VERSION ""

NS_ :

BS_:

BU_: MPAD CVADAS ADCAM ORC EVCU2 EPS ECM CVPAM CADM BSM2 BSM

BO_ 1456 ADAS_FD_HMI: 32 ADCAM
 SG_ RR_Chime_RqSts : 99|1@0+ (1,0) [0|1] "" ORC
 SG_ MessageCounter_ADAS_FD_HMI : 179|4@0+ (1,0) [0|15] "-"  EVCU2,BSM2,BSM,ORC,EPS,ECM
 SG_ LR_Chime_RqSts : 100|1@0+ (1,0) [0|1] "" ORC
 SG_ CRC_ADAS_FD_HMI : 191|8@0+ (1,0) [0|255] "-"  EVCU2,BSM2,BSM,ORC,EPS,ECM
 SG_ Chime_Priority : 91|3@0+ (1,0) [0|4] "-"  Vector__XXX
 SG_ BSS_SRV_RQSts : 88|1@0+ (1,0) [0|1] "" ORC
 SG_ BSS_Blind_RQSts : 101|1@0+ (1,0) [0|1] "" ORC
 SG_ BSS_CFG_STATSts : 103|2@0+ (1,0) [0|2] "" ORC
 SG_ SVI_Request : 31|2@0+ (1,0) [0|3] "-"  Vector__XXX
 SG_ Set_Speed_MPH : 15|8@0+ (1,0) [0|255] "mph"  EVCU2,ECM
 SG_ Set_Speed_KPH : 7|8@0+ (1,0) [0|255] "kph"  EVCU2,ORC,ECM
 SG_ RF_Chime_RqSts : 95|1@0+ (1,0) [0|1] "-"  ORC
 SG_ PEB_Setting_Avail : 78|1@0+ (1,0) [0|1] "-"  Vector__XXX
 SG_ NCC_FailSts : 82|1@0+ (1,0) [0|1] "-"  BSM,ORC
 SG_ LKA_Status : 23|1@0+ (1,0) [0|1] "-"  ORC
 SG_ LKA_FailSts : 84|1@0+ (1,0) [0|1] "-"  ORC
 SG_ LKA_Blind : 86|1@0+ (1,0) [0|1] "-"  ORC
 SG_ LF_Chime_RqSts : 93|1@0+ (1,0) [0|1] "-"  ORC
 SG_ Lane_DisplaySts_Right : 60|3@0+ (1,0) [0|7] "-"  ORC
 SG_ Lane_DisplaySts_Left : 71|3@0+ (1,0) [0|7] "-"  ORC
 SG_ ICA_Blind : 55|1@0+ (1,0) [0|1] "-"  Vector__XXX
 SG_ HAS_TurnSignalRequest : 111|2@0+ (1,0) [0|2] "" Vector__XXX
 SG_ HAS_TelltaleSts : 54|3@0+ (1,0) [0|6] "-"  ORC
 SG_ HAS_FailSts : 80|1@0+ (1,0) [0|1] "-"  ORC
 SG_ HAS_Escalation_Sts : 117|4@0+ (1,0) [0|8] "" Vector__XXX
 SG_ HAS_Blind : 85|1@0+ (1,0) [0|1] "-"  ORC
 SG_ FCW_Setting_Avail : 77|1@0+ (1,0) [0|1] "-"  Vector__XXX
 SG_ DisplaySts_Veh : 63|3@0+ (1,0) [0|7] "-"  Vector__XXX
 SG_ DisplaySts_OFF : 68|3@0+ (1,0) [0|7] "-"  Vector__XXX
 SG_ DisplaySts_Curve : 109|2@0+ (1,0) [0|2] "" Vector__XXX
 SG_ DisplaySts_ACC : 51|4@0+ (1,0) [0|15] "-"  ORC
 SG_ DDD_FailSts : 96|1@0+ (1,0) [0|1] "" Vector__XXX
 SG_ DDD_DispPopupSts : 39|2@0+ (1,0) [0|2] "-"  ORC
 SG_ Chime_TypSts : 47|4@0+ (1,0) [0|15] "-"  ORC
 SG_ Chime_RepRate : 43|4@0+ (1,0) [0|15] "Hz"  Vector__XXX
 SG_ BlindSpotRightWarn : 171|2@0+ (1,0) [0|2] "" ORC
 SG_ BlindSpotLeftWarn : 105|2@0+ (1,0) [0|2] "" ORC
 SG_ AEB_Limited : 72|1@0+ (1,0) [0|1] "-"  BSM,ORC
 SG_ AEB_Limit_Fail : 74|1@0+ (1,0) [0|1] "-"  ORC
 SG_ AEB_FailSts : 83|1@0+ (1,0) [0|1] "-"  BSM2,BSM,ORC
 SG_ AEB_DispPopupSts : 37|6@0+ (1,0) [0|63] "-"  ORC
 SG_ AEB_Blind : 76|1@0+ (1,0) [0|1] "-"  ORC
 SG_ ACC_Set_Speed_Strike : 92|1@0+ (1,0) [0|1] "-"  Vector__XXX
 SG_ ACC_Limited : 87|1@0+ (1,0) [0|1] "-"  ORC
 SG_ ACC_Limit_Fail : 73|1@0+ (1,0) [0|1] "-"  ORC
 SG_ ACC_FailSts : 81|1@0+ (1,0) [0|1] "-"  EVCU2,BSM,ORC
 SG_ ACC_DispPopupSts : 22|7@0+ (1,0) [0|127] "-"  ORC
 SG_ ACC_Blind : 75|1@0+ (1,0) [0|1] "-"  EVCU2,BSM,ORC
 SG_ Driver_Model : 107|2@0+ (1,0) [0|3] "" ORC
 SG_ Lane_DispPopupSts : 127|8@0+ (1,0) [0|255] "-"  ORC
 SG_ SVI_Request_ext : 29|3@0+ (1,0) [0|7] "-"  Vector__XXX
 SG_ DM_Camera_Block : 112|1@0+ (1,0) [0|1] "-"  Vector__XXX
 SG_ HAS_TelltaleSts_ext : 157|3@0+ (1,0) [0|7] "" Vector__XXX
 SG_ DisplaySts_Route : 154|3@0+ (1,0) [0|7] "" Vector__XXX

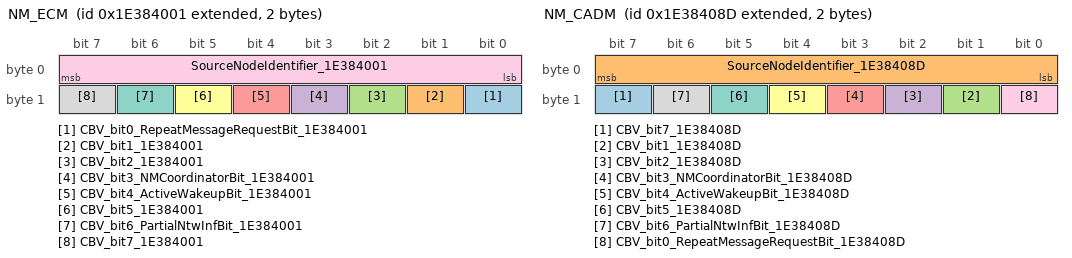
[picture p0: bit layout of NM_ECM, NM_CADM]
BO_ 2654486529 NM_ECM: 2 ECM
 SG_ CBV_bit0_RepeatMessageRequestBit_1E384001 : 8|1@0+ (1,0) [0|1] "" CVADAS,ADCAM,EVCU2,BSM2,CVPAM,CADM,BSM,ORC,EPS
 SG_ CBV_bit1_1E384001 : 9|1@0+ (1,0) [0|1] "" CVADAS,ADCAM,EVCU2,BSM2,CVPAM,CADM,BSM,ORC,EPS
 SG_ CBV_bit2_1E384001 : 10|1@0+ (1,0) [0|1] "" CVADAS,ADCAM,EVCU2,BSM2,CVPAM,CADM,BSM,ORC,EPS
 SG_ CBV_bit3_NMCoordinatorBit_1E384001 : 11|1@0+ (1,0) [0|1] "" CVADAS,ADCAM,EVCU2,BSM2,CVPAM,CADM,BSM,ORC,EPS
 SG_ CBV_bit4_ActiveWakeupBit_1E384001 : 12|1@0+ (1,0) [0|1] "" CVADAS,ADCAM,EVCU2,BSM2,CVPAM,CADM,BSM,ORC,EPS
 SG_ CBV_bit5_1E384001 : 13|1@0+ (1,0) [0|1] "" CVADAS,ADCAM,EVCU2,BSM2,CVPAM,CADM,BSM,ORC,EPS
 SG_ CBV_bit6_PartialNtwInfBit_1E384001 : 14|1@0+ (1,0) [0|1] "" CVADAS,ADCAM,EVCU2,BSM2,CVPAM,CADM,BSM,ORC,EPS
 SG_ CBV_bit7_1E384001 : 15|1@0+ (1,0) [0|1] "" CVADAS,ADCAM,EVCU2,BSM2,CVPAM,CADM,BSM,ORC,EPS
 SG_ SourceNodeIdentifier_1E384001 : 7|8@0+ (1,0) [0|255] "-"  CVADAS,ADCAM,EVCU2,BSM2,CVPAM,CADM,BSM,ORC,EPS

BO_ 2654486669 NM_CADM: 2 CADM
 SG_ CBV_bit7_1E38408D : 15|1@0+ (1,0) [0|1] "" CVADAS,EVCU2,BSM2,CVPAM,BSM,ORC,EPS,ECM
 SG_ SourceNodeIdentifier_1E38408D : 7|8@0+ (1,0) [0|255] "-"  CVADAS,EVCU2,BSM2,CVPAM,BSM,ORC,EPS,ECM
 SG_ CBV_bit1_1E38408D : 9|1@0+ (1,0) [0|1] "" CVADAS,EVCU2,BSM2,CVPAM,BSM,ORC,EPS,ECM
 SG_ CBV_bit2_1E38408D : 10|1@0+ (1,0) [0|1] "" CVADAS,EVCU2,BSM2,CVPAM,BSM,ORC,EPS,ECM
 SG_ CBV_bit3_NMCoordinatorBit_1E38408D : 11|1@0+ (1,0) [0|1] "" CVADAS,EVCU2,BSM2,CVPAM,BSM,ORC,EPS,ECM
 SG_ CBV_bit4_ActiveWakeupBit_1E38408D : 12|1@0+ (1,0) [0|1] "" CVADAS,EVCU2,BSM2,CVPAM,BSM,ORC,EPS,ECM
 SG_ CBV_bit5_1E38408D : 13|1@0+ (1,0) [0|1] "" CVADAS,EVCU2,BSM2,CVPAM,BSM,ORC,EPS,ECM
 SG_ CBV_bit6_PartialNtwInfBit_1E38408D : 14|1@0+ (1,0) [0|1] "" CVADAS,EVCU2,BSM2,CVPAM,BSM,ORC,EPS,ECM
 SG_ CBV_bit0_RepeatMessageRequestBit_1E38408D : 8|1@0+ (1,0) [0|1] "" CVADAS,EVCU2,BSM2,CVPAM,BSM,ORC,EPS,ECM

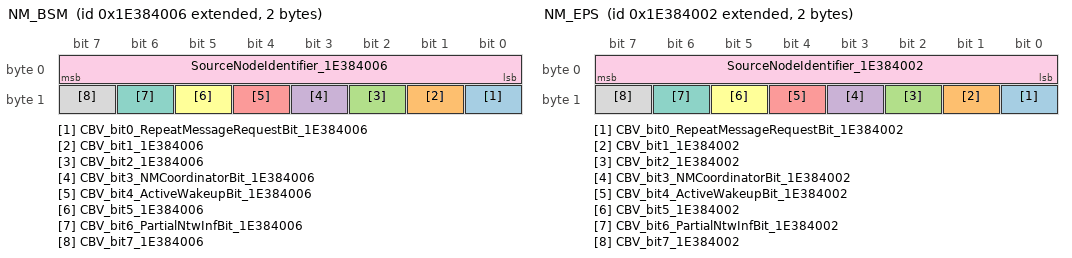
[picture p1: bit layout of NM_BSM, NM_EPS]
BO_ 2654486534 NM_BSM: 2 BSM
 SG_ CBV_bit0_RepeatMessageRequestBit_1E384006 : 8|1@0+ (1,0) [0|1] "" CVPAM,CADM,ORC,EPS,CVADAS,ADCAM,MPAD,EVCU2,BSM2,ECM
 SG_ CBV_bit1_1E384006 : 9|1@0+ (1,0) [0|1] "" CVPAM,CADM,ORC,EPS,CVADAS,ADCAM,MPAD,EVCU2,BSM2,ECM
 SG_ CBV_bit2_1E384006 : 10|1@0+ (1,0) [0|1] "" CVPAM,CADM,ORC,EPS,CVADAS,ADCAM,MPAD,EVCU2,BSM2,ECM
 SG_ CBV_bit3_NMCoordinatorBit_1E384006 : 11|1@0+ (1,0) [0|1] "" CVPAM,CADM,ORC,EPS,CVADAS,ADCAM,MPAD,EVCU2,BSM2,ECM
 SG_ CBV_bit4_ActiveWakeupBit_1E384006 : 12|1@0+ (1,0) [0|1] "" CVPAM,CADM,ORC,EPS,CVADAS,ADCAM,MPAD,EVCU2,BSM2,ECM
 SG_ CBV_bit5_1E384006 : 13|1@0+ (1,0) [0|1] "" CVPAM,CADM,ORC,EPS,CVADAS,ADCAM,MPAD,EVCU2,BSM2,ECM
 SG_ CBV_bit6_PartialNtwInfBit_1E384006 : 14|1@0+ (1,0) [0|1] "" CVPAM,CADM,ORC,EPS,CVADAS,ADCAM,MPAD,EVCU2,BSM2,ECM
 SG_ CBV_bit7_1E384006 : 15|1@0+ (1,0) [0|1] "" CVPAM,CADM,ORC,EPS,CVADAS,ADCAM,MPAD,EVCU2,BSM2,ECM
 SG_ SourceNodeIdentifier_1E384006 : 7|8@0+ (1,0) [0|255] "-"  CVPAM,CADM,ORC,EPS,CVADAS,ADCAM,MPAD,EVCU2,BSM2,ECM

BO_ 262 ENGINE_FD_2: 64 ECM
 SG_ PowertrainPrplsnActv : 181|1@0+ (1,0) [0|1] "" ADCAM,CADM,BSM
 SG_ MessageCounter_ENGINE2 : 435|4@0+ (1,0) [0|15] "-"  CVADAS,ADCAM,CVPAM,CADM,BSM,EPS
 SG_ LV12PwrFreeRq_W : 176|1@0+ (1,0) [0|1] "-"  Vector__XXX
 SG_ GasPedalPositionFailSts_W : 169|1@0+ (1,0) [0|1] "-"  ADCAM,CADM,BSM
 SG_ GasPedalPosition_W : 143|8@0+ (0.392,0) [0|99.568] "%"  ADCAM,BSM
 SG_ ESS_ENG_ST_W : 175|4@0+ (1,0) [0|15] "-"  CVADAS,ADCAM,CADM,BSM,EPS
 SG_ EngineSts_W : 87|2@0+ (1,0) [0|3] "-"  CVADAS,ADCAM,CVPAM,CADM,BSM,EPS
 SG_ EngineSpeed_W : 21|14@0+ (1,0) [0|16382] "1/min"  ADCAM,CADM,BSM,EPS
 SG_ ECM_LHOM_W : 188|1@0+ (1,0) [0|1] "-"  ADCAM,CADM
 SG_ CRC_ENGINE2 : 447|8@0+ (1,0) [0|255] "-"  CVADAS,ADCAM,CVPAM,CADM,BSM,EPS

BO_ 258 BRAKE_FD_2: 64 BSM
 SG_ YawRateFailSts_BSM : 87|1@0+ (1,0) [0|1] "-"  CVADAS,ADCAM,MPAD,CVPAM,CADM,EPS
 SG_ YawRate_BSM : 67|12@0+ (0.08,-163.84) [-163.84|163.68] "deg/s"  CVADAS,ADCAM,MPAD,CVPAM,CADM,EPS
 SG_ VehicleSpeedVSOSig : 4|13@0+ (0.0625,0) [0|511.875] "Km/h"  CVADAS,ADCAM,MPAD,EVCU2,BSM2,CVPAM,CADM,EPS,ECM
 SG_ Slope : 135|8@0+ (1,-100) [-100|154] "%"  CVADAS,MPAD,EVCU2,CVPAM,CADM
 SG_ PrefillActive : 86|1@0+ (1,0) [0|1] "-"  ADCAM,MPAD,CADM
 SG_ MessageCounter_BRAKE2 : 435|4@0+ (1,0) [0|15] "-"  CVADAS,ADCAM,EVCU2,BSM2,CVPAM,CADM,EPS,ECM
 SG_ LongAccelerationFailSts_BSM : 69|1@0+ (1,0) [0|1] "-"  CVADAS,ADCAM,MPAD,CVPAM,CADM
 SG_ LongAcceleration_BSM : 35|12@0+ (0.02,-40.96) [-40.96|40.92] "m/s^2"  CVADAS,ADCAM,MPAD,CVPAM,CADM,EPS
 SG_ LatAccelerationFailSts_BSM : 68|1@0+ (1,0) [0|1] "-"  CVADAS,ADCAM,MPAD,CVPAM,CADM
 SG_ LatAcceleration_BSM : 19|12@0+ (0.02,-40.96) [-40.96|40.92] "m/s^2"  CVADAS,ADCAM,MPAD,CVPAM,CADM,EPS
 SG_ InternalError_BSM : 191|1@0+ (1,0) [0|1] "-"  ADCAM,MPAD,CADM
 SG_ ESP_Sys_Stat : 71|2@0+ (1,0) [0|3] "-"  Vector__XXX
 SG_ ESCActive : 84|1@0+ (1,0) [0|1] "-"  MPAD,EVCU2,CVPAM,CADM
 SG_ CRC_BRAKE2 : 447|8@0+ (1,0) [0|255] "-"  CVADAS,ADCAM,EVCU2,BSM2,CVPAM,CADM,EPS,ECM
 SG_ BrakePedalPressure : 386|11@0+ (0.1,0) [0|200] "bar"  EVCU2,ECM
 SG_ BrakeInterventionSts : 103|1@0+ (1,0) [0|1] "-"  ADCAM,MPAD,BSM2,CADM
 SG_ BrakeBoostStat : 439|4@0+ (1,0) [0|14] "-"  Vector__XXX
 SG_ BrakeBoostPressure : 370|11@0+ (0.1,0) [0|200] "bar"  EVCU2,ECM
 SG_ ABSActive : 83|1@0+ (1,0) [0|1] "-"  MPAD,EVCU2,CVPAM,CADM,ECM
 SG_ WheelRPM_FR : 295|16@0+ (0.001953125,0) [0|127.9961] "Rev/s"  MPAD,EVCU2,EPS
 SG_ WheelRPM_FL : 279|16@0+ (0.001953125,0) [0|127.9961] "Rev/s"  MPAD,EVCU2,EPS
 SG_ Brk_Stat : 343|2@0+ (1,0) [0|2] "-"  CVADAS,ADCAM,MPAD,EVCU2,CVPAM,CADM,ECM
 SG_ ParkingGearShiftReq_BSM : 22|3@0+ (1,0) [0|6] "" CVADAS,CVPAM
 SG_ ParkingInterventionSts : 7|2@0+ (1,0) [0|3] "" CVADAS,CVPAM
 SG_ BSM_ESASystemSts : 239|3@0+ (1,0) [0|6] "" CADM,EPS

BO_ 2654486530 NM_EPS: 2 EPS
 SG_ CBV_bit0_RepeatMessageRequestBit_1E384002 : 8|1@0+ (1,0) [0|1] "" CVADAS,ADCAM,MPAD,EVCU2,BSM2,CVPAM,CADM,BSM,ORC,ECM
 SG_ CBV_bit1_1E384002 : 9|1@0+ (1,0) [0|1] "" CVADAS,ADCAM,MPAD,EVCU2,BSM2,CVPAM,CADM,BSM,ORC,ECM
 SG_ CBV_bit2_1E384002 : 10|1@0+ (1,0) [0|1] "" CVADAS,ADCAM,MPAD,EVCU2,BSM2,CVPAM,CADM,BSM,ORC,ECM
 SG_ CBV_bit3_NMCoordinatorBit_1E384002 : 11|1@0+ (1,0) [0|1] "" CVADAS,ADCAM,MPAD,EVCU2,BSM2,CVPAM,CADM,BSM,ORC,ECM
 SG_ CBV_bit4_ActiveWakeupBit_1E384002 : 12|1@0+ (1,0) [0|1] "" CVADAS,ADCAM,MPAD,EVCU2,BSM2,CVPAM,CADM,BSM,ORC,ECM
 SG_ CBV_bit5_1E384002 : 13|1@0+ (1,0) [0|1] "" CVADAS,ADCAM,MPAD,EVCU2,BSM2,CVPAM,CADM,BSM,ORC,ECM
 SG_ CBV_bit6_PartialNtwInfBit_1E384002 : 14|1@0+ (1,0) [0|1] "" CVADAS,ADCAM,MPAD,EVCU2,BSM2,CVPAM,CADM,BSM,ORC,ECM
 SG_ CBV_bit7_1E384002 : 15|1@0+ (1,0) [0|1] "" CVADAS,ADCAM,MPAD,EVCU2,BSM2,CVPAM,CADM,BSM,ORC,ECM
 SG_ SourceNodeIdentifier_1E384002 : 7|8@0+ (1,0) [0|255] "-"  CVADAS,ADCAM,MPAD,EVCU2,BSM2,CVPAM,CADM,BSM,ORC,ECM

BO_ 524 BRAKE2_FD_2: 32 BSM2
 SG_ VehicleStandStillSts_B2 : 47|2@0+ (1,0) [0|2] "" ADCAM,MPAD,CADM,BSM
 SG_ BSM2_OpStat : 50|3@0+ (1,0) [0|5] "" ADCAM,MPAD,CADM,BSM
 SG_ Brake_OpStat_Sec : 53|3@0+ (1,0) [0|5] "" MPAD,CADM
 SG_ MessageCounter_BRAKE2_2 : 179|4@0+ (1,0) [0|15] "-"  MPAD,CADM,BSM,ORC
 SG_ CRC_BRAKE2_2 : 191|8@0+ (1,0) [0|255] "-"  MPAD,CADM,BSM,ORC
 SG_ BrkTrq_B2 : 6|15@0+ (3,0) [0|98301] "Nm"  ADCAM,MPAD,CADM
 SG_ BSM2_HEALTH_CHECK : 63|8@0+ (1,0) [0|255] "" BSM
 SG_ AEB_Type_Brk_B2 : 43|4@0+ (1,0) [0|15] "" ADCAM,MPAD,CADM

BO_ 257 BRAKE2_FD_1: 64 BSM2
 SG_ VehicleSpeedVSOSig_B2 : 36|13@0+ (0.0625,0) [0|511.875] "Km/h"  CVADAS,ADCAM,MPAD,CVPAM,CADM,EPS
 SG_ RHFWheelSpeed_B2 : 68|13@0+ (0.0625,0) [0|511.875] "Km/h"  ADCAM,MPAD,CADM
 SG_ RHF_FastPulseCounter_B2 : 95|8@0+ (1,0) [0|255] "pulse"  ADCAM,MPAD,CADM
 SG_ LHFWheelSpeed_B2 : 52|13@0+ (0.0625,0) [0|511.875] "Km/h"  ADCAM,MPAD,CADM
 SG_ LHF_FastPulseCounter_B2 : 87|8@0+ (1,0) [0|255] "pulse"  ADCAM,MPAD,CADM
 SG_ RHF_WheelSensorFailSts_B2 : 69|1@0+ (1,0) [0|1] "" ADCAM,MPAD,CADM
 SG_ RHF_Spin_B2 : 55|2@0+ (1,0) [0|3] "" ADCAM,MPAD,CADM
 SG_ MessageCounter_BRAKE2_1 : 435|4@0+ (1,0) [0|15] "-"  CVADAS,CADM,ORC,EPS
 SG_ LHF_WheelSensorFailSts_B2 : 53|1@0+ (1,0) [0|1] "" ADCAM,MPAD,CADM
 SG_ LHF_Spin_B2 : 39|2@0+ (1,0) [0|3] "" ADCAM,MPAD,CADM
 SG_ Inlet_Pressure_Pos : 98|2@0+ (1,0) [0|2] "" ADCAM,MPAD,CADM
 SG_ CRC_BRAKE2_1 : 447|8@0+ (1,0) [0|255] "-"  CVADAS,CADM,ORC,EPS
 SG_ Brk_Stat_B2 : 71|2@0+ (1,0) [0|2] "" ADCAM,MPAD,CADM
 SG_ ABSActive_B2 : 37|1@0+ (1,0) [0|1] "" MPAD,CADM
 SG_ Rear_Diff_BSM_RQ_B2 : 156|2@0+ (1,0) [0|2] "-"  Vector__XXX
 SG_ R_DIFF_TRQ_RQ_B2 : 151|9@0+ (10,0) [0|5100] "Nm"  Vector__XXX
 SG_ Ft_RrTrqCoupling_ModeRq_B2 : 158|2@0+ (1,0) [0|3] "-"  Vector__XXX
 SG_ Ft_RrAxleCoupling_TrqRq_B2 : 143|8@0+ (12,0) [0|3060] "Nm"  Vector__XXX

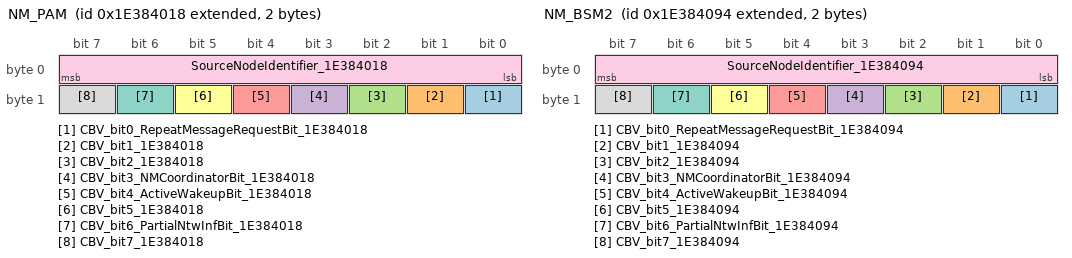
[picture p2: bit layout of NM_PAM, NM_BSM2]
BO_ 2654486552 NM_PAM: 2 CVADAS
 SG_ CBV_bit0_RepeatMessageRequestBit_1E384018 : 8|1@0+ (1,0) [0|1] "" ADCAM,MPAD,EVCU2,BSM2,CADM,BSM,ORC,EPS,ECM
 SG_ CBV_bit1_1E384018 : 9|1@0+ (1,0) [0|1] "" ADCAM,MPAD,EVCU2,BSM2,CADM,BSM,ORC,EPS,ECM
 SG_ CBV_bit2_1E384018 : 10|1@0+ (1,0) [0|1] "" ADCAM,MPAD,EVCU2,BSM2,CADM,BSM,ORC,EPS,ECM
 SG_ CBV_bit3_NMCoordinatorBit_1E384018 : 11|1@0+ (1,0) [0|1] "" ADCAM,MPAD,EVCU2,BSM2,CADM,BSM,ORC,EPS,ECM
 SG_ CBV_bit4_ActiveWakeupBit_1E384018 : 12|1@0+ (1,0) [0|1] "" ADCAM,MPAD,EVCU2,BSM2,CADM,BSM,ORC,EPS,ECM
 SG_ CBV_bit5_1E384018 : 13|1@0+ (1,0) [0|1] "" ADCAM,MPAD,EVCU2,BSM2,CADM,BSM,ORC,EPS,ECM
 SG_ CBV_bit6_PartialNtwInfBit_1E384018 : 14|1@0+ (1,0) [0|1] "" ADCAM,MPAD,EVCU2,BSM2,CADM,BSM,ORC,EPS,ECM
 SG_ CBV_bit7_1E384018 : 15|1@0+ (1,0) [0|1] "" ADCAM,MPAD,EVCU2,BSM2,CADM,BSM,ORC,EPS,ECM
 SG_ SourceNodeIdentifier_1E384018 : 7|8@0+ (1,0) [0|255] "-"  ADCAM,MPAD,EVCU2,BSM2,CADM,BSM,ORC,EPS,ECM

BO_ 2654486676 NM_BSM2: 2 BSM2
 SG_ CBV_bit0_RepeatMessageRequestBit_1E384094 : 8|1@0+ (1,0) [0|1] "" CVADAS,ADCAM,MPAD,EVCU2,CVPAM,CADM,BSM,ORC,EPS,ECM
 SG_ CBV_bit1_1E384094 : 9|1@0+ (1,0) [0|1] "" CVADAS,ADCAM,MPAD,EVCU2,CVPAM,CADM,BSM,ORC,EPS,ECM
 SG_ CBV_bit2_1E384094 : 10|1@0+ (1,0) [0|1] "" CVADAS,ADCAM,MPAD,EVCU2,CVPAM,CADM,BSM,ORC,EPS,ECM
 SG_ CBV_bit3_NMCoordinatorBit_1E384094 : 11|1@0+ (1,0) [0|1] "" CVADAS,ADCAM,MPAD,EVCU2,CVPAM,CADM,BSM,ORC,EPS,ECM
 SG_ CBV_bit4_ActiveWakeupBit_1E384094 : 12|1@0+ (1,0) [0|1] "" CVADAS,ADCAM,MPAD,EVCU2,CVPAM,CADM,BSM,ORC,EPS,ECM
 SG_ CBV_bit5_1E384094 : 13|1@0+ (1,0) [0|1] "" CVADAS,ADCAM,MPAD,EVCU2,CVPAM,CADM,BSM,ORC,EPS,ECM
 SG_ CBV_bit6_PartialNtwInfBit_1E384094 : 14|1@0+ (1,0) [0|1] "" CVADAS,ADCAM,MPAD,EVCU2,CVPAM,CADM,BSM,ORC,EPS,ECM
 SG_ CBV_bit7_1E384094 : 15|1@0+ (1,0) [0|1] "" CVADAS,ADCAM,MPAD,EVCU2,CVPAM,CADM,BSM,ORC,EPS,ECM
 SG_ SourceNodeIdentifier_1E384094 : 7|8@0+ (1,0) [0|255] "-"  CVADAS,ADCAM,MPAD,EVCU2,CVPAM,CADM,BSM,ORC,EPS,ECM

BO_TX_BU_ 1456 : ADCAM,MPAD,CADM;
BO_TX_BU_ 2654486552 : CVADAS,CVPAM;
CM_ SG_ 1456 RR_Chime_RqSts "BSM right rear chime on request";
CM_ SG_ 1456 MessageCounter_ADAS_FD_HMI "This signal is a counter used for safety checks strategies. This counter is incremented of 1 (one) unit at each frame transmission.";
CM_ SG_ 1456 LR_Chime_RqSts "BSM Left rear chime on request";
CM_ SG_ 1456 CRC_ADAS_FD_HMI "CRC according to SAE J1850 standard at each frame transmission.";
CM_ SG_ 1456 Chime_Priority "Chime Priority";
CM_ SG_ 1456 BSS_SRV_RQSts "BSS service warning request";
CM_ SG_ 1456 BSS_Blind_RQSts "Sensor blinded request from BSS";
CM_ SG_ 262 PowertrainPrplsnActv "Powertrain Propulsion Status.";
CM_ SG_ 262 MessageCounter_ENGINE2 "This signal is a counter used for safety checks strategies. This counter is incremented of 1 (one) unit at each frame transmission.";
CM_ SG_ 262 LV12PwrFreeRq_W "-";
CM_ SG_ 262 GasPedalPositionFailSts_W "-";
CM_ SG_ 262 GasPedalPosition_W "-";
CM_ SG_ 262 ESS_ENG_ST_W "ESS Engine State";
CM_ SG_ 262 EngineSts_W "-";
CM_ SG_ 262 EngineSpeed_W "It gives information on C-CAN network about  engine speed";
CM_ SG_ 262 ECM_LHOM_W "-";
CM_ SG_ 262 CRC_ENGINE2 "CRC according to SAE J1850 standard at each frame transmission.";
CM_ SG_ 258 YawRateFailSts_BSM "This signal indicates the Status of Yaw Rate Signal";
CM_ SG_ 258 YawRate_BSM "This signal indicates the Yaw Rate Value";
CM_ SG_ 258 VehicleSpeedVSOSig "It is the average vehicle speed calculated.";
CM_ SG_ 258 Slope "Slope value detected by BSM";
CM_ SG_ 258 PrefillActive "This signal indicates the prefill function status.";
CM_ SG_ 258 MessageCounter_BRAKE2 "This signal is a counter used for safety checks strategies. This counter is incremented of 1 (one) unit at each frame transmission.";
CM_ SG_ 258 LongAccelerationFailSts_BSM "This signal indicates the status of Longitudinal acceleration signal";
CM_ SG_ 258 LongAcceleration_BSM "This signal indicates the Longitudinal Acceleration Value";
CM_ SG_ 258 LatAccelerationFailSts_BSM "This signal indicates the status of Lateral Acceleration Signal";
CM_ SG_ 258 LatAcceleration_BSM "This signal indicates the Lateral Acceleration Value";
CM_ SG_ 258 InternalError_BSM "This signal indicates if an internal error has been processed";
CM_ SG_ 258 ESP_Sys_Stat "0";
CM_ SG_ 258 ESCActive "This signal is set to Active when the brake intervention by ESC is active.";
CM_ SG_ 258 CRC_BRAKE2 "CRC according to SAE J1850 standard at each frame transmission.";
CM_ SG_ 258 BrakePedalPressure "Pressure Information from Brake Pedal Simulator Pressure Sensor";
CM_ SG_ 258 BrakeInterventionSts "This signal is ?active? when the brake intervention is due to BSM events and ?not active? when the brake intervention is due to the driver";
CM_ SG_ 258 BrakeBoostStat "eBoost System Status INIT, eBOOST, PUSH-THROUGH, SNA";
CM_ SG_ 258 BrakeBoostPressure "Pressure Information from Brake Booster Pressure Sensor";
CM_ SG_ 258 ABSActive "This signal is set to Active when the ABS functionality is active.";
CM_ SG_ 1456 BSS_CFG_STATSts "Blind Spot configuration status";
CM_ SG_ 524 VehicleStandStillSts_B2 "VehicleStandStillSts_B2";
CM_ SG_ 524 BSM2_OpStat "Capability of the secondary brake control module to provide deceleration and/or stability control";
CM_ SG_ 524 Brake_OpStat_Sec "Capability of the Braking system to perform deceleration and/or stability control as reported by the secondary actuator.";
CM_ SG_ 257 VehicleSpeedVSOSig_B2 "VehicleSpeedVSOSig_B2";
CM_ SG_ 257 RHFWheelSpeed_B2 "RHFWheelSpeed_B2";
CM_ SG_ 257 RHF_FastPulseCounter_B2 "RHF_FastPulseCounter_B2";
CM_ SG_ 257 LHFWheelSpeed_B2 "LHFWheelSpeed_B2";
CM_ SG_ 257 LHF_FastPulseCounter_B2 "LHF_FastPulseCounter_B2";
CM_ SG_ 258 WheelRPM_FR "Wheel RPM front right";
CM_ SG_ 258 WheelRPM_FL "Wheel RPM front left";
CM_ SG_ 258 Brk_Stat "Brake state";
CM_ SG_ 1456 SVI_Request "Request to activate Secondary Visual Indication";
CM_ SG_ 1456 Set_Speed_MPH "Speed shown by IPC, which ACC is controlling in MPH";
CM_ SG_ 1456 Set_Speed_KPH "Speed shown by IPC, which ACC is controlling in KPH";
CM_ SG_ 1456 RF_Chime_RqSts "DASM_RF_Chime_RqSts";
CM_ SG_ 1456 PEB_Setting_Avail "PEB setting availability";
CM_ SG_ 1456 NCC_FailSts "NCC_FailSts";
CM_ SG_ 1456 LKA_Status "None";
CM_ SG_ 1456 LKA_FailSts "LKA_FailSts";
CM_ SG_ 1456 LKA_Blind "LKA_Blind";
CM_ SG_ 1456 LF_Chime_RqSts "DASM_LF_Chime_RqSts";
CM_ SG_ 1456 Lane_DisplaySts_Right "Lane Display Status Right";
CM_ SG_ 1456 Lane_DisplaySts_Left "Lane Display Status Left";
CM_ SG_ 1456 ICA_Blind "This signal is used to indicate the presence of an occlusion of the ICA feature";
CM_ SG_ 1456 HAS_TurnSignalRequest "Request from the primary controller to actuate the turn signals";
CM_ SG_ 1456 HAS_TelltaleSts "Highway Assist telltale status in cluster";
CM_ SG_ 1456 HAS_FailSts "HAS_FailSts";
CM_ SG_ 1456 HAS_Escalation_Sts "HAS_Escalation_Sts";
CM_ SG_ 1456 HAS_Blind "HAS_Blind";
CM_ SG_ 1456 FCW_Setting_Avail "FCW setting availability";
CM_ SG_ 1456 DisplaySts_Veh "Display Status Veh";
CM_ SG_ 1456 DisplaySts_OFF "Display Status Off";
CM_ SG_ 1456 DisplaySts_Curve "Indication that Curve Speed Control is reducing vehicle target speed in response to tight curve";
CM_ SG_ 1456 DisplaySts_ACC "Display status ACC";
CM_ SG_ 1456 DDD_FailSts "DDD Fail Sts CADM2";
CM_ SG_ 1456 DDD_DispPopupSts "DDD Disp Pop Up";
CM_ SG_ 1456 Chime_TypSts "DASM Chime Type Status";
CM_ SG_ 1456 Chime_RepRate "DASM Chime Repetition Rate";
CM_ SG_ 1456 BlindSpotRightWarn "BlindSpotRightWarn";
CM_ SG_ 1456 BlindSpotLeftWarn "BlindSpotLeftWarn";
CM_ SG_ 1456 AEB_Limited "AEB_Limited";
CM_ SG_ 1456 AEB_Limit_Fail "AEB_Limit_Fail";
CM_ SG_ 1456 AEB_FailSts "AEB_FailSts";
CM_ SG_ 1456 AEB_DispPopupSts "AEB Dips Pop Up";
CM_ SG_ 1456 AEB_Blind "AEB_Blind";
CM_ SG_ 1456 ACC_Set_Speed_Strike "ACC Set Speed Strike";
CM_ SG_ 1456 ACC_Limited "ACC_Limited";
CM_ SG_ 1456 ACC_Limit_Fail "ACC_Limit_Fail";
CM_ SG_ 1456 ACC_FailSts "ACC_FailSts";
CM_ SG_ 1456 ACC_DispPopupSts "ACC Dips Pop Up";
CM_ SG_ 1456 ACC_Blind "ACC_Blind";
CM_ SG_ 258 ParkingGearShiftReq_BSM "CVPAM Request to autonomously shift gears";
CM_ SG_ 524 MessageCounter_BRAKE2_2 "This signal is a counter used for safety checks strategies. This counter is incremented of 1 (one) unit at each frame transmission.";
CM_ SG_ 524 CRC_BRAKE2_2 "CRC according to SAE J1850 standard at each frame transmission.";
CM_ SG_ 524 BrkTrq_B2 "BrkTrq_B2";
CM_ SG_ 257 RHF_WheelSensorFailSts_B2 "RHF_WheelSensorFailSts_B2";
CM_ SG_ 257 RHF_Spin_B2 "RHF_Spin_B2";
CM_ SG_ 257 MessageCounter_BRAKE2_1 "This signal is a counter used for safety checks strategies. This counter is incremented of 1 (one) unit at each frame transmission.";
CM_ SG_ 257 LHF_WheelSensorFailSts_B2 "LHF_WheelSensorFailSts_B2";
CM_ SG_ 257 LHF_Spin_B2 "LHF_Spin_B2";
CM_ SG_ 257 Inlet_Pressure_Pos "Inlet Pressure Pos Indicates if the secondary brake control module detects upstream brake pressure";
CM_ SG_ 257 CRC_BRAKE2_1 "CRC according to SAE J1850 standard at each frame transmission.";
CM_ SG_ 257 Brk_Stat_B2 "Signifies a general braking event (both autonomous and driver requested) with the secondary brake control module";
CM_ SG_ 257 ABSActive_B2 "ABSActive_B2";
CM_ SG_ 1456 Driver_Model "Overall assessment of whether driver is attentive to the driving task according to driver model";
CM_ SG_ 524 BSM2_HEALTH_CHECK "BSM2_HEALTH_CHECK";
CM_ SG_ 258 ParkingInterventionSts "Current status of BSM during Autonomous Parking Maneuver";
CM_ SG_ 524 AEB_Type_Brk_B2 "AEB_Type_Brk_B2";
CM_ SG_ 2654486529 CBV_bit0_RepeatMessageRequestBit_1E384001 "Repeat Message Request Bit";
CM_ SG_ 2654486529 CBV_bit3_NMCoordinatorBit_1E384001 "NM Coordinator Sleep Bit";
CM_ SG_ 2654486529 CBV_bit4_ActiveWakeupBit_1E384001 "Active Wakeup Bit";
CM_ SG_ 2654486529 CBV_bit6_PartialNtwInfBit_1E384001 "Partial Network Information Bit (PNI)";
CM_ SG_ 2654486529 SourceNodeIdentifier_1E384001 "Source Node Identifier";
CM_ SG_ 2654486669 SourceNodeIdentifier_1E38408D "Source Node Identifier";
CM_ SG_ 2654486669 CBV_bit3_NMCoordinatorBit_1E38408D "NM Coordinator Sleep Bit";
CM_ SG_ 2654486669 CBV_bit4_ActiveWakeupBit_1E38408D "Active Wakeup Bit";
CM_ SG_ 2654486669 CBV_bit6_PartialNtwInfBit_1E38408D "Partial Network Information Bit (PNI)";
CM_ SG_ 2654486669 CBV_bit0_RepeatMessageRequestBit_1E38408D "Repeat Message Request Bit";
CM_ SG_ 2654486534 CBV_bit0_RepeatMessageRequestBit_1E384006 "Repeat Message Request Bit";
CM_ SG_ 2654486534 CBV_bit3_NMCoordinatorBit_1E384006 "NM Coordinator Sleep Bit";
CM_ SG_ 2654486534 CBV_bit4_ActiveWakeupBit_1E384006 "Active Wakeup Bit";
CM_ SG_ 2654486534 CBV_bit6_PartialNtwInfBit_1E384006 "Partial Network Information Bit (PNI)";
CM_ SG_ 2654486534 SourceNodeIdentifier_1E384006 "Source Node Identifier";
CM_ SG_ 257 Rear_Diff_BSM_RQ_B2 "ESP Requested Rear Differential State";
CM_ SG_ 257 R_DIFF_TRQ_RQ_B2 "Desired Torque for Rear Diff.";
CM_ SG_ 257 Ft_RrTrqCoupling_ModeRq_B2 "ESP Requested Center Differential State";
CM_ SG_ 257 Ft_RrAxleCoupling_TrqRq_B2 "Desired Torque for Center Diff";
CM_ SG_ 1456 Lane_DispPopupSts "Lane Management Pop-up Messages.TEXT MSG n corresponds to a raw value of 'n'";
CM_ SG_ 258 BSM_ESASystemSts "Brake System ESA Status";
CM_ SG_ 2654486552 CBV_bit0_RepeatMessageRequestBit_1E384018 "Repeat Message Request Bit";
CM_ SG_ 2654486552 CBV_bit3_NMCoordinatorBit_1E384018 "NM Coordinator Sleep Bit";
CM_ SG_ 2654486552 CBV_bit4_ActiveWakeupBit_1E384018 "Active Wakeup Bit";
CM_ SG_ 2654486552 CBV_bit6_PartialNtwInfBit_1E384018 "Partial Network Information Bit (PNI)";
CM_ SG_ 2654486552 SourceNodeIdentifier_1E384018 "Source Node Identifier";
CM_ SG_ 2654486530 CBV_bit0_RepeatMessageRequestBit_1E384002 "Repeat Message Request Bit";
CM_ SG_ 2654486530 CBV_bit3_NMCoordinatorBit_1E384002 "NM Coordinator Sleep Bit";
CM_ SG_ 2654486530 CBV_bit4_ActiveWakeupBit_1E384002 "Active Wakeup Bit";
CM_ SG_ 2654486530 CBV_bit6_PartialNtwInfBit_1E384002 "Partial Network Information Bit (PNI)";
CM_ SG_ 2654486530 SourceNodeIdentifier_1E384002 "Source Node Identifier";
CM_ SG_ 2654486676 CBV_bit0_RepeatMessageRequestBit_1E384094 "Repeat Message Request Bit";
CM_ SG_ 2654486676 CBV_bit3_NMCoordinatorBit_1E384094 "NM Coordinator Sleep Bit";
CM_ SG_ 2654486676 CBV_bit4_ActiveWakeupBit_1E384094 "Active Wakeup Bit";
CM_ SG_ 2654486676 CBV_bit6_PartialNtwInfBit_1E384094 "Partial Network Information Bit (PNI)";
CM_ SG_ 2654486676 SourceNodeIdentifier_1E384094 "Source Node Identifier";
CM_ SG_ 1456 SVI_Request_ext "Cluster Glow";
CM_ SG_ 1456 DM_Camera_Block "Driver Camera is blocked or obstructed";
CM_ SG_ 1456 HAS_TelltaleSts_ext "'HAS_TelltaleSts_ext .TEXT MSG n corresponds to a raw value of 'n'";
CM_ SG_ 1456 DisplaySts_Route "'DisplaySts_Route.TEXT MSG n corresponds to a raw value of 'n'";
BA_DEF_ SG_ "GenSigTimeoutTime_MPAD" INT 0 65535;
BA_DEF_ SG_ "GenSigTimeoutTime_ADCAM" INT 0 65535;
BA_DEF_ SG_ "GenSigTimeoutTime_CVADAS" INT 0 65535;
BA_DEF_ SG_ "GenSigTimeoutTime_VDCM" INT 0 65535;
BA_DEF_ SG_ "GenSigStartValue" INT 0 2147483647;
BA_DEF_ SG_ "GenSigInactiveValue" INT 0 2147483647;
BA_DEF_ SG_ "GenSigSendType" ENUM "NotUsed","OnWrite","OnWriteWithRepetition","OnChange","OnChangeWithRepetition","IfActive","IfActiveWithRepetition","NoSigSendType";
BA_DEF_ SG_ "SystemSignalLongSymbol" STRING ;
BA_DEF_ SG_ "GenSigTimeoutTime_BSM" INT 0 65535;
BA_DEF_ SG_ "GenSigTimeoutTime_BSM2" INT 0 65535;
BA_DEF_ SG_ "GenSigTimeoutTime_CADM" INT 0 65535;
BA_DEF_ SG_ "GenSigTimeoutTime_CVPAM" INT 0 65535;
BA_DEF_ SG_ "GenSigTimeoutTime_ECM" INT 0 65535;
BA_DEF_ SG_ "GenSigTimeoutTime_EPS" INT 0 65535;
BA_DEF_ SG_ "GenSigTimeoutTime_EVCU2" INT 0 65535;
BA_DEF_ SG_ "GenSigTimeoutTime_ORC" INT 0 65535;
BA_DEF_ BO_ "DiagRequest" ENUM "No","Yes";
BA_DEF_ BO_ "Type" ENUM "P","C","PE","COC","PE_Cntrl","E","E_Cntrl","OC","S","BAF","DC","EM","MM","ISO-TP","-";
BA_DEF_ BO_ "DiagResponse" ENUM "No","Yes";
BA_DEF_ BO_ "NmMessage" ENUM "No","Yes";
BA_DEF_ BO_ "GenMsgSendType" ENUM "Cyclic","NotUsed","NotUsed","NotUsed","NotUsed","NotUsed","NotUsed","NotUsed","NoMsgSendType";
BA_DEF_ BO_ "GenMsgNrOfRepetition" INT 0 255;
BA_DEF_ BO_ "GenMsgILSupport" ENUM "No","Yes";
BA_DEF_ BO_ "GenMsgStartDelayTime" INT 0 65535;
BA_DEF_ BO_ "GenMsgCycleTimeFast" INT 0 65535;
BA_DEF_ BO_ "GenMsgCycleTime" INT 0 65535;
BA_DEF_ BO_ "GenMsgDelayTime" INT 0 65535;
BA_DEF_ BO_ "NmAsrMessage" ENUM "No","Yes";
BA_DEF_ BO_ "DiagState" ENUM "No","Yes";
BA_DEF_ BO_ "DiagConnection" HEX 0 65535;
BA_DEF_ BO_ "VFrameFormat" ENUM "StandardCAN","ExtendedCAN","reserved","reserved","reserved","reserved","reserved","reserved","reserved","reserved","reserved","reserved","reserved","reserved","StandardCAN_FD","ExtendedCAN_FD";
BA_DEF_ BO_ "CANFD_BRS" ENUM "0","1";
BA_DEF_DEF_ "GenSigTimeoutTime_MPAD" 2500;
BA_DEF_DEF_ "GenSigTimeoutTime_ADCAM" 2500;
BA_DEF_DEF_ "GenSigTimeoutTime_CVADAS" 2500;
BA_DEF_DEF_ "GenSigTimeoutTime_VDCM" 2500;
BA_DEF_DEF_ "GenSigStartValue" 0;
BA_DEF_DEF_ "GenSigInactiveValue" 0;
BA_DEF_DEF_ "GenSigSendType" "NoSigSendType";
BA_DEF_DEF_ "SystemSignalLongSymbol" "";
BA_DEF_DEF_ "GenSigTimeoutTime_BSM" 2500;
BA_DEF_DEF_ "GenSigTimeoutTime_BSM2" 2500;
BA_DEF_DEF_ "GenSigTimeoutTime_CADM" 2500;
BA_DEF_DEF_ "GenSigTimeoutTime_CVPAM" 2500;
BA_DEF_DEF_ "GenSigTimeoutTime_ECM" 2500;
BA_DEF_DEF_ "GenSigTimeoutTime_EPS" 2500;
BA_DEF_DEF_ "GenSigTimeoutTime_EVCU2" 2500;
BA_DEF_DEF_ "GenSigTimeoutTime_ORC" 2500;
BA_DEF_DEF_ "DiagRequest" "No";
BA_DEF_DEF_ "Type" "-";
BA_DEF_DEF_ "DiagResponse" "No";
BA_DEF_DEF_ "NmMessage" "No";
BA_DEF_DEF_ "GenMsgSendType" "NoMsgSendType";
BA_DEF_DEF_ "GenMsgNrOfRepetition" 0;
BA_DEF_DEF_ "GenMsgILSupport" "No";
BA_DEF_DEF_ "GenMsgStartDelayTime" 0;
BA_DEF_DEF_ "GenMsgCycleTimeFast" 0;
BA_DEF_DEF_ "GenMsgCycleTime" 0;
BA_DEF_DEF_ "GenMsgDelayTime" 0;
BA_DEF_DEF_ "NmAsrMessage" "No";
BA_DEF_DEF_ "DiagState" "No";
BA_DEF_DEF_ "DiagConnection" 0;
BA_DEF_DEF_ "VFrameFormat" "StandardCAN_FD";
BA_DEF_DEF_ "CANFD_BRS" "0";
BA_ "Type" BO_ 1456 3;
BA_ "GenMsgSendType" BO_ 1456 0;
BA_ "GenMsgILSupport" BO_ 1456 1;
BA_ "GenMsgCycleTime" BO_ 1456 100;
BA_ "GenMsgDelayTime" BO_ 1456 20;
BA_ "CANFD_BRS" BO_ 1456 1;
BA_ "Type" BO_ 2654486529 8;
BA_ "NmMessage" BO_ 2654486529 1;
BA_ "NmAsrMessage" BO_ 2654486529 1;
BA_ "VFrameFormat" BO_ 2654486529 15;
BA_ "CANFD_BRS" BO_ 2654486529 1;
BA_ "Type" BO_ 2654486669 8;
BA_ "NmMessage" BO_ 2654486669 1;
BA_ "NmAsrMessage" BO_ 2654486669 1;
BA_ "VFrameFormat" BO_ 2654486669 15;
BA_ "CANFD_BRS" BO_ 2654486669 1;
BA_ "Type" BO_ 2654486534 8;
BA_ "NmMessage" BO_ 2654486534 1;
BA_ "NmAsrMessage" BO_ 2654486534 1;
BA_ "VFrameFormat" BO_ 2654486534 15;
BA_ "CANFD_BRS" BO_ 2654486534 1;
BA_ "Type" BO_ 262 1;
BA_ "GenMsgSendType" BO_ 262 0;
BA_ "GenMsgILSupport" BO_ 262 1;
BA_ "GenMsgCycleTime" BO_ 262 10;
BA_ "CANFD_BRS" BO_ 262 1;
BA_ "Type" BO_ 258 1;
BA_ "GenMsgSendType" BO_ 258 0;
BA_ "GenMsgILSupport" BO_ 258 1;
BA_ "GenMsgCycleTime" BO_ 258 10;
BA_ "CANFD_BRS" BO_ 258 1;
BA_ "Type" BO_ 2654486530 8;
BA_ "NmMessage" BO_ 2654486530 1;
BA_ "NmAsrMessage" BO_ 2654486530 1;
BA_ "VFrameFormat" BO_ 2654486530 15;
BA_ "CANFD_BRS" BO_ 2654486530 1;
BA_ "Type" BO_ 524 1;
BA_ "GenMsgSendType" BO_ 524 0;
BA_ "GenMsgILSupport" BO_ 524 1;
BA_ "GenMsgCycleTime" BO_ 524 20;
BA_ "CANFD_BRS" BO_ 524 1;
BA_ "Type" BO_ 257 1;
BA_ "GenMsgSendType" BO_ 257 0;
BA_ "GenMsgILSupport" BO_ 257 1;
BA_ "GenMsgCycleTime" BO_ 257 10;
BA_ "CANFD_BRS" BO_ 257 1;
BA_ "Type" BO_ 2654486552 8;
BA_ "NmMessage" BO_ 2654486552 1;
BA_ "NmAsrMessage" BO_ 2654486552 1;
BA_ "VFrameFormat" BO_ 2654486552 15;
BA_ "CANFD_BRS" BO_ 2654486552 1;
BA_ "Type" BO_ 2654486676 8;
BA_ "NmMessage" BO_ 2654486676 1;
BA_ "NmAsrMessage" BO_ 2654486676 1;
BA_ "VFrameFormat" BO_ 2654486676 15;
BA_ "CANFD_BRS" BO_ 2654486676 1;
BA_ "GenSigTimeoutTime_BSM2" SG_ 258 YawRateFailSts_BSM 0;
BA_ "GenSigTimeoutTime_ECM" SG_ 258 YawRateFailSts_BSM 0;
BA_ "GenSigTimeoutTime_EVCU2" SG_ 258 YawRateFailSts_BSM 0;
BA_ "GenSigTimeoutTime_ORC" SG_ 258 YawRateFailSts_BSM 0;
BA_ "GenSigTimeoutTime_VDCM" SG_ 258 YawRateFailSts_BSM 0;
BA_ "GenSigTimeoutTime_CVADAS" SG_ 258 PrefillActive 0;
BA_ "GenSigTimeoutTime_VDCM" SG_ 258 PrefillActive 0;
BA_ "GenSigTimeoutTime_MPAD" SG_ 258 Slope 0;
BA_ "GenSigTimeoutTime_ADCAM" SG_ 258 Slope 0;
BA_ "GenSigTimeoutTime_CVADAS" SG_ 258 Slope 0;
BA_ "GenSigTimeoutTime_VDCM" SG_ 258 Slope 0;
BA_ "GenSigTimeoutTime_BSM" SG_ 258 Slope 0;
BA_ "GenSigTimeoutTime_BSM2" SG_ 258 Slope 0;
BA_ "GenSigTimeoutTime_CADM" SG_ 258 Slope 0;
BA_ "GenSigTimeoutTime_ECM" SG_ 258 Slope 0;
BA_ "GenSigTimeoutTime_EPS" SG_ 258 Slope 0;
BA_ "GenSigTimeoutTime_EVCU2" SG_ 258 Slope 0;
BA_ "GenSigTimeoutTime_ORC" SG_ 258 Slope 0;
BA_ "GenSigTimeoutTime_VDCM" SG_ 258 VehicleSpeedVSOSig 0;
BA_ "GenSigTimeoutTime_ECM" SG_ 258 VehicleSpeedVSOSig 0;
BA_ "GenSigTimeoutTime_BSM" SG_ 258 VehicleSpeedVSOSig 0;
BA_ "GenSigTimeoutTime_ORC" SG_ 258 VehicleSpeedVSOSig 0;
BA_ "GenSigTimeoutTime_VDCM" SG_ 258 YawRate_BSM 0;
BA_ "GenSigStartValue" SG_ 258 YawRate_BSM 4095;
BA_ "GenSigTimeoutTime_BSM" SG_ 258 YawRate_BSM 0;
BA_ "GenSigTimeoutTime_BSM2" SG_ 258 YawRate_BSM 0;
BA_ "GenSigTimeoutTime_ECM" SG_ 258 YawRate_BSM 0;
BA_ "GenSigTimeoutTime_EVCU2" SG_ 258 YawRate_BSM 0;
BA_ "GenSigTimeoutTime_ORC" SG_ 258 YawRate_BSM 0;
BA_ "GenSigTimeoutTime_ADCAM" SG_ 258 ABSActive 0;
BA_ "GenSigTimeoutTime_CVADAS" SG_ 258 ABSActive 0;
BA_ "GenSigTimeoutTime_VDCM" SG_ 258 ABSActive 0;
BA_ "GenSigTimeoutTime_MPAD" SG_ 258 BrakeBoostPressure 0;
BA_ "GenSigTimeoutTime_ADCAM" SG_ 258 BrakeBoostPressure 0;
BA_ "GenSigTimeoutTime_CVADAS" SG_ 258 BrakeBoostPressure 0;
BA_ "GenSigTimeoutTime_VDCM" SG_ 258 BrakeBoostPressure 0;
BA_ "GenSigTimeoutTime_MPAD" SG_ 258 BrakeBoostStat 0;
BA_ "GenSigTimeoutTime_ADCAM" SG_ 258 BrakeBoostStat 0;
BA_ "GenSigTimeoutTime_CVADAS" SG_ 258 BrakeBoostStat 0;
BA_ "GenSigTimeoutTime_VDCM" SG_ 258 BrakeBoostStat 0;
BA_ "GenSigTimeoutTime_CVADAS" SG_ 258 BrakeInterventionSts 0;
BA_ "GenSigTimeoutTime_VDCM" SG_ 258 BrakeInterventionSts 0;
BA_ "GenSigTimeoutTime_MPAD" SG_ 258 BrakePedalPressure 0;
BA_ "GenSigTimeoutTime_ADCAM" SG_ 258 BrakePedalPressure 0;
BA_ "GenSigTimeoutTime_CVADAS" SG_ 258 BrakePedalPressure 0;
BA_ "GenSigTimeoutTime_VDCM" SG_ 258 BrakePedalPressure 0;
BA_ "GenSigTimeoutTime_MPAD" SG_ 258 CRC_BRAKE2 0;
BA_ "GenSigTimeoutTime_CVADAS" SG_ 258 CRC_BRAKE2 0;
BA_ "GenSigTimeoutTime_VDCM" SG_ 258 CRC_BRAKE2 0;
BA_ "GenSigTimeoutTime_ECM" SG_ 258 CRC_BRAKE2 0;
BA_ "GenSigTimeoutTime_ADCAM" SG_ 258 ESCActive 0;
BA_ "GenSigTimeoutTime_CVADAS" SG_ 258 ESCActive 0;
BA_ "GenSigTimeoutTime_VDCM" SG_ 258 ESCActive 0;
BA_ "GenSigTimeoutTime_MPAD" SG_ 258 ESP_Sys_Stat 0;
BA_ "GenSigTimeoutTime_ADCAM" SG_ 258 ESP_Sys_Stat 0;
BA_ "GenSigTimeoutTime_CVADAS" SG_ 258 ESP_Sys_Stat 0;
BA_ "GenSigTimeoutTime_VDCM" SG_ 258 ESP_Sys_Stat 0;
BA_ "GenSigTimeoutTime_CVADAS" SG_ 258 InternalError_BSM 0;
BA_ "GenSigTimeoutTime_VDCM" SG_ 258 InternalError_BSM 0;
BA_ "GenSigStartValue" SG_ 258 LatAcceleration_BSM 4095;
BA_ "GenSigTimeoutTime_BSM" SG_ 258 LatAcceleration_BSM 0;
BA_ "GenSigTimeoutTime_BSM2" SG_ 258 LatAcceleration_BSM 0;
BA_ "GenSigTimeoutTime_ECM" SG_ 258 LatAcceleration_BSM 0;
BA_ "GenSigTimeoutTime_EVCU2" SG_ 258 LatAcceleration_BSM 0;
BA_ "GenSigTimeoutTime_ORC" SG_ 258 LatAcceleration_BSM 0;
BA_ "GenSigTimeoutTime_BSM" SG_ 258 LatAccelerationFailSts_BSM 0;
BA_ "GenSigTimeoutTime_BSM2" SG_ 258 LatAccelerationFailSts_BSM 0;
BA_ "GenSigTimeoutTime_ECM" SG_ 258 LatAccelerationFailSts_BSM 0;
BA_ "GenSigTimeoutTime_EPS" SG_ 258 LatAccelerationFailSts_BSM 0;
BA_ "GenSigTimeoutTime_EVCU2" SG_ 258 LatAccelerationFailSts_BSM 0;
BA_ "GenSigTimeoutTime_ORC" SG_ 258 LatAccelerationFailSts_BSM 0;
BA_ "GenSigTimeoutTime_VDCM" SG_ 258 LatAccelerationFailSts_BSM 0;
BA_ "GenSigStartValue" SG_ 258 LongAcceleration_BSM 4095;
BA_ "GenSigTimeoutTime_BSM" SG_ 258 LongAcceleration_BSM 0;
BA_ "GenSigTimeoutTime_BSM2" SG_ 258 LongAcceleration_BSM 0;
BA_ "GenSigTimeoutTime_ECM" SG_ 258 LongAcceleration_BSM 0;
BA_ "GenSigTimeoutTime_EVCU2" SG_ 258 LongAcceleration_BSM 0;
BA_ "GenSigTimeoutTime_ORC" SG_ 258 LongAcceleration_BSM 0;
BA_ "GenSigTimeoutTime_BSM" SG_ 258 LongAccelerationFailSts_BSM 0;
BA_ "GenSigTimeoutTime_BSM2" SG_ 258 LongAccelerationFailSts_BSM 0;
BA_ "GenSigTimeoutTime_ECM" SG_ 258 LongAccelerationFailSts_BSM 0;
BA_ "GenSigTimeoutTime_EPS" SG_ 258 LongAccelerationFailSts_BSM 0;
BA_ "GenSigTimeoutTime_EVCU2" SG_ 258 LongAccelerationFailSts_BSM 0;
BA_ "GenSigTimeoutTime_VDCM" SG_ 258 LongAccelerationFailSts_BSM 0;
BA_ "GenSigTimeoutTime_MPAD" SG_ 258 MessageCounter_BRAKE2 0;
BA_ "GenSigTimeoutTime_CVADAS" SG_ 258 MessageCounter_BRAKE2 0;
BA_ "GenSigTimeoutTime_VDCM" SG_ 258 MessageCounter_BRAKE2 0;
BA_ "GenSigTimeoutTime_ECM" SG_ 258 MessageCounter_BRAKE2 0;
BA_ "GenSigTimeoutTime_MPAD" SG_ 258 ParkingInterventionSts 0;
BA_ "GenSigTimeoutTime_ADCAM" SG_ 258 ParkingInterventionSts 0;
BA_ "GenSigTimeoutTime_MPAD" SG_ 258 ParkingGearShiftReq_BSM 0;
BA_ "GenSigTimeoutTime_ADCAM" SG_ 258 ParkingGearShiftReq_BSM 0;
BA_ "GenSigTimeoutTime_MPAD" SG_ 2654486530 SourceNodeIdentifier_1E384002 0;
BA_ "GenSigTimeoutTime_ADCAM" SG_ 2654486530 SourceNodeIdentifier_1E384002 0;
BA_ "GenSigTimeoutTime_CVADAS" SG_ 2654486530 SourceNodeIdentifier_1E384002 0;
BA_ "GenSigTimeoutTime_VDCM" SG_ 2654486530 SourceNodeIdentifier_1E384002 0;
BA_ "GenSigTimeoutTime_BSM" SG_ 2654486530 SourceNodeIdentifier_1E384002 0;
BA_ "GenSigTimeoutTime_BSM2" SG_ 2654486530 SourceNodeIdentifier_1E384002 0;
BA_ "GenSigTimeoutTime_CADM" SG_ 2654486530 SourceNodeIdentifier_1E384002 0;
BA_ "GenSigTimeoutTime_CVPAM" SG_ 2654486530 SourceNodeIdentifier_1E384002 0;
BA_ "GenSigTimeoutTime_ECM" SG_ 2654486530 SourceNodeIdentifier_1E384002 0;
BA_ "GenSigTimeoutTime_EPS" SG_ 2654486530 SourceNodeIdentifier_1E384002 0;
BA_ "GenSigTimeoutTime_EVCU2" SG_ 2654486530 SourceNodeIdentifier_1E384002 0;
BA_ "GenSigTimeoutTime_ORC" SG_ 2654486530 SourceNodeIdentifier_1E384002 0;
BA_ "GenSigTimeoutTime_MPAD" SG_ 2654486530 CBV_bit7_1E384002 0;
BA_ "GenSigTimeoutTime_ADCAM" SG_ 2654486530 CBV_bit7_1E384002 0;
BA_ "GenSigTimeoutTime_CVADAS" SG_ 2654486530 CBV_bit7_1E384002 0;
BA_ "GenSigTimeoutTime_VDCM" SG_ 2654486530 CBV_bit7_1E384002 0;
BA_ "GenSigTimeoutTime_BSM" SG_ 2654486530 CBV_bit7_1E384002 0;
BA_ "GenSigTimeoutTime_BSM2" SG_ 2654486530 CBV_bit7_1E384002 0;
BA_ "GenSigTimeoutTime_CADM" SG_ 2654486530 CBV_bit7_1E384002 0;
BA_ "GenSigTimeoutTime_CVPAM" SG_ 2654486530 CBV_bit7_1E384002 0;
BA_ "GenSigTimeoutTime_ECM" SG_ 2654486530 CBV_bit7_1E384002 0;
BA_ "GenSigTimeoutTime_EPS" SG_ 2654486530 CBV_bit7_1E384002 0;
BA_ "GenSigTimeoutTime_EVCU2" SG_ 2654486530 CBV_bit7_1E384002 0;
BA_ "GenSigTimeoutTime_ORC" SG_ 2654486530 CBV_bit7_1E384002 0;
BA_ "GenSigTimeoutTime_MPAD" SG_ 2654486530 CBV_bit6_PartialNtwInfBit_1E384002 0;
BA_ "GenSigTimeoutTime_ADCAM" SG_ 2654486530 CBV_bit6_PartialNtwInfBit_1E384002 0;
BA_ "GenSigTimeoutTime_CVADAS" SG_ 2654486530 CBV_bit6_PartialNtwInfBit_1E384002 0;
BA_ "GenSigTimeoutTime_VDCM" SG_ 2654486530 CBV_bit6_PartialNtwInfBit_1E384002 0;
BA_ "GenSigTimeoutTime_BSM" SG_ 2654486530 CBV_bit6_PartialNtwInfBit_1E384002 0;
BA_ "GenSigTimeoutTime_BSM2" SG_ 2654486530 CBV_bit6_PartialNtwInfBit_1E384002 0;
BA_ "GenSigTimeoutTime_CADM" SG_ 2654486530 CBV_bit6_PartialNtwInfBit_1E384002 0;
BA_ "GenSigTimeoutTime_CVPAM" SG_ 2654486530 CBV_bit6_PartialNtwInfBit_1E384002 0;
BA_ "GenSigTimeoutTime_ECM" SG_ 2654486530 CBV_bit6_PartialNtwInfBit_1E384002 0;
BA_ "GenSigTimeoutTime_EPS" SG_ 2654486530 CBV_bit6_PartialNtwInfBit_1E384002 0;
BA_ "GenSigTimeoutTime_EVCU2" SG_ 2654486530 CBV_bit6_PartialNtwInfBit_1E384002 0;
BA_ "GenSigTimeoutTime_ORC" SG_ 2654486530 CBV_bit6_PartialNtwInfBit_1E384002 0;
BA_ "GenSigTimeoutTime_MPAD" SG_ 2654486530 CBV_bit5_1E384002 0;
BA_ "GenSigTimeoutTime_ADCAM" SG_ 2654486530 CBV_bit5_1E384002 0;
BA_ "GenSigTimeoutTime_CVADAS" SG_ 2654486530 CBV_bit5_1E384002 0;
BA_ "GenSigTimeoutTime_VDCM" SG_ 2654486530 CBV_bit5_1E384002 0;
BA_ "GenSigTimeoutTime_BSM" SG_ 2654486530 CBV_bit5_1E384002 0;
BA_ "GenSigTimeoutTime_BSM2" SG_ 2654486530 CBV_bit5_1E384002 0;
BA_ "GenSigTimeoutTime_CADM" SG_ 2654486530 CBV_bit5_1E384002 0;
BA_ "GenSigTimeoutTime_CVPAM" SG_ 2654486530 CBV_bit5_1E384002 0;
BA_ "GenSigTimeoutTime_ECM" SG_ 2654486530 CBV_bit5_1E384002 0;
BA_ "GenSigTimeoutTime_EPS" SG_ 2654486530 CBV_bit5_1E384002 0;
BA_ "GenSigTimeoutTime_EVCU2" SG_ 2654486530 CBV_bit5_1E384002 0;
BA_ "GenSigTimeoutTime_ORC" SG_ 2654486530 CBV_bit5_1E384002 0;
BA_ "GenSigTimeoutTime_MPAD" SG_ 2654486530 CBV_bit4_ActiveWakeupBit_1E384002 0;
BA_ "GenSigTimeoutTime_ADCAM" SG_ 2654486530 CBV_bit4_ActiveWakeupBit_1E384002 0;
BA_ "GenSigTimeoutTime_CVADAS" SG_ 2654486530 CBV_bit4_ActiveWakeupBit_1E384002 0;
BA_ "GenSigTimeoutTime_VDCM" SG_ 2654486530 CBV_bit4_ActiveWakeupBit_1E384002 0;
BA_ "GenSigTimeoutTime_BSM" SG_ 2654486530 CBV_bit4_ActiveWakeupBit_1E384002 0;
BA_ "GenSigTimeoutTime_BSM2" SG_ 2654486530 CBV_bit4_ActiveWakeupBit_1E384002 0;
BA_ "GenSigTimeoutTime_CADM" SG_ 2654486530 CBV_bit4_ActiveWakeupBit_1E384002 0;
BA_ "GenSigTimeoutTime_CVPAM" SG_ 2654486530 CBV_bit4_ActiveWakeupBit_1E384002 0;
BA_ "GenSigTimeoutTime_ECM" SG_ 2654486530 CBV_bit4_ActiveWakeupBit_1E384002 0;
BA_ "GenSigTimeoutTime_EPS" SG_ 2654486530 CBV_bit4_ActiveWakeupBit_1E384002 0;
BA_ "GenSigTimeoutTime_EVCU2" SG_ 2654486530 CBV_bit4_ActiveWakeupBit_1E384002 0;
BA_ "GenSigTimeoutTime_ORC" SG_ 2654486530 CBV_bit4_ActiveWakeupBit_1E384002 0;
BA_ "GenSigTimeoutTime_MPAD" SG_ 2654486530 CBV_bit3_NMCoordinatorBit_1E384002 0;
BA_ "GenSigTimeoutTime_ADCAM" SG_ 2654486530 CBV_bit3_NMCoordinatorBit_1E384002 0;
BA_ "GenSigTimeoutTime_CVADAS" SG_ 2654486530 CBV_bit3_NMCoordinatorBit_1E384002 0;
BA_ "GenSigTimeoutTime_VDCM" SG_ 2654486530 CBV_bit3_NMCoordinatorBit_1E384002 0;
BA_ "GenSigTimeoutTime_BSM" SG_ 2654486530 CBV_bit3_NMCoordinatorBit_1E384002 0;
BA_ "GenSigTimeoutTime_BSM2" SG_ 2654486530 CBV_bit3_NMCoordinatorBit_1E384002 0;
BA_ "GenSigTimeoutTime_CADM" SG_ 2654486530 CBV_bit3_NMCoordinatorBit_1E384002 0;
BA_ "GenSigTimeoutTime_CVPAM" SG_ 2654486530 CBV_bit3_NMCoordinatorBit_1E384002 0;
BA_ "GenSigTimeoutTime_ECM" SG_ 2654486530 CBV_bit3_NMCoordinatorBit_1E384002 0;
BA_ "GenSigTimeoutTime_EPS" SG_ 2654486530 CBV_bit3_NMCoordinatorBit_1E384002 0;
BA_ "GenSigTimeoutTime_EVCU2" SG_ 2654486530 CBV_bit3_NMCoordinatorBit_1E384002 0;
BA_ "GenSigTimeoutTime_ORC" SG_ 2654486530 CBV_bit3_NMCoordinatorBit_1E384002 0;
BA_ "GenSigTimeoutTime_MPAD" SG_ 2654486530 CBV_bit2_1E384002 0;
BA_ "GenSigTimeoutTime_ADCAM" SG_ 2654486530 CBV_bit2_1E384002 0;
BA_ "GenSigTimeoutTime_CVADAS" SG_ 2654486530 CBV_bit2_1E384002 0;
BA_ "GenSigTimeoutTime_VDCM" SG_ 2654486530 CBV_bit2_1E384002 0;
BA_ "GenSigTimeoutTime_BSM" SG_ 2654486530 CBV_bit2_1E384002 0;
BA_ "GenSigTimeoutTime_BSM2" SG_ 2654486530 CBV_bit2_1E384002 0;
BA_ "GenSigTimeoutTime_CADM" SG_ 2654486530 CBV_bit2_1E384002 0;
BA_ "GenSigTimeoutTime_CVPAM" SG_ 2654486530 CBV_bit2_1E384002 0;
BA_ "GenSigTimeoutTime_ECM" SG_ 2654486530 CBV_bit2_1E384002 0;
BA_ "GenSigTimeoutTime_EPS" SG_ 2654486530 CBV_bit2_1E384002 0;
BA_ "GenSigTimeoutTime_EVCU2" SG_ 2654486530 CBV_bit2_1E384002 0;
BA_ "GenSigTimeoutTime_ORC" SG_ 2654486530 CBV_bit2_1E384002 0;
BA_ "GenSigTimeoutTime_MPAD" SG_ 2654486530 CBV_bit1_1E384002 0;
BA_ "GenSigTimeoutTime_ADCAM" SG_ 2654486530 CBV_bit1_1E384002 0;
BA_ "GenSigTimeoutTime_CVADAS" SG_ 2654486530 CBV_bit1_1E384002 0;
BA_ "GenSigTimeoutTime_VDCM" SG_ 2654486530 CBV_bit1_1E384002 0;
BA_ "GenSigTimeoutTime_BSM" SG_ 2654486530 CBV_bit1_1E384002 0;
BA_ "GenSigTimeoutTime_BSM2" SG_ 2654486530 CBV_bit1_1E384002 0;
BA_ "GenSigTimeoutTime_CADM" SG_ 2654486530 CBV_bit1_1E384002 0;
BA_ "GenSigTimeoutTime_CVPAM" SG_ 2654486530 CBV_bit1_1E384002 0;
BA_ "GenSigTimeoutTime_ECM" SG_ 2654486530 CBV_bit1_1E384002 0;
BA_ "GenSigTimeoutTime_EPS" SG_ 2654486530 CBV_bit1_1E384002 0;
BA_ "GenSigTimeoutTime_EVCU2" SG_ 2654486530 CBV_bit1_1E384002 0;
BA_ "GenSigTimeoutTime_ORC" SG_ 2654486530 CBV_bit1_1E384002 0;
BA_ "GenSigTimeoutTime_MPAD" SG_ 2654486530 CBV_bit0_RepeatMessageRequestBit_1E384002 0;
BA_ "GenSigTimeoutTime_ADCAM" SG_ 2654486530 CBV_bit0_RepeatMessageRequestBit_1E384002 0;
BA_ "GenSigTimeoutTime_CVADAS" SG_ 2654486530 CBV_bit0_RepeatMessageRequestBit_1E384002 0;
BA_ "GenSigTimeoutTime_VDCM" SG_ 2654486530 CBV_bit0_RepeatMessageRequestBit_1E384002 0;
BA_ "GenSigTimeoutTime_BSM" SG_ 2654486530 CBV_bit0_RepeatMessageRequestBit_1E384002 0;
BA_ "GenSigTimeoutTime_BSM2" SG_ 2654486530 CBV_bit0_RepeatMessageRequestBit_1E384002 0;
BA_ "GenSigTimeoutTime_CADM" SG_ 2654486530 CBV_bit0_RepeatMessageRequestBit_1E384002 0;
BA_ "GenSigTimeoutTime_CVPAM" SG_ 2654486530 CBV_bit0_RepeatMessageRequestBit_1E384002 0;
BA_ "GenSigTimeoutTime_ECM" SG_ 2654486530 CBV_bit0_RepeatMessageRequestBit_1E384002 0;
BA_ "GenSigTimeoutTime_EPS" SG_ 2654486530 CBV_bit0_RepeatMessageRequestBit_1E384002 0;
BA_ "GenSigTimeoutTime_EVCU2" SG_ 2654486530 CBV_bit0_RepeatMessageRequestBit_1E384002 0;
BA_ "GenSigTimeoutTime_ORC" SG_ 2654486530 CBV_bit0_RepeatMessageRequestBit_1E384002 0;
BA_ "GenSigTimeoutTime_CVADAS" SG_ 258 BSM_ESASystemSts 0;
BA_ "GenSigTimeoutTime_BSM" SG_ 258 BSM_ESASystemSts 0;
BA_ "GenSigTimeoutTime_BSM2" SG_ 258 BSM_ESASystemSts 0;
BA_ "GenSigTimeoutTime_ECM" SG_ 258 BSM_ESASystemSts 0;
BA_ "GenSigTimeoutTime_EVCU2" SG_ 258 BSM_ESASystemSts 0;
BA_ "GenSigTimeoutTime_ORC" SG_ 258 BSM_ESASystemSts 0;
BA_ "GenSigTimeoutTime_BSM" SG_ 258 ParkingGearShiftReq_BSM 0;
BA_ "GenSigTimeoutTime_BSM2" SG_ 258 ParkingGearShiftReq_BSM 0;
BA_ "GenSigTimeoutTime_CADM" SG_ 258 ParkingGearShiftReq_BSM 0;
BA_ "GenSigTimeoutTime_ECM" SG_ 258 ParkingGearShiftReq_BSM 0;
BA_ "GenSigTimeoutTime_EPS" SG_ 258 ParkingGearShiftReq_BSM 0;
BA_ "GenSigTimeoutTime_EVCU2" SG_ 258 ParkingGearShiftReq_BSM 0;
BA_ "GenSigTimeoutTime_ORC" SG_ 258 ParkingGearShiftReq_BSM 0;
BA_ "GenSigTimeoutTime_BSM" SG_ 258 ParkingInterventionSts 0;
BA_ "GenSigTimeoutTime_BSM2" SG_ 258 ParkingInterventionSts 0;
BA_ "GenSigTimeoutTime_CADM" SG_ 258 ParkingInterventionSts 0;
BA_ "GenSigTimeoutTime_ECM" SG_ 258 ParkingInterventionSts 0;
BA_ "GenSigTimeoutTime_EPS" SG_ 258 ParkingInterventionSts 0;
BA_ "GenSigTimeoutTime_EVCU2" SG_ 258 ParkingInterventionSts 0;
BA_ "GenSigTimeoutTime_ORC" SG_ 258 ParkingInterventionSts 0;
BA_ "GenSigTimeoutTime_MPAD" SG_ 2654486534 SourceNodeIdentifier_1E384006 0;
BA_ "GenSigTimeoutTime_ADCAM" SG_ 2654486534 SourceNodeIdentifier_1E384006 0;
BA_ "GenSigTimeoutTime_CVADAS" SG_ 2654486534 SourceNodeIdentifier_1E384006 0;
BA_ "GenSigTimeoutTime_VDCM" SG_ 2654486534 SourceNodeIdentifier_1E384006 0;
BA_ "GenSigTimeoutTime_MPAD" SG_ 2654486534 CBV_bit7_1E384006 0;
BA_ "GenSigTimeoutTime_ADCAM" SG_ 2654486534 CBV_bit7_1E384006 0;
BA_ "GenSigTimeoutTime_CVADAS" SG_ 2654486534 CBV_bit7_1E384006 0;
BA_ "GenSigTimeoutTime_VDCM" SG_ 2654486534 CBV_bit7_1E384006 0;
BA_ "GenSigTimeoutTime_MPAD" SG_ 2654486534 CBV_bit6_PartialNtwInfBit_1E384006 0;
BA_ "GenSigTimeoutTime_ADCAM" SG_ 2654486534 CBV_bit6_PartialNtwInfBit_1E384006 0;
BA_ "GenSigTimeoutTime_CVADAS" SG_ 2654486534 CBV_bit6_PartialNtwInfBit_1E384006 0;
BA_ "GenSigTimeoutTime_VDCM" SG_ 2654486534 CBV_bit6_PartialNtwInfBit_1E384006 0;
BA_ "GenSigTimeoutTime_MPAD" SG_ 2654486534 CBV_bit5_1E384006 0;
BA_ "GenSigTimeoutTime_ADCAM" SG_ 2654486534 CBV_bit5_1E384006 0;
BA_ "GenSigTimeoutTime_CVADAS" SG_ 2654486534 CBV_bit5_1E384006 0;
BA_ "GenSigTimeoutTime_VDCM" SG_ 2654486534 CBV_bit5_1E384006 0;
BA_ "GenSigTimeoutTime_MPAD" SG_ 2654486534 CBV_bit4_ActiveWakeupBit_1E384006 0;
BA_ "GenSigTimeoutTime_ADCAM" SG_ 2654486534 CBV_bit4_ActiveWakeupBit_1E384006 0;
BA_ "GenSigTimeoutTime_CVADAS" SG_ 2654486534 CBV_bit4_ActiveWakeupBit_1E384006 0;
BA_ "GenSigTimeoutTime_VDCM" SG_ 2654486534 CBV_bit4_ActiveWakeupBit_1E384006 0;
BA_ "GenSigTimeoutTime_MPAD" SG_ 2654486534 CBV_bit3_NMCoordinatorBit_1E384006 0;
BA_ "GenSigTimeoutTime_ADCAM" SG_ 2654486534 CBV_bit3_NMCoordinatorBit_1E384006 0;
BA_ "GenSigTimeoutTime_CVADAS" SG_ 2654486534 CBV_bit3_NMCoordinatorBit_1E384006 0;
BA_ "GenSigTimeoutTime_VDCM" SG_ 2654486534 CBV_bit3_NMCoordinatorBit_1E384006 0;
BA_ "GenSigTimeoutTime_MPAD" SG_ 2654486534 CBV_bit2_1E384006 0;
BA_ "GenSigTimeoutTime_ADCAM" SG_ 2654486534 CBV_bit2_1E384006 0;
BA_ "GenSigTimeoutTime_CVADAS" SG_ 2654486534 CBV_bit2_1E384006 0;
BA_ "GenSigTimeoutTime_VDCM" SG_ 2654486534 CBV_bit2_1E384006 0;
BA_ "GenSigTimeoutTime_MPAD" SG_ 2654486534 CBV_bit1_1E384006 0;
BA_ "GenSigTimeoutTime_ADCAM" SG_ 2654486534 CBV_bit1_1E384006 0;
BA_ "GenSigTimeoutTime_CVADAS" SG_ 2654486534 CBV_bit1_1E384006 0;
BA_ "GenSigTimeoutTime_VDCM" SG_ 2654486534 CBV_bit1_1E384006 0;
BA_ "GenSigTimeoutTime_MPAD" SG_ 2654486534 CBV_bit0_RepeatMessageRequestBit_1E384006 0;
BA_ "GenSigTimeoutTime_ADCAM" SG_ 2654486534 CBV_bit0_RepeatMessageRequestBit_1E384006 0;
BA_ "GenSigTimeoutTime_CVADAS" SG_ 2654486534 CBV_bit0_RepeatMessageRequestBit_1E384006 0;
BA_ "GenSigTimeoutTime_VDCM" SG_ 2654486534 CBV_bit0_RepeatMessageRequestBit_1E384006 0;
BA_ "GenSigTimeoutTime_BSM" SG_ 258 MessageCounter_BRAKE2 0;
BA_ "GenSigTimeoutTime_ORC" SG_ 258 MessageCounter_BRAKE2 0;
BA_ "GenSigTimeoutTime_ORC" SG_ 258 LongAccelerationFailSts_BSM 0;
BA_ "GenSigTimeoutTime_BSM" SG_ 258 InternalError_BSM 0;
BA_ "GenSigTimeoutTime_BSM2" SG_ 258 InternalError_BSM 0;
BA_ "GenSigTimeoutTime_CVPAM" SG_ 258 InternalError_BSM 0;
BA_ "GenSigTimeoutTime_ECM" SG_ 258 InternalError_BSM 0;
BA_ "GenSigTimeoutTime_EPS" SG_ 258 InternalError_BSM 0;
BA_ "GenSigTimeoutTime_EVCU2" SG_ 258 InternalError_BSM 0;
BA_ "GenSigTimeoutTime_ORC" SG_ 258 InternalError_BSM 0;
BA_ "GenSigStartValue" SG_ 258 ESP_Sys_Stat 1;
BA_ "GenSigTimeoutTime_BSM" SG_ 258 ESP_Sys_Stat 0;
BA_ "GenSigTimeoutTime_BSM2" SG_ 258 ESP_Sys_Stat 0;
BA_ "GenSigTimeoutTime_CADM" SG_ 258 ESP_Sys_Stat 0;
BA_ "GenSigTimeoutTime_CVPAM" SG_ 258 ESP_Sys_Stat 0;
BA_ "GenSigTimeoutTime_ECM" SG_ 258 ESP_Sys_Stat 0;
BA_ "GenSigTimeoutTime_EPS" SG_ 258 ESP_Sys_Stat 0;
BA_ "GenSigTimeoutTime_EVCU2" SG_ 258 ESP_Sys_Stat 0;
BA_ "GenSigTimeoutTime_ORC" SG_ 258 ESP_Sys_Stat 0;
BA_ "GenSigTimeoutTime_BSM" SG_ 258 ESCActive 0;
BA_ "GenSigTimeoutTime_BSM2" SG_ 258 ESCActive 0;
BA_ "GenSigTimeoutTime_ECM" SG_ 258 ESCActive 0;
BA_ "GenSigTimeoutTime_EPS" SG_ 258 ESCActive 0;
BA_ "GenSigTimeoutTime_ORC" SG_ 258 ESCActive 0;
BA_ "GenSigTimeoutTime_BSM" SG_ 258 CRC_BRAKE2 0;
BA_ "GenSigTimeoutTime_ORC" SG_ 258 CRC_BRAKE2 0;
BA_ "GenSigStartValue" SG_ 258 BrakePedalPressure 2047;
BA_ "GenSigTimeoutTime_BSM" SG_ 258 BrakePedalPressure 0;
BA_ "GenSigTimeoutTime_BSM2" SG_ 258 BrakePedalPressure 0;
BA_ "GenSigTimeoutTime_CADM" SG_ 258 BrakePedalPressure 0;
BA_ "GenSigTimeoutTime_CVPAM" SG_ 258 BrakePedalPressure 0;
BA_ "GenSigTimeoutTime_ECM" SG_ 258 BrakePedalPressure 0;
BA_ "GenSigTimeoutTime_EPS" SG_ 258 BrakePedalPressure 0;
BA_ "GenSigTimeoutTime_ORC" SG_ 258 BrakePedalPressure 0;
BA_ "GenSigTimeoutTime_BSM" SG_ 258 BrakeInterventionSts 0;
BA_ "GenSigTimeoutTime_CVPAM" SG_ 258 BrakeInterventionSts 0;
BA_ "GenSigTimeoutTime_ECM" SG_ 258 BrakeInterventionSts 0;
BA_ "GenSigTimeoutTime_EPS" SG_ 258 BrakeInterventionSts 0;
BA_ "GenSigTimeoutTime_EVCU2" SG_ 258 BrakeInterventionSts 0;
BA_ "GenSigTimeoutTime_ORC" SG_ 258 BrakeInterventionSts 0;
BA_ "GenSigTimeoutTime_BSM" SG_ 258 BrakeBoostStat 0;
BA_ "GenSigTimeoutTime_BSM2" SG_ 258 BrakeBoostStat 0;
BA_ "GenSigTimeoutTime_CADM" SG_ 258 BrakeBoostStat 0;
BA_ "GenSigTimeoutTime_CVPAM" SG_ 258 BrakeBoostStat 0;
BA_ "GenSigTimeoutTime_ECM" SG_ 258 BrakeBoostStat 0;
BA_ "GenSigTimeoutTime_EPS" SG_ 258 BrakeBoostStat 0;
BA_ "GenSigTimeoutTime_EVCU2" SG_ 258 BrakeBoostStat 0;
BA_ "GenSigTimeoutTime_ORC" SG_ 258 BrakeBoostStat 0;
BA_ "GenSigStartValue" SG_ 258 BrakeBoostPressure 2047;
BA_ "GenSigTimeoutTime_BSM" SG_ 258 BrakeBoostPressure 0;
BA_ "GenSigTimeoutTime_BSM2" SG_ 258 BrakeBoostPressure 0;
BA_ "GenSigTimeoutTime_CADM" SG_ 258 BrakeBoostPressure 0;
BA_ "GenSigTimeoutTime_CVPAM" SG_ 258 BrakeBoostPressure 0;
BA_ "GenSigTimeoutTime_ECM" SG_ 258 BrakeBoostPressure 0;
BA_ "GenSigTimeoutTime_EPS" SG_ 258 BrakeBoostPressure 0;
BA_ "GenSigTimeoutTime_ORC" SG_ 258 BrakeBoostPressure 0;
BA_ "GenSigTimeoutTime_BSM" SG_ 258 ABSActive 0;
BA_ "GenSigTimeoutTime_BSM2" SG_ 258 ABSActive 0;
BA_ "GenSigTimeoutTime_ECM" SG_ 258 ABSActive 0;
BA_ "GenSigTimeoutTime_EPS" SG_ 258 ABSActive 0;
BA_ "GenSigTimeoutTime_ORC" SG_ 258 ABSActive 0;
BA_ "GenSigTimeoutTime_BSM" SG_ 258 PrefillActive 0;
BA_ "GenSigTimeoutTime_BSM2" SG_ 258 PrefillActive 0;
BA_ "GenSigTimeoutTime_CVPAM" SG_ 258 PrefillActive 0;
BA_ "GenSigTimeoutTime_ECM" SG_ 258 PrefillActive 0;
BA_ "GenSigTimeoutTime_EPS" SG_ 258 PrefillActive 0;
BA_ "GenSigTimeoutTime_EVCU2" SG_ 258 PrefillActive 0;
BA_ "GenSigTimeoutTime_ORC" SG_ 258 PrefillActive 0;
BA_ "GenSigTimeoutTime_CVADAS" SG_ 262 CRC_ENGINE2 0;
BA_ "GenSigTimeoutTime_VDCM" SG_ 262 CRC_ENGINE2 0;
BA_ "GenSigTimeoutTime_BSM" SG_ 262 CRC_ENGINE2 0;
BA_ "GenSigTimeoutTime_EPS" SG_ 262 CRC_ENGINE2 0;
BA_ "GenSigTimeoutTime_BSM2" SG_ 262 CRC_ENGINE2 0;
BA_ "GenSigTimeoutTime_ECM" SG_ 262 CRC_ENGINE2 0;
BA_ "GenSigTimeoutTime_EVCU2" SG_ 262 CRC_ENGINE2 0;
BA_ "GenSigTimeoutTime_ORC" SG_ 262 CRC_ENGINE2 0;
BA_ "GenSigTimeoutTime_CVADAS" SG_ 262 ECM_LHOM_W 0;
BA_ "GenSigTimeoutTime_VDCM" SG_ 262 ECM_LHOM_W 0;
BA_ "GenSigTimeoutTime_BSM" SG_ 262 ECM_LHOM_W 0;
BA_ "GenSigTimeoutTime_BSM2" SG_ 262 ECM_LHOM_W 0;
BA_ "GenSigTimeoutTime_CVPAM" SG_ 262 ECM_LHOM_W 0;
BA_ "GenSigTimeoutTime_ECM" SG_ 262 ECM_LHOM_W 0;
BA_ "GenSigTimeoutTime_EPS" SG_ 262 ECM_LHOM_W 0;
BA_ "GenSigTimeoutTime_EVCU2" SG_ 262 ECM_LHOM_W 0;
BA_ "GenSigTimeoutTime_ORC" SG_ 262 ECM_LHOM_W 0;
BA_ "GenSigTimeoutTime_ORC" SG_ 262 PowertrainPrplsnActv 0;
BA_ "GenSigTimeoutTime_CVADAS" SG_ 262 PowertrainPrplsnActv 0;
BA_ "GenSigTimeoutTime_VDCM" SG_ 262 PowertrainPrplsnActv 0;
BA_ "GenSigTimeoutTime_BSM2" SG_ 262 PowertrainPrplsnActv 0;
BA_ "GenSigTimeoutTime_CVPAM" SG_ 262 PowertrainPrplsnActv 0;
BA_ "GenSigTimeoutTime_ECM" SG_ 262 PowertrainPrplsnActv 0;
BA_ "GenSigTimeoutTime_EPS" SG_ 262 PowertrainPrplsnActv 0;
BA_ "GenSigTimeoutTime_EVCU2" SG_ 262 PowertrainPrplsnActv 0;
BA_ "GenSigTimeoutTime_CVADAS" SG_ 262 MessageCounter_ENGINE2 0;
BA_ "GenSigTimeoutTime_VDCM" SG_ 262 MessageCounter_ENGINE2 0;
BA_ "GenSigTimeoutTime_BSM" SG_ 262 MessageCounter_ENGINE2 0;
BA_ "GenSigTimeoutTime_EPS" SG_ 262 MessageCounter_ENGINE2 0;
BA_ "GenSigTimeoutTime_BSM2" SG_ 262 MessageCounter_ENGINE2 0;
BA_ "GenSigTimeoutTime_ECM" SG_ 262 MessageCounter_ENGINE2 0;
BA_ "GenSigTimeoutTime_EVCU2" SG_ 262 MessageCounter_ENGINE2 0;
BA_ "GenSigTimeoutTime_ORC" SG_ 262 MessageCounter_ENGINE2 0;
BA_ "GenSigTimeoutTime_CVADAS" SG_ 262 GasPedalPositionFailSts_W 0;
BA_ "GenSigTimeoutTime_VDCM" SG_ 262 GasPedalPositionFailSts_W 0;
BA_ "GenSigTimeoutTime_BSM" SG_ 262 GasPedalPositionFailSts_W 0;
BA_ "GenSigTimeoutTime_BSM2" SG_ 262 GasPedalPositionFailSts_W 0;
BA_ "GenSigTimeoutTime_CVPAM" SG_ 262 GasPedalPositionFailSts_W 0;
BA_ "GenSigTimeoutTime_ECM" SG_ 262 GasPedalPositionFailSts_W 0;
BA_ "GenSigTimeoutTime_EPS" SG_ 262 GasPedalPositionFailSts_W 0;
BA_ "GenSigTimeoutTime_EVCU2" SG_ 262 GasPedalPositionFailSts_W 0;
BA_ "GenSigTimeoutTime_ORC" SG_ 262 GasPedalPositionFailSts_W 0;
BA_ "GenSigTimeoutTime_ADCAM" SG_ 262 LV12PwrFreeRq_W 0;
BA_ "GenSigTimeoutTime_CVADAS" SG_ 262 LV12PwrFreeRq_W 0;
BA_ "GenSigTimeoutTime_VDCM" SG_ 262 LV12PwrFreeRq_W 0;
BA_ "GenSigTimeoutTime_BSM" SG_ 262 LV12PwrFreeRq_W 0;
BA_ "GenSigTimeoutTime_BSM2" SG_ 262 LV12PwrFreeRq_W 0;
BA_ "GenSigTimeoutTime_CADM" SG_ 262 LV12PwrFreeRq_W 0;
BA_ "GenSigTimeoutTime_CVPAM" SG_ 262 LV12PwrFreeRq_W 0;
BA_ "GenSigTimeoutTime_ECM" SG_ 262 LV12PwrFreeRq_W 0;
BA_ "GenSigTimeoutTime_EPS" SG_ 262 LV12PwrFreeRq_W 0;
BA_ "GenSigTimeoutTime_EVCU2" SG_ 262 LV12PwrFreeRq_W 0;
BA_ "GenSigTimeoutTime_ORC" SG_ 262 LV12PwrFreeRq_W 0;
BA_ "GenSigTimeoutTime_CVADAS" SG_ 262 EngineSpeed_W 0;
BA_ "GenSigTimeoutTime_VDCM" SG_ 262 EngineSpeed_W 0;
BA_ "GenSigTimeoutTime_BSM2" SG_ 262 EngineSpeed_W 0;
BA_ "GenSigTimeoutTime_CVPAM" SG_ 262 EngineSpeed_W 0;
BA_ "GenSigTimeoutTime_ECM" SG_ 262 EngineSpeed_W 0;
BA_ "GenSigTimeoutTime_EVCU2" SG_ 262 EngineSpeed_W 0;
BA_ "GenSigTimeoutTime_ORC" SG_ 262 EngineSpeed_W 0;
BA_ "GenSigTimeoutTime_CVADAS" SG_ 262 EngineSts_W 0;
BA_ "GenSigTimeoutTime_VDCM" SG_ 262 EngineSts_W 0;
BA_ "GenSigTimeoutTime_BSM" SG_ 262 EngineSts_W 0;
BA_ "GenSigTimeoutTime_EPS" SG_ 262 EngineSts_W 0;
BA_ "GenSigStartValue" SG_ 262 EngineSts_W 3;
BA_ "GenSigTimeoutTime_BSM2" SG_ 262 EngineSts_W 0;
BA_ "GenSigTimeoutTime_ECM" SG_ 262 EngineSts_W 0;
BA_ "GenSigTimeoutTime_EVCU2" SG_ 262 EngineSts_W 0;
BA_ "GenSigTimeoutTime_ORC" SG_ 262 EngineSts_W 0;
BA_ "GenSigTimeoutTime_CVADAS" SG_ 262 ESS_ENG_ST_W 0;
BA_ "GenSigTimeoutTime_VDCM" SG_ 262 ESS_ENG_ST_W 0;
BA_ "GenSigStartValue" SG_ 262 ESS_ENG_ST_W 15;
BA_ "GenSigSendType" SG_ 262 ESS_ENG_ST_W 3;
BA_ "GenSigTimeoutTime_BSM2" SG_ 262 ESS_ENG_ST_W 0;
BA_ "GenSigTimeoutTime_CVPAM" SG_ 262 ESS_ENG_ST_W 0;
BA_ "GenSigTimeoutTime_ECM" SG_ 262 ESS_ENG_ST_W 0;
BA_ "GenSigTimeoutTime_EVCU2" SG_ 262 ESS_ENG_ST_W 0;
BA_ "GenSigTimeoutTime_ORC" SG_ 262 ESS_ENG_ST_W 0;
BA_ "GenSigTimeoutTime_CVADAS" SG_ 262 GasPedalPosition_W 0;
BA_ "GenSigTimeoutTime_VDCM" SG_ 262 GasPedalPosition_W 0;
BA_ "GenSigTimeoutTime_BSM2" SG_ 262 GasPedalPosition_W 0;
BA_ "GenSigTimeoutTime_CADM" SG_ 262 GasPedalPosition_W 0;
BA_ "GenSigTimeoutTime_CVPAM" SG_ 262 GasPedalPosition_W 0;
BA_ "GenSigTimeoutTime_ECM" SG_ 262 GasPedalPosition_W 0;
BA_ "GenSigTimeoutTime_EPS" SG_ 262 GasPedalPosition_W 0;
BA_ "GenSigTimeoutTime_EVCU2" SG_ 262 GasPedalPosition_W 0;
BA_ "GenSigTimeoutTime_ORC" SG_ 262 GasPedalPosition_W 0;
BA_ "GenSigTimeoutTime_BSM" SG_ 258 Brk_Stat 0;
BA_ "GenSigTimeoutTime_BSM2" SG_ 258 Brk_Stat 0;
BA_ "GenSigTimeoutTime_EPS" SG_ 258 Brk_Stat 0;
BA_ "GenSigTimeoutTime_ORC" SG_ 258 Brk_Stat 0;
BA_ "GenSigStartValue" SG_ 258 WheelRPM_FL 65535;
BA_ "GenSigTimeoutTime_BSM" SG_ 258 WheelRPM_FL 0;
BA_ "GenSigTimeoutTime_BSM2" SG_ 258 WheelRPM_FL 0;
BA_ "GenSigTimeoutTime_CADM" SG_ 258 WheelRPM_FL 0;
BA_ "GenSigTimeoutTime_CVPAM" SG_ 258 WheelRPM_FL 0;
BA_ "GenSigTimeoutTime_ECM" SG_ 258 WheelRPM_FL 0;
BA_ "GenSigTimeoutTime_ORC" SG_ 258 WheelRPM_FL 0;
BA_ "GenSigStartValue" SG_ 258 WheelRPM_FR 65535;
BA_ "GenSigTimeoutTime_BSM" SG_ 258 WheelRPM_FR 0;
BA_ "GenSigTimeoutTime_BSM2" SG_ 258 WheelRPM_FR 0;
BA_ "GenSigTimeoutTime_CADM" SG_ 258 WheelRPM_FR 0;
BA_ "GenSigTimeoutTime_CVPAM" SG_ 258 WheelRPM_FR 0;
BA_ "GenSigTimeoutTime_ECM" SG_ 258 WheelRPM_FR 0;
BA_ "GenSigTimeoutTime_ORC" SG_ 258 WheelRPM_FR 0;
BA_ "GenSigTimeoutTime_BSM" SG_ 2654486534 CBV_bit0_RepeatMessageRequestBit_1E384006 0;
BA_ "GenSigTimeoutTime_BSM2" SG_ 2654486534 CBV_bit0_RepeatMessageRequestBit_1E384006 0;
BA_ "GenSigTimeoutTime_CADM" SG_ 2654486534 CBV_bit0_RepeatMessageRequestBit_1E384006 0;
BA_ "GenSigTimeoutTime_CVPAM" SG_ 2654486534 CBV_bit0_RepeatMessageRequestBit_1E384006 0;
BA_ "GenSigTimeoutTime_ECM" SG_ 2654486534 CBV_bit0_RepeatMessageRequestBit_1E384006 0;
BA_ "GenSigTimeoutTime_EPS" SG_ 2654486534 CBV_bit0_RepeatMessageRequestBit_1E384006 0;
BA_ "GenSigTimeoutTime_EVCU2" SG_ 2654486534 CBV_bit0_RepeatMessageRequestBit_1E384006 0;
BA_ "GenSigTimeoutTime_ORC" SG_ 2654486534 CBV_bit0_RepeatMessageRequestBit_1E384006 0;
BA_ "GenSigTimeoutTime_CVADAS" SG_ 2654486669 CBV_bit0_RepeatMessageRequestBit_1E38408D 0;
BA_ "GenSigTimeoutTime_BSM" SG_ 2654486669 CBV_bit0_RepeatMessageRequestBit_1E38408D 0;
BA_ "GenSigTimeoutTime_BSM2" SG_ 2654486669 CBV_bit0_RepeatMessageRequestBit_1E38408D 0;
BA_ "GenSigTimeoutTime_CADM" SG_ 2654486669 CBV_bit0_RepeatMessageRequestBit_1E38408D 0;
BA_ "GenSigTimeoutTime_CVPAM" SG_ 2654486669 CBV_bit0_RepeatMessageRequestBit_1E38408D 0;
BA_ "GenSigTimeoutTime_ECM" SG_ 2654486669 CBV_bit0_RepeatMessageRequestBit_1E38408D 0;
BA_ "GenSigTimeoutTime_EPS" SG_ 2654486669 CBV_bit0_RepeatMessageRequestBit_1E38408D 0;
BA_ "GenSigTimeoutTime_EVCU2" SG_ 2654486669 CBV_bit0_RepeatMessageRequestBit_1E38408D 0;
BA_ "GenSigTimeoutTime_ORC" SG_ 2654486669 CBV_bit0_RepeatMessageRequestBit_1E38408D 0;
BA_ "GenSigTimeoutTime_CVADAS" SG_ 2654486669 CBV_bit6_PartialNtwInfBit_1E38408D 0;
BA_ "GenSigTimeoutTime_BSM" SG_ 2654486669 CBV_bit6_PartialNtwInfBit_1E38408D 0;
BA_ "GenSigTimeoutTime_BSM2" SG_ 2654486669 CBV_bit6_PartialNtwInfBit_1E38408D 0;
BA_ "GenSigTimeoutTime_CADM" SG_ 2654486669 CBV_bit6_PartialNtwInfBit_1E38408D 0;
BA_ "GenSigTimeoutTime_CVPAM" SG_ 2654486669 CBV_bit6_PartialNtwInfBit_1E38408D 0;
BA_ "GenSigTimeoutTime_ECM" SG_ 2654486669 CBV_bit6_PartialNtwInfBit_1E38408D 0;
BA_ "GenSigTimeoutTime_EPS" SG_ 2654486669 CBV_bit6_PartialNtwInfBit_1E38408D 0;
BA_ "GenSigTimeoutTime_EVCU2" SG_ 2654486669 CBV_bit6_PartialNtwInfBit_1E38408D 0;
BA_ "GenSigTimeoutTime_ORC" SG_ 2654486669 CBV_bit6_PartialNtwInfBit_1E38408D 0;
BA_ "GenSigTimeoutTime_CVADAS" SG_ 2654486669 CBV_bit5_1E38408D 0;
BA_ "GenSigTimeoutTime_BSM" SG_ 2654486669 CBV_bit5_1E38408D 0;
BA_ "GenSigTimeoutTime_BSM2" SG_ 2654486669 CBV_bit5_1E38408D 0;
BA_ "GenSigTimeoutTime_CADM" SG_ 2654486669 CBV_bit5_1E38408D 0;
BA_ "GenSigTimeoutTime_CVPAM" SG_ 2654486669 CBV_bit5_1E38408D 0;
BA_ "GenSigTimeoutTime_ECM" SG_ 2654486669 CBV_bit5_1E38408D 0;
BA_ "GenSigTimeoutTime_EPS" SG_ 2654486669 CBV_bit5_1E38408D 0;
BA_ "GenSigTimeoutTime_EVCU2" SG_ 2654486669 CBV_bit5_1E38408D 0;
BA_ "GenSigTimeoutTime_ORC" SG_ 2654486669 CBV_bit5_1E38408D 0;
BA_ "GenSigTimeoutTime_CVADAS" SG_ 2654486669 CBV_bit4_ActiveWakeupBit_1E38408D 0;
BA_ "GenSigTimeoutTime_BSM" SG_ 2654486669 CBV_bit4_ActiveWakeupBit_1E38408D 0;
BA_ "GenSigTimeoutTime_BSM2" SG_ 2654486669 CBV_bit4_ActiveWakeupBit_1E38408D 0;
BA_ "GenSigTimeoutTime_CADM" SG_ 2654486669 CBV_bit4_ActiveWakeupBit_1E38408D 0;
BA_ "GenSigTimeoutTime_CVPAM" SG_ 2654486669 CBV_bit4_ActiveWakeupBit_1E38408D 0;
BA_ "GenSigTimeoutTime_ECM" SG_ 2654486669 CBV_bit4_ActiveWakeupBit_1E38408D 0;
BA_ "GenSigTimeoutTime_EPS" SG_ 2654486669 CBV_bit4_ActiveWakeupBit_1E38408D 0;
BA_ "GenSigTimeoutTime_EVCU2" SG_ 2654486669 CBV_bit4_ActiveWakeupBit_1E38408D 0;
BA_ "GenSigTimeoutTime_ORC" SG_ 2654486669 CBV_bit4_ActiveWakeupBit_1E38408D 0;
BA_ "GenSigTimeoutTime_CVADAS" SG_ 2654486669 CBV_bit3_NMCoordinatorBit_1E38408D 0;
BA_ "GenSigTimeoutTime_BSM" SG_ 2654486669 CBV_bit3_NMCoordinatorBit_1E38408D 0;
BA_ "GenSigTimeoutTime_BSM2" SG_ 2654486669 CBV_bit3_NMCoordinatorBit_1E38408D 0;
BA_ "GenSigTimeoutTime_CADM" SG_ 2654486669 CBV_bit3_NMCoordinatorBit_1E38408D 0;
BA_ "GenSigTimeoutTime_CVPAM" SG_ 2654486669 CBV_bit3_NMCoordinatorBit_1E38408D 0;
BA_ "GenSigTimeoutTime_ECM" SG_ 2654486669 CBV_bit3_NMCoordinatorBit_1E38408D 0;
BA_ "GenSigTimeoutTime_EPS" SG_ 2654486669 CBV_bit3_NMCoordinatorBit_1E38408D 0;
BA_ "GenSigTimeoutTime_EVCU2" SG_ 2654486669 CBV_bit3_NMCoordinatorBit_1E38408D 0;
BA_ "GenSigTimeoutTime_ORC" SG_ 2654486669 CBV_bit3_NMCoordinatorBit_1E38408D 0;
BA_ "GenSigTimeoutTime_CVADAS" SG_ 2654486669 CBV_bit2_1E38408D 0;
BA_ "GenSigTimeoutTime_BSM" SG_ 2654486669 CBV_bit2_1E38408D 0;
BA_ "GenSigTimeoutTime_BSM2" SG_ 2654486669 CBV_bit2_1E38408D 0;
BA_ "GenSigTimeoutTime_CADM" SG_ 2654486669 CBV_bit2_1E38408D 0;
BA_ "GenSigTimeoutTime_CVPAM" SG_ 2654486669 CBV_bit2_1E38408D 0;
BA_ "GenSigTimeoutTime_ECM" SG_ 2654486669 CBV_bit2_1E38408D 0;
BA_ "GenSigTimeoutTime_EPS" SG_ 2654486669 CBV_bit2_1E38408D 0;
BA_ "GenSigTimeoutTime_EVCU2" SG_ 2654486669 CBV_bit2_1E38408D 0;
BA_ "GenSigTimeoutTime_ORC" SG_ 2654486669 CBV_bit2_1E38408D 0;
BA_ "GenSigTimeoutTime_CVADAS" SG_ 2654486669 CBV_bit1_1E38408D 0;
BA_ "GenSigTimeoutTime_BSM" SG_ 2654486669 CBV_bit1_1E38408D 0;
BA_ "GenSigTimeoutTime_BSM2" SG_ 2654486669 CBV_bit1_1E38408D 0;
BA_ "GenSigTimeoutTime_CADM" SG_ 2654486669 CBV_bit1_1E38408D 0;
BA_ "GenSigTimeoutTime_CVPAM" SG_ 2654486669 CBV_bit1_1E38408D 0;
BA_ "GenSigTimeoutTime_ECM" SG_ 2654486669 CBV_bit1_1E38408D 0;
BA_ "GenSigTimeoutTime_EPS" SG_ 2654486669 CBV_bit1_1E38408D 0;
BA_ "GenSigTimeoutTime_EVCU2" SG_ 2654486669 CBV_bit1_1E38408D 0;
BA_ "GenSigTimeoutTime_ORC" SG_ 2654486669 CBV_bit1_1E38408D 0;
BA_ "GenSigTimeoutTime_CVADAS" SG_ 2654486669 SourceNodeIdentifier_1E38408D 0;
BA_ "GenSigTimeoutTime_BSM" SG_ 2654486669 SourceNodeIdentifier_1E38408D 0;
BA_ "GenSigTimeoutTime_BSM2" SG_ 2654486669 SourceNodeIdentifier_1E38408D 0;
BA_ "GenSigTimeoutTime_CADM" SG_ 2654486669 SourceNodeIdentifier_1E38408D 0;
BA_ "GenSigTimeoutTime_CVPAM" SG_ 2654486669 SourceNodeIdentifier_1E38408D 0;
BA_ "GenSigTimeoutTime_ECM" SG_ 2654486669 SourceNodeIdentifier_1E38408D 0;
BA_ "GenSigTimeoutTime_EPS" SG_ 2654486669 SourceNodeIdentifier_1E38408D 0;
BA_ "GenSigTimeoutTime_EVCU2" SG_ 2654486669 SourceNodeIdentifier_1E38408D 0;
BA_ "GenSigTimeoutTime_ORC" SG_ 2654486669 SourceNodeIdentifier_1E38408D 0;
BA_ "GenSigTimeoutTime_CVADAS" SG_ 2654486669 CBV_bit7_1E38408D 0;
BA_ "GenSigTimeoutTime_BSM" SG_ 2654486669 CBV_bit7_1E38408D 0;
BA_ "GenSigTimeoutTime_BSM2" SG_ 2654486669 CBV_bit7_1E38408D 0;
BA_ "GenSigTimeoutTime_CADM" SG_ 2654486669 CBV_bit7_1E38408D 0;
BA_ "GenSigTimeoutTime_CVPAM" SG_ 2654486669 CBV_bit7_1E38408D 0;
BA_ "GenSigTimeoutTime_ECM" SG_ 2654486669 CBV_bit7_1E38408D 0;
BA_ "GenSigTimeoutTime_EPS" SG_ 2654486669 CBV_bit7_1E38408D 0;
BA_ "GenSigTimeoutTime_EVCU2" SG_ 2654486669 CBV_bit7_1E38408D 0;
BA_ "GenSigTimeoutTime_ORC" SG_ 2654486669 CBV_bit7_1E38408D 0;
BA_ "GenSigTimeoutTime_ADCAM" SG_ 2654486529 SourceNodeIdentifier_1E384001 0;
BA_ "GenSigTimeoutTime_CVADAS" SG_ 2654486529 SourceNodeIdentifier_1E384001 0;
BA_ "GenSigTimeoutTime_VDCM" SG_ 2654486529 SourceNodeIdentifier_1E384001 0;
BA_ "GenSigTimeoutTime_ADCAM" SG_ 2654486529 CBV_bit7_1E384001 0;
BA_ "GenSigTimeoutTime_CVADAS" SG_ 2654486529 CBV_bit7_1E384001 0;
BA_ "GenSigTimeoutTime_VDCM" SG_ 2654486529 CBV_bit7_1E384001 0;
BA_ "GenSigTimeoutTime_ADCAM" SG_ 2654486529 CBV_bit6_PartialNtwInfBit_1E384001 0;
BA_ "GenSigTimeoutTime_CVADAS" SG_ 2654486529 CBV_bit6_PartialNtwInfBit_1E384001 0;
BA_ "GenSigTimeoutTime_VDCM" SG_ 2654486529 CBV_bit6_PartialNtwInfBit_1E384001 0;
BA_ "GenSigTimeoutTime_BSM" SG_ 2654486529 CBV_bit5_1E384001 0;
BA_ "GenSigTimeoutTime_BSM2" SG_ 2654486529 CBV_bit5_1E384001 0;
BA_ "GenSigTimeoutTime_CADM" SG_ 2654486529 CBV_bit5_1E384001 0;
BA_ "GenSigTimeoutTime_CVPAM" SG_ 2654486529 CBV_bit5_1E384001 0;
BA_ "GenSigTimeoutTime_ECM" SG_ 2654486529 CBV_bit5_1E384001 0;
BA_ "GenSigTimeoutTime_EPS" SG_ 2654486529 CBV_bit5_1E384001 0;
BA_ "GenSigTimeoutTime_EVCU2" SG_ 2654486529 CBV_bit5_1E384001 0;
BA_ "GenSigTimeoutTime_ADCAM" SG_ 2654486529 CBV_bit5_1E384001 0;
BA_ "GenSigTimeoutTime_CVADAS" SG_ 2654486529 CBV_bit5_1E384001 0;
BA_ "GenSigTimeoutTime_VDCM" SG_ 2654486529 CBV_bit5_1E384001 0;
BA_ "GenSigTimeoutTime_BSM" SG_ 2654486529 CBV_bit4_ActiveWakeupBit_1E384001 0;
BA_ "GenSigTimeoutTime_BSM2" SG_ 2654486529 CBV_bit4_ActiveWakeupBit_1E384001 0;
BA_ "GenSigTimeoutTime_CADM" SG_ 2654486529 CBV_bit4_ActiveWakeupBit_1E384001 0;
BA_ "GenSigTimeoutTime_CVPAM" SG_ 2654486529 CBV_bit4_ActiveWakeupBit_1E384001 0;
BA_ "GenSigTimeoutTime_ECM" SG_ 2654486529 CBV_bit4_ActiveWakeupBit_1E384001 0;
BA_ "GenSigTimeoutTime_EPS" SG_ 2654486529 CBV_bit4_ActiveWakeupBit_1E384001 0;
BA_ "GenSigTimeoutTime_EVCU2" SG_ 2654486529 CBV_bit4_ActiveWakeupBit_1E384001 0;
BA_ "GenSigTimeoutTime_ORC" SG_ 2654486529 CBV_bit4_ActiveWakeupBit_1E384001 0;
BA_ "GenSigTimeoutTime_ADCAM" SG_ 2654486529 CBV_bit4_ActiveWakeupBit_1E384001 0;
BA_ "GenSigTimeoutTime_CVADAS" SG_ 2654486529 CBV_bit4_ActiveWakeupBit_1E384001 0;
BA_ "GenSigTimeoutTime_VDCM" SG_ 2654486529 CBV_bit4_ActiveWakeupBit_1E384001 0;
BA_ "GenSigTimeoutTime_BSM" SG_ 2654486534 CBV_bit1_1E384006 0;
BA_ "GenSigTimeoutTime_BSM2" SG_ 2654486534 CBV_bit1_1E384006 0;
BA_ "GenSigTimeoutTime_CADM" SG_ 2654486534 CBV_bit1_1E384006 0;
BA_ "GenSigTimeoutTime_CVPAM" SG_ 2654486534 CBV_bit1_1E384006 0;
BA_ "GenSigTimeoutTime_ECM" SG_ 2654486534 CBV_bit1_1E384006 0;
BA_ "GenSigTimeoutTime_EPS" SG_ 2654486534 CBV_bit1_1E384006 0;
BA_ "GenSigTimeoutTime_EVCU2" SG_ 2654486534 CBV_bit1_1E384006 0;
BA_ "GenSigTimeoutTime_ORC" SG_ 2654486534 CBV_bit1_1E384006 0;
BA_ "GenSigTimeoutTime_BSM" SG_ 2654486534 CBV_bit2_1E384006 0;
BA_ "GenSigTimeoutTime_BSM2" SG_ 2654486534 CBV_bit2_1E384006 0;
BA_ "GenSigTimeoutTime_CADM" SG_ 2654486534 CBV_bit2_1E384006 0;
BA_ "GenSigTimeoutTime_CVPAM" SG_ 2654486534 CBV_bit2_1E384006 0;
BA_ "GenSigTimeoutTime_ECM" SG_ 2654486534 CBV_bit2_1E384006 0;
BA_ "GenSigTimeoutTime_EPS" SG_ 2654486534 CBV_bit2_1E384006 0;
BA_ "GenSigTimeoutTime_EVCU2" SG_ 2654486534 CBV_bit2_1E384006 0;
BA_ "GenSigTimeoutTime_ORC" SG_ 2654486534 CBV_bit2_1E384006 0;
BA_ "GenSigTimeoutTime_BSM" SG_ 2654486534 CBV_bit3_NMCoordinatorBit_1E384006 0;
BA_ "GenSigTimeoutTime_BSM2" SG_ 2654486534 CBV_bit3_NMCoordinatorBit_1E384006 0;
BA_ "GenSigTimeoutTime_CADM" SG_ 2654486534 CBV_bit3_NMCoordinatorBit_1E384006 0;
BA_ "GenSigTimeoutTime_CVPAM" SG_ 2654486534 CBV_bit3_NMCoordinatorBit_1E384006 0;
BA_ "GenSigTimeoutTime_ECM" SG_ 2654486534 CBV_bit3_NMCoordinatorBit_1E384006 0;
BA_ "GenSigTimeoutTime_EPS" SG_ 2654486534 CBV_bit3_NMCoordinatorBit_1E384006 0;
BA_ "GenSigTimeoutTime_EVCU2" SG_ 2654486534 CBV_bit3_NMCoordinatorBit_1E384006 0;
BA_ "GenSigTimeoutTime_ORC" SG_ 2654486534 CBV_bit3_NMCoordinatorBit_1E384006 0;
BA_ "GenSigTimeoutTime_BSM" SG_ 2654486534 CBV_bit4_ActiveWakeupBit_1E384006 0;
BA_ "GenSigTimeoutTime_BSM2" SG_ 2654486534 CBV_bit4_ActiveWakeupBit_1E384006 0;
BA_ "GenSigTimeoutTime_CADM" SG_ 2654486534 CBV_bit4_ActiveWakeupBit_1E384006 0;
BA_ "GenSigTimeoutTime_CVPAM" SG_ 2654486534 CBV_bit4_ActiveWakeupBit_1E384006 0;
BA_ "GenSigTimeoutTime_ECM" SG_ 2654486534 CBV_bit4_ActiveWakeupBit_1E384006 0;
BA_ "GenSigTimeoutTime_EPS" SG_ 2654486534 CBV_bit4_ActiveWakeupBit_1E384006 0;
BA_ "GenSigTimeoutTime_EVCU2" SG_ 2654486534 CBV_bit4_ActiveWakeupBit_1E384006 0;
BA_ "GenSigTimeoutTime_ORC" SG_ 2654486534 CBV_bit4_ActiveWakeupBit_1E384006 0;
BA_ "GenSigTimeoutTime_BSM" SG_ 2654486534 CBV_bit5_1E384006 0;
BA_ "GenSigTimeoutTime_BSM2" SG_ 2654486534 CBV_bit5_1E384006 0;
BA_ "GenSigTimeoutTime_CADM" SG_ 2654486534 CBV_bit5_1E384006 0;
BA_ "GenSigTimeoutTime_CVPAM" SG_ 2654486534 CBV_bit5_1E384006 0;
BA_ "GenSigTimeoutTime_ECM" SG_ 2654486534 CBV_bit5_1E384006 0;
BA_ "GenSigTimeoutTime_EPS" SG_ 2654486534 CBV_bit5_1E384006 0;
BA_ "GenSigTimeoutTime_EVCU2" SG_ 2654486534 CBV_bit5_1E384006 0;
BA_ "GenSigTimeoutTime_ORC" SG_ 2654486534 CBV_bit5_1E384006 0;
BA_ "GenSigSendType" SG_ 1456 Driver_Model 3;
BA_ "GenSigTimeoutTime_BSM" SG_ 1456 Driver_Model 0;
BA_ "GenSigTimeoutTime_BSM2" SG_ 1456 Driver_Model 0;
BA_ "GenSigTimeoutTime_CADM" SG_ 1456 Driver_Model 0;
BA_ "GenSigTimeoutTime_CVPAM" SG_ 1456 Driver_Model 0;
BA_ "GenSigTimeoutTime_ECM" SG_ 1456 Driver_Model 0;
BA_ "GenSigTimeoutTime_EPS" SG_ 1456 Driver_Model 0;
BA_ "GenSigTimeoutTime_EVCU2" SG_ 1456 Driver_Model 0;
BA_ "GenSigSendType" SG_ 1456 BSS_SRV_RQSts 3;
BA_ "GenSigTimeoutTime_BSM" SG_ 1456 BSS_SRV_RQSts 0;
BA_ "GenSigTimeoutTime_BSM2" SG_ 1456 BSS_SRV_RQSts 0;
BA_ "GenSigTimeoutTime_CADM" SG_ 1456 BSS_SRV_RQSts 0;
BA_ "GenSigTimeoutTime_CVPAM" SG_ 1456 BSS_SRV_RQSts 0;
BA_ "GenSigTimeoutTime_ECM" SG_ 1456 BSS_SRV_RQSts 0;
BA_ "GenSigTimeoutTime_EPS" SG_ 1456 BSS_SRV_RQSts 0;
BA_ "GenSigTimeoutTime_EVCU2" SG_ 1456 BSS_SRV_RQSts 0;
BA_ "GenSigTimeoutTime_CADM" SG_ 1456 CRC_ADAS_FD_HMI 0;
BA_ "GenSigTimeoutTime_CVPAM" SG_ 1456 CRC_ADAS_FD_HMI 0;
BA_ "GenSigTimeoutTime_EVCU2" SG_ 1456 CRC_ADAS_FD_HMI 0;
BA_ "GenSigTimeoutTime_ORC" SG_ 1456 CRC_ADAS_FD_HMI 0;
BA_ "GenSigSendType" SG_ 1456 Chime_Priority 3;
BA_ "GenSigTimeoutTime_BSM" SG_ 1456 Chime_Priority 0;
BA_ "GenSigTimeoutTime_BSM2" SG_ 1456 Chime_Priority 0;
BA_ "GenSigTimeoutTime_CADM" SG_ 1456 Chime_Priority 0;
BA_ "GenSigTimeoutTime_CVPAM" SG_ 1456 Chime_Priority 0;
BA_ "GenSigTimeoutTime_ECM" SG_ 1456 Chime_Priority 0;
BA_ "GenSigTimeoutTime_EPS" SG_ 1456 Chime_Priority 0;
BA_ "GenSigTimeoutTime_EVCU2" SG_ 1456 Chime_Priority 0;
BA_ "GenSigTimeoutTime_ORC" SG_ 1456 Chime_Priority 0;
BA_ "GenSigSendType" SG_ 1456 RR_Chime_RqSts 3;
BA_ "GenSigTimeoutTime_BSM" SG_ 1456 RR_Chime_RqSts 0;
BA_ "GenSigTimeoutTime_BSM2" SG_ 1456 RR_Chime_RqSts 0;
BA_ "GenSigTimeoutTime_CADM" SG_ 1456 RR_Chime_RqSts 0;
BA_ "GenSigTimeoutTime_CVPAM" SG_ 1456 RR_Chime_RqSts 0;
BA_ "GenSigTimeoutTime_ECM" SG_ 1456 RR_Chime_RqSts 0;
BA_ "GenSigTimeoutTime_EPS" SG_ 1456 RR_Chime_RqSts 0;
BA_ "GenSigTimeoutTime_EVCU2" SG_ 1456 RR_Chime_RqSts 0;
BA_ "GenSigSendType" SG_ 1456 LR_Chime_RqSts 3;
BA_ "GenSigTimeoutTime_BSM" SG_ 1456 LR_Chime_RqSts 0;
BA_ "GenSigTimeoutTime_BSM2" SG_ 1456 LR_Chime_RqSts 0;
BA_ "GenSigTimeoutTime_CADM" SG_ 1456 LR_Chime_RqSts 0;
BA_ "GenSigTimeoutTime_CVPAM" SG_ 1456 LR_Chime_RqSts 0;
BA_ "GenSigTimeoutTime_ECM" SG_ 1456 LR_Chime_RqSts 0;
BA_ "GenSigTimeoutTime_EPS" SG_ 1456 LR_Chime_RqSts 0;
BA_ "GenSigTimeoutTime_EVCU2" SG_ 1456 LR_Chime_RqSts 0;
BA_ "GenSigTimeoutTime_CADM" SG_ 1456 MessageCounter_ADAS_FD_HMI 0;
BA_ "GenSigTimeoutTime_CVPAM" SG_ 1456 MessageCounter_ADAS_FD_HMI 0;
BA_ "GenSigTimeoutTime_EVCU2" SG_ 1456 MessageCounter_ADAS_FD_HMI 0;
BA_ "GenSigTimeoutTime_ORC" SG_ 1456 MessageCounter_ADAS_FD_HMI 0;
BA_ "GenSigSendType" SG_ 1456 Lane_DispPopupSts 3;
BA_ "GenSigTimeoutTime_BSM" SG_ 1456 Lane_DispPopupSts 0;
BA_ "GenSigTimeoutTime_BSM2" SG_ 1456 Lane_DispPopupSts 0;
BA_ "GenSigTimeoutTime_CADM" SG_ 1456 Lane_DispPopupSts 0;
BA_ "GenSigTimeoutTime_CVPAM" SG_ 1456 Lane_DispPopupSts 0;
BA_ "GenSigTimeoutTime_ECM" SG_ 1456 Lane_DispPopupSts 0;
BA_ "GenSigTimeoutTime_EPS" SG_ 1456 Lane_DispPopupSts 0;
BA_ "GenSigTimeoutTime_EVCU2" SG_ 1456 Lane_DispPopupSts 0;
BA_ "GenSigTimeoutTime_ORC" SG_ 1456 Lane_DispPopupSts 0;
BA_ "GenSigTimeoutTime_MPAD" SG_ 2654486552 SourceNodeIdentifier_1E384018 0;
BA_ "GenSigTimeoutTime_ADCAM" SG_ 2654486552 SourceNodeIdentifier_1E384018 0;
BA_ "GenSigTimeoutTime_CVADAS" SG_ 2654486552 SourceNodeIdentifier_1E384018 0;
BA_ "GenSigTimeoutTime_VDCM" SG_ 2654486552 SourceNodeIdentifier_1E384018 0;
BA_ "GenSigTimeoutTime_MPAD" SG_ 2654486552 CBV_bit0_RepeatMessageRequestBit_1E384018 0;
BA_ "GenSigTimeoutTime_ADCAM" SG_ 2654486552 CBV_bit0_RepeatMessageRequestBit_1E384018 0;
BA_ "GenSigTimeoutTime_CVADAS" SG_ 2654486552 CBV_bit0_RepeatMessageRequestBit_1E384018 0;
BA_ "GenSigTimeoutTime_VDCM" SG_ 2654486552 CBV_bit0_RepeatMessageRequestBit_1E384018 0;
BA_ "GenSigTimeoutTime_BSM" SG_ 2654486552 CBV_bit0_RepeatMessageRequestBit_1E384018 0;
BA_ "GenSigTimeoutTime_BSM2" SG_ 2654486552 CBV_bit0_RepeatMessageRequestBit_1E384018 0;
BA_ "GenSigTimeoutTime_CADM" SG_ 2654486552 CBV_bit0_RepeatMessageRequestBit_1E384018 0;
BA_ "GenSigTimeoutTime_CVPAM" SG_ 2654486552 CBV_bit0_RepeatMessageRequestBit_1E384018 0;
BA_ "GenSigTimeoutTime_ECM" SG_ 2654486552 CBV_bit0_RepeatMessageRequestBit_1E384018 0;
BA_ "GenSigTimeoutTime_EPS" SG_ 2654486552 CBV_bit0_RepeatMessageRequestBit_1E384018 0;
BA_ "GenSigTimeoutTime_EVCU2" SG_ 2654486552 CBV_bit0_RepeatMessageRequestBit_1E384018 0;
BA_ "GenSigTimeoutTime_ORC" SG_ 2654486552 CBV_bit0_RepeatMessageRequestBit_1E384018 0;
BA_ "GenSigTimeoutTime_MPAD" SG_ 2654486552 CBV_bit1_1E384018 0;
BA_ "GenSigTimeoutTime_ADCAM" SG_ 2654486552 CBV_bit1_1E384018 0;
BA_ "GenSigTimeoutTime_CVADAS" SG_ 2654486552 CBV_bit1_1E384018 0;
BA_ "GenSigTimeoutTime_VDCM" SG_ 2654486552 CBV_bit1_1E384018 0;
BA_ "GenSigTimeoutTime_BSM" SG_ 2654486552 CBV_bit1_1E384018 0;
BA_ "GenSigTimeoutTime_BSM2" SG_ 2654486552 CBV_bit1_1E384018 0;
BA_ "GenSigTimeoutTime_CADM" SG_ 2654486552 CBV_bit1_1E384018 0;
BA_ "GenSigTimeoutTime_CVPAM" SG_ 2654486552 CBV_bit1_1E384018 0;
BA_ "GenSigTimeoutTime_ECM" SG_ 2654486552 CBV_bit1_1E384018 0;
BA_ "GenSigTimeoutTime_EPS" SG_ 2654486552 CBV_bit1_1E384018 0;
BA_ "GenSigTimeoutTime_EVCU2" SG_ 2654486552 CBV_bit1_1E384018 0;
BA_ "GenSigTimeoutTime_ORC" SG_ 2654486552 CBV_bit1_1E384018 0;
BA_ "GenSigTimeoutTime_EVCU2" SG_ 2654486552 CBV_bit3_NMCoordinatorBit_1E384018 0;
BA_ "GenSigTimeoutTime_ORC" SG_ 2654486552 CBV_bit3_NMCoordinatorBit_1E384018 0;
BA_ "GenSigTimeoutTime_MPAD" SG_ 2654486552 CBV_bit3_NMCoordinatorBit_1E384018 0;
BA_ "GenSigTimeoutTime_ADCAM" SG_ 2654486552 CBV_bit3_NMCoordinatorBit_1E384018 0;
BA_ "GenSigTimeoutTime_CVADAS" SG_ 2654486552 CBV_bit3_NMCoordinatorBit_1E384018 0;
BA_ "GenSigTimeoutTime_VDCM" SG_ 2654486552 CBV_bit3_NMCoordinatorBit_1E384018 0;
BA_ "GenSigTimeoutTime_BSM" SG_ 2654486552 CBV_bit3_NMCoordinatorBit_1E384018 0;
BA_ "GenSigTimeoutTime_BSM2" SG_ 2654486552 CBV_bit3_NMCoordinatorBit_1E384018 0;
BA_ "GenSigTimeoutTime_CADM" SG_ 2654486552 CBV_bit3_NMCoordinatorBit_1E384018 0;
BA_ "GenSigTimeoutTime_CVPAM" SG_ 2654486552 CBV_bit3_NMCoordinatorBit_1E384018 0;
BA_ "GenSigTimeoutTime_ECM" SG_ 2654486552 CBV_bit3_NMCoordinatorBit_1E384018 0;
BA_ "GenSigTimeoutTime_EPS" SG_ 2654486552 CBV_bit3_NMCoordinatorBit_1E384018 0;
BA_ "GenSigTimeoutTime_MPAD" SG_ 2654486552 CBV_bit2_1E384018 0;
BA_ "GenSigTimeoutTime_ADCAM" SG_ 2654486552 CBV_bit2_1E384018 0;
BA_ "GenSigTimeoutTime_CVADAS" SG_ 2654486552 CBV_bit2_1E384018 0;
BA_ "GenSigTimeoutTime_VDCM" SG_ 2654486552 CBV_bit2_1E384018 0;
BA_ "GenSigTimeoutTime_BSM" SG_ 2654486552 CBV_bit2_1E384018 0;
BA_ "GenSigTimeoutTime_BSM2" SG_ 2654486552 CBV_bit2_1E384018 0;
BA_ "GenSigTimeoutTime_CADM" SG_ 2654486552 CBV_bit2_1E384018 0;
BA_ "GenSigTimeoutTime_CVPAM" SG_ 2654486552 CBV_bit2_1E384018 0;
BA_ "GenSigTimeoutTime_ECM" SG_ 2654486552 CBV_bit2_1E384018 0;
BA_ "GenSigTimeoutTime_EPS" SG_ 2654486552 CBV_bit2_1E384018 0;
BA_ "GenSigTimeoutTime_EVCU2" SG_ 2654486552 CBV_bit2_1E384018 0;
BA_ "GenSigTimeoutTime_ORC" SG_ 2654486552 CBV_bit2_1E384018 0;
BA_ "GenSigTimeoutTime_BSM" SG_ 2654486552 CBV_bit7_1E384018 0;
BA_ "GenSigTimeoutTime_BSM2" SG_ 2654486552 CBV_bit7_1E384018 0;
BA_ "GenSigTimeoutTime_MPAD" SG_ 2654486552 CBV_bit7_1E384018 0;
BA_ "GenSigTimeoutTime_ADCAM" SG_ 2654486552 CBV_bit7_1E384018 0;
BA_ "GenSigTimeoutTime_CVADAS" SG_ 2654486552 CBV_bit7_1E384018 0;
BA_ "GenSigTimeoutTime_VDCM" SG_ 2654486552 CBV_bit7_1E384018 0;
BA_ "GenSigTimeoutTime_BSM" SG_ 2654486552 CBV_bit6_PartialNtwInfBit_1E384018 0;
BA_ "GenSigTimeoutTime_BSM2" SG_ 2654486552 CBV_bit6_PartialNtwInfBit_1E384018 0;
BA_ "GenSigTimeoutTime_CADM" SG_ 2654486552 CBV_bit6_PartialNtwInfBit_1E384018 0;
BA_ "GenSigTimeoutTime_CVPAM" SG_ 2654486552 CBV_bit6_PartialNtwInfBit_1E384018 0;
BA_ "GenSigTimeoutTime_ECM" SG_ 2654486552 CBV_bit6_PartialNtwInfBit_1E384018 0;
BA_ "GenSigTimeoutTime_EPS" SG_ 2654486552 CBV_bit6_PartialNtwInfBit_1E384018 0;
BA_ "GenSigTimeoutTime_EVCU2" SG_ 2654486552 CBV_bit6_PartialNtwInfBit_1E384018 0;
BA_ "GenSigTimeoutTime_ORC" SG_ 2654486552 CBV_bit6_PartialNtwInfBit_1E384018 0;
BA_ "GenSigTimeoutTime_MPAD" SG_ 2654486552 CBV_bit6_PartialNtwInfBit_1E384018 0;
BA_ "GenSigTimeoutTime_ADCAM" SG_ 2654486552 CBV_bit6_PartialNtwInfBit_1E384018 0;
BA_ "GenSigTimeoutTime_CVADAS" SG_ 2654486552 CBV_bit6_PartialNtwInfBit_1E384018 0;
BA_ "GenSigTimeoutTime_VDCM" SG_ 2654486552 CBV_bit6_PartialNtwInfBit_1E384018 0;
BA_ "GenSigTimeoutTime_BSM" SG_ 2654486552 CBV_bit5_1E384018 0;
BA_ "GenSigTimeoutTime_BSM2" SG_ 2654486552 CBV_bit5_1E384018 0;
BA_ "GenSigTimeoutTime_CADM" SG_ 2654486552 CBV_bit5_1E384018 0;
BA_ "GenSigTimeoutTime_CVPAM" SG_ 2654486552 CBV_bit5_1E384018 0;
BA_ "GenSigTimeoutTime_ECM" SG_ 2654486552 CBV_bit5_1E384018 0;
BA_ "GenSigTimeoutTime_EPS" SG_ 2654486552 CBV_bit5_1E384018 0;
BA_ "GenSigTimeoutTime_EVCU2" SG_ 2654486552 CBV_bit5_1E384018 0;
BA_ "GenSigTimeoutTime_ORC" SG_ 2654486552 CBV_bit5_1E384018 0;
BA_ "GenSigTimeoutTime_MPAD" SG_ 2654486552 CBV_bit5_1E384018 0;
BA_ "GenSigTimeoutTime_ADCAM" SG_ 2654486552 CBV_bit5_1E384018 0;
BA_ "GenSigTimeoutTime_CVADAS" SG_ 2654486552 CBV_bit5_1E384018 0;
BA_ "GenSigTimeoutTime_VDCM" SG_ 2654486552 CBV_bit5_1E384018 0;
BA_ "GenSigTimeoutTime_BSM" SG_ 2654486552 CBV_bit4_ActiveWakeupBit_1E384018 0;
BA_ "GenSigTimeoutTime_BSM2" SG_ 2654486552 CBV_bit4_ActiveWakeupBit_1E384018 0;
BA_ "GenSigTimeoutTime_CADM" SG_ 2654486552 CBV_bit4_ActiveWakeupBit_1E384018 0;
BA_ "GenSigTimeoutTime_CVPAM" SG_ 2654486552 CBV_bit4_ActiveWakeupBit_1E384018 0;
BA_ "GenSigTimeoutTime_ECM" SG_ 2654486552 CBV_bit4_ActiveWakeupBit_1E384018 0;
BA_ "GenSigTimeoutTime_EPS" SG_ 2654486552 CBV_bit4_ActiveWakeupBit_1E384018 0;
BA_ "GenSigTimeoutTime_EVCU2" SG_ 2654486552 CBV_bit4_ActiveWakeupBit_1E384018 0;
BA_ "GenSigTimeoutTime_ORC" SG_ 2654486552 CBV_bit4_ActiveWakeupBit_1E384018 0;
BA_ "GenSigTimeoutTime_MPAD" SG_ 2654486552 CBV_bit4_ActiveWakeupBit_1E384018 0;
BA_ "GenSigTimeoutTime_ADCAM" SG_ 2654486552 CBV_bit4_ActiveWakeupBit_1E384018 0;
BA_ "GenSigTimeoutTime_CVADAS" SG_ 2654486552 CBV_bit4_ActiveWakeupBit_1E384018 0;
BA_ "GenSigTimeoutTime_VDCM" SG_ 2654486552 CBV_bit4_ActiveWakeupBit_1E384018 0;
BA_ "GenSigTimeoutTime_MPAD" SG_ 2654486676 CBV_bit0_RepeatMessageRequestBit_1E384094 0;
BA_ "GenSigTimeoutTime_ADCAM" SG_ 2654486676 CBV_bit0_RepeatMessageRequestBit_1E384094 0;
BA_ "GenSigTimeoutTime_CVADAS" SG_ 2654486676 CBV_bit0_RepeatMessageRequestBit_1E384094 0;
BA_ "GenSigTimeoutTime_BSM" SG_ 2654486676 CBV_bit0_RepeatMessageRequestBit_1E384094 0;
BA_ "GenSigTimeoutTime_BSM2" SG_ 2654486676 CBV_bit0_RepeatMessageRequestBit_1E384094 0;
BA_ "GenSigTimeoutTime_CADM" SG_ 2654486676 CBV_bit0_RepeatMessageRequestBit_1E384094 0;
BA_ "GenSigTimeoutTime_CVPAM" SG_ 2654486676 CBV_bit0_RepeatMessageRequestBit_1E384094 0;
BA_ "GenSigTimeoutTime_ECM" SG_ 2654486676 CBV_bit0_RepeatMessageRequestBit_1E384094 0;
BA_ "GenSigTimeoutTime_EPS" SG_ 2654486676 CBV_bit0_RepeatMessageRequestBit_1E384094 0;
BA_ "GenSigTimeoutTime_EVCU2" SG_ 2654486676 CBV_bit0_RepeatMessageRequestBit_1E384094 0;
BA_ "GenSigTimeoutTime_ORC" SG_ 2654486676 CBV_bit0_RepeatMessageRequestBit_1E384094 0;
BA_ "GenSigTimeoutTime_MPAD" SG_ 2654486676 CBV_bit2_1E384094 0;
BA_ "GenSigTimeoutTime_ADCAM" SG_ 2654486676 CBV_bit2_1E384094 0;
BA_ "GenSigTimeoutTime_CVADAS" SG_ 2654486676 CBV_bit2_1E384094 0;
BA_ "GenSigTimeoutTime_BSM" SG_ 2654486676 CBV_bit2_1E384094 0;
BA_ "GenSigTimeoutTime_BSM2" SG_ 2654486676 CBV_bit2_1E384094 0;
BA_ "GenSigTimeoutTime_CADM" SG_ 2654486676 CBV_bit2_1E384094 0;
BA_ "GenSigTimeoutTime_CVPAM" SG_ 2654486676 CBV_bit2_1E384094 0;
BA_ "GenSigTimeoutTime_ECM" SG_ 2654486676 CBV_bit2_1E384094 0;
BA_ "GenSigTimeoutTime_EPS" SG_ 2654486676 CBV_bit2_1E384094 0;
BA_ "GenSigTimeoutTime_EVCU2" SG_ 2654486676 CBV_bit2_1E384094 0;
BA_ "GenSigTimeoutTime_ORC" SG_ 2654486676 CBV_bit2_1E384094 0;
BA_ "GenSigTimeoutTime_MPAD" SG_ 2654486676 CBV_bit1_1E384094 0;
BA_ "GenSigTimeoutTime_ADCAM" SG_ 2654486676 CBV_bit1_1E384094 0;
BA_ "GenSigTimeoutTime_CVADAS" SG_ 2654486676 CBV_bit1_1E384094 0;
BA_ "GenSigTimeoutTime_BSM" SG_ 2654486676 CBV_bit1_1E384094 0;
BA_ "GenSigTimeoutTime_BSM2" SG_ 2654486676 CBV_bit1_1E384094 0;
BA_ "GenSigTimeoutTime_CADM" SG_ 2654486676 CBV_bit1_1E384094 0;
BA_ "GenSigTimeoutTime_CVPAM" SG_ 2654486676 CBV_bit1_1E384094 0;
BA_ "GenSigTimeoutTime_ECM" SG_ 2654486676 CBV_bit1_1E384094 0;
BA_ "GenSigTimeoutTime_EPS" SG_ 2654486676 CBV_bit1_1E384094 0;
BA_ "GenSigTimeoutTime_EVCU2" SG_ 2654486676 CBV_bit1_1E384094 0;
BA_ "GenSigTimeoutTime_ORC" SG_ 2654486676 CBV_bit1_1E384094 0;
BA_ "GenSigTimeoutTime_MPAD" SG_ 2654486676 SourceNodeIdentifier_1E384094 0;
BA_ "GenSigTimeoutTime_ADCAM" SG_ 2654486676 SourceNodeIdentifier_1E384094 0;
BA_ "GenSigTimeoutTime_CVADAS" SG_ 2654486676 SourceNodeIdentifier_1E384094 0;
BA_ "GenSigTimeoutTime_BSM" SG_ 2654486676 SourceNodeIdentifier_1E384094 0;
BA_ "GenSigTimeoutTime_BSM2" SG_ 2654486676 SourceNodeIdentifier_1E384094 0;
BA_ "GenSigTimeoutTime_CADM" SG_ 2654486676 SourceNodeIdentifier_1E384094 0;
BA_ "GenSigTimeoutTime_CVPAM" SG_ 2654486676 SourceNodeIdentifier_1E384094 0;
BA_ "GenSigTimeoutTime_ECM" SG_ 2654486676 SourceNodeIdentifier_1E384094 0;
BA_ "GenSigTimeoutTime_EPS" SG_ 2654486676 SourceNodeIdentifier_1E384094 0;
BA_ "GenSigTimeoutTime_EVCU2" SG_ 2654486676 SourceNodeIdentifier_1E384094 0;
BA_ "GenSigTimeoutTime_ORC" SG_ 2654486676 SourceNodeIdentifier_1E384094 0;
BA_ "GenSigTimeoutTime_MPAD" SG_ 2654486676 CBV_bit7_1E384094 0;
BA_ "GenSigTimeoutTime_ADCAM" SG_ 2654486676 CBV_bit7_1E384094 0;
BA_ "GenSigTimeoutTime_CVADAS" SG_ 2654486676 CBV_bit7_1E384094 0;
BA_ "GenSigTimeoutTime_BSM" SG_ 2654486676 CBV_bit7_1E384094 0;
BA_ "GenSigTimeoutTime_BSM2" SG_ 2654486676 CBV_bit7_1E384094 0;
BA_ "GenSigTimeoutTime_CADM" SG_ 2654486676 CBV_bit7_1E384094 0;
BA_ "GenSigTimeoutTime_CVPAM" SG_ 2654486676 CBV_bit7_1E384094 0;
BA_ "GenSigTimeoutTime_ECM" SG_ 2654486676 CBV_bit7_1E384094 0;
BA_ "GenSigTimeoutTime_EPS" SG_ 2654486676 CBV_bit7_1E384094 0;
BA_ "GenSigTimeoutTime_EVCU2" SG_ 2654486676 CBV_bit7_1E384094 0;
BA_ "GenSigTimeoutTime_ORC" SG_ 2654486676 CBV_bit7_1E384094 0;
BA_ "GenSigTimeoutTime_MPAD" SG_ 2654486676 CBV_bit6_PartialNtwInfBit_1E384094 0;
BA_ "GenSigTimeoutTime_ADCAM" SG_ 2654486676 CBV_bit6_PartialNtwInfBit_1E384094 0;
BA_ "GenSigTimeoutTime_CVADAS" SG_ 2654486676 CBV_bit6_PartialNtwInfBit_1E384094 0;
BA_ "GenSigTimeoutTime_BSM" SG_ 2654486676 CBV_bit6_PartialNtwInfBit_1E384094 0;
BA_ "GenSigTimeoutTime_BSM2" SG_ 2654486676 CBV_bit6_PartialNtwInfBit_1E384094 0;
BA_ "GenSigTimeoutTime_CADM" SG_ 2654486676 CBV_bit6_PartialNtwInfBit_1E384094 0;
BA_ "GenSigTimeoutTime_CVPAM" SG_ 2654486676 CBV_bit6_PartialNtwInfBit_1E384094 0;
BA_ "GenSigTimeoutTime_ECM" SG_ 2654486676 CBV_bit6_PartialNtwInfBit_1E384094 0;
BA_ "GenSigTimeoutTime_EPS" SG_ 2654486676 CBV_bit6_PartialNtwInfBit_1E384094 0;
BA_ "GenSigTimeoutTime_EVCU2" SG_ 2654486676 CBV_bit6_PartialNtwInfBit_1E384094 0;
BA_ "GenSigTimeoutTime_ORC" SG_ 2654486676 CBV_bit6_PartialNtwInfBit_1E384094 0;
BA_ "GenSigTimeoutTime_MPAD" SG_ 2654486676 CBV_bit5_1E384094 0;
BA_ "GenSigTimeoutTime_ADCAM" SG_ 2654486676 CBV_bit5_1E384094 0;
BA_ "GenSigTimeoutTime_CVADAS" SG_ 2654486676 CBV_bit5_1E384094 0;
BA_ "GenSigTimeoutTime_BSM" SG_ 2654486676 CBV_bit5_1E384094 0;
BA_ "GenSigTimeoutTime_BSM2" SG_ 2654486676 CBV_bit5_1E384094 0;
BA_ "GenSigTimeoutTime_CADM" SG_ 2654486676 CBV_bit5_1E384094 0;
BA_ "GenSigTimeoutTime_CVPAM" SG_ 2654486676 CBV_bit5_1E384094 0;
BA_ "GenSigTimeoutTime_ECM" SG_ 2654486676 CBV_bit5_1E384094 0;
BA_ "GenSigTimeoutTime_EPS" SG_ 2654486676 CBV_bit5_1E384094 0;
BA_ "GenSigTimeoutTime_EVCU2" SG_ 2654486676 CBV_bit5_1E384094 0;
BA_ "GenSigTimeoutTime_ORC" SG_ 2654486676 CBV_bit5_1E384094 0;
BA_ "GenSigTimeoutTime_MPAD" SG_ 2654486676 CBV_bit4_ActiveWakeupBit_1E384094 0;
BA_ "GenSigTimeoutTime_ADCAM" SG_ 2654486676 CBV_bit4_ActiveWakeupBit_1E384094 0;
BA_ "GenSigTimeoutTime_CVADAS" SG_ 2654486676 CBV_bit4_ActiveWakeupBit_1E384094 0;
BA_ "GenSigTimeoutTime_BSM" SG_ 2654486676 CBV_bit4_ActiveWakeupBit_1E384094 0;
BA_ "GenSigTimeoutTime_BSM2" SG_ 2654486676 CBV_bit4_ActiveWakeupBit_1E384094 0;
BA_ "GenSigTimeoutTime_CADM" SG_ 2654486676 CBV_bit4_ActiveWakeupBit_1E384094 0;
BA_ "GenSigTimeoutTime_CVPAM" SG_ 2654486676 CBV_bit4_ActiveWakeupBit_1E384094 0;
BA_ "GenSigTimeoutTime_ECM" SG_ 2654486676 CBV_bit4_ActiveWakeupBit_1E384094 0;
BA_ "GenSigTimeoutTime_EPS" SG_ 2654486676 CBV_bit4_ActiveWakeupBit_1E384094 0;
BA_ "GenSigTimeoutTime_EVCU2" SG_ 2654486676 CBV_bit4_ActiveWakeupBit_1E384094 0;
BA_ "GenSigTimeoutTime_ORC" SG_ 2654486676 CBV_bit4_ActiveWakeupBit_1E384094 0;
BA_ "GenSigTimeoutTime_MPAD" SG_ 2654486676 CBV_bit3_NMCoordinatorBit_1E384094 0;
BA_ "GenSigTimeoutTime_ADCAM" SG_ 2654486676 CBV_bit3_NMCoordinatorBit_1E384094 0;
BA_ "GenSigTimeoutTime_CVADAS" SG_ 2654486676 CBV_bit3_NMCoordinatorBit_1E384094 0;
BA_ "GenSigTimeoutTime_BSM" SG_ 2654486676 CBV_bit3_NMCoordinatorBit_1E384094 0;
BA_ "GenSigTimeoutTime_BSM2" SG_ 2654486676 CBV_bit3_NMCoordinatorBit_1E384094 0;
BA_ "GenSigTimeoutTime_CADM" SG_ 2654486676 CBV_bit3_NMCoordinatorBit_1E384094 0;
BA_ "GenSigTimeoutTime_CVPAM" SG_ 2654486676 CBV_bit3_NMCoordinatorBit_1E384094 0;
BA_ "GenSigTimeoutTime_ECM" SG_ 2654486676 CBV_bit3_NMCoordinatorBit_1E384094 0;
BA_ "GenSigTimeoutTime_EPS" SG_ 2654486676 CBV_bit3_NMCoordinatorBit_1E384094 0;
BA_ "GenSigTimeoutTime_EVCU2" SG_ 2654486676 CBV_bit3_NMCoordinatorBit_1E384094 0;
BA_ "GenSigTimeoutTime_ORC" SG_ 2654486676 CBV_bit3_NMCoordinatorBit_1E384094 0;
BA_ "GenSigTimeoutTime_CADM" SG_ 2654486552 CBV_bit7_1E384018 0;
BA_ "GenSigTimeoutTime_CVPAM" SG_ 2654486552 CBV_bit7_1E384018 0;
BA_ "GenSigTimeoutTime_ECM" SG_ 2654486552 CBV_bit7_1E384018 0;
BA_ "GenSigTimeoutTime_EPS" SG_ 2654486552 CBV_bit7_1E384018 0;
BA_ "GenSigTimeoutTime_EVCU2" SG_ 2654486552 CBV_bit7_1E384018 0;
BA_ "GenSigTimeoutTime_ORC" SG_ 2654486552 CBV_bit7_1E384018 0;
BA_ "GenSigTimeoutTime_BSM" SG_ 2654486552 SourceNodeIdentifier_1E384018 0;
BA_ "GenSigTimeoutTime_BSM2" SG_ 2654486552 SourceNodeIdentifier_1E384018 0;
BA_ "GenSigTimeoutTime_CADM" SG_ 2654486552 SourceNodeIdentifier_1E384018 0;
BA_ "GenSigTimeoutTime_CVPAM" SG_ 2654486552 SourceNodeIdentifier_1E384018 0;
BA_ "GenSigTimeoutTime_ECM" SG_ 2654486552 SourceNodeIdentifier_1E384018 0;
BA_ "GenSigTimeoutTime_EPS" SG_ 2654486552 SourceNodeIdentifier_1E384018 0;
BA_ "GenSigTimeoutTime_EVCU2" SG_ 2654486552 SourceNodeIdentifier_1E384018 0;
BA_ "GenSigTimeoutTime_ORC" SG_ 2654486552 SourceNodeIdentifier_1E384018 0;
BA_ "GenSigTimeoutTime_BSM2" SG_ 524 MessageCounter_BRAKE2_2 0;
BA_ "GenSigTimeoutTime_CVPAM" SG_ 524 MessageCounter_BRAKE2_2 0;
BA_ "GenSigTimeoutTime_ECM" SG_ 524 MessageCounter_BRAKE2_2 0;
BA_ "GenSigTimeoutTime_EPS" SG_ 524 MessageCounter_BRAKE2_2 0;
BA_ "GenSigTimeoutTime_EVCU2" SG_ 524 MessageCounter_BRAKE2_2 0;
BA_ "GenSigTimeoutTime_ADCAM" SG_ 524 MessageCounter_BRAKE2_2 0;
BA_ "GenSigTimeoutTime_CVADAS" SG_ 524 MessageCounter_BRAKE2_2 0;
BA_ "GenSigStartValue" SG_ 524 BrkTrq_B2 32767;
BA_ "GenSigTimeoutTime_BSM" SG_ 524 BrkTrq_B2 0;
BA_ "GenSigTimeoutTime_BSM2" SG_ 524 BrkTrq_B2 0;
BA_ "GenSigTimeoutTime_CVPAM" SG_ 524 BrkTrq_B2 0;
BA_ "GenSigTimeoutTime_ECM" SG_ 524 BrkTrq_B2 0;
BA_ "GenSigTimeoutTime_EPS" SG_ 524 BrkTrq_B2 0;
BA_ "GenSigTimeoutTime_EVCU2" SG_ 524 BrkTrq_B2 0;
BA_ "GenSigTimeoutTime_ORC" SG_ 524 BrkTrq_B2 0;
BA_ "GenSigTimeoutTime_ADCAM" SG_ 524 BrkTrq_B2 0;
BA_ "GenSigTimeoutTime_CVADAS" SG_ 524 BrkTrq_B2 0;
BA_ "GenSigTimeoutTime_BSM2" SG_ 524 CRC_BRAKE2_2 0;
BA_ "GenSigTimeoutTime_CVPAM" SG_ 524 CRC_BRAKE2_2 0;
BA_ "GenSigTimeoutTime_ECM" SG_ 524 CRC_BRAKE2_2 0;
BA_ "GenSigTimeoutTime_EPS" SG_ 524 CRC_BRAKE2_2 0;
BA_ "GenSigTimeoutTime_EVCU2" SG_ 524 CRC_BRAKE2_2 0;
BA_ "GenSigTimeoutTime_ADCAM" SG_ 524 CRC_BRAKE2_2 0;
BA_ "GenSigTimeoutTime_CVADAS" SG_ 524 CRC_BRAKE2_2 0;
BA_ "GenSigTimeoutTime_ADCAM" SG_ 257 LHF_WheelSensorFailSts_B2 0;
BA_ "GenSigTimeoutTime_CVADAS" SG_ 257 LHF_WheelSensorFailSts_B2 0;
BA_ "GenSigTimeoutTime_BSM" SG_ 257 LHF_WheelSensorFailSts_B2 0;
BA_ "GenSigTimeoutTime_BSM2" SG_ 257 LHF_WheelSensorFailSts_B2 0;
BA_ "GenSigTimeoutTime_CVPAM" SG_ 257 LHF_WheelSensorFailSts_B2 0;
BA_ "GenSigTimeoutTime_ECM" SG_ 257 LHF_WheelSensorFailSts_B2 0;
BA_ "GenSigTimeoutTime_EPS" SG_ 257 LHF_WheelSensorFailSts_B2 0;
BA_ "GenSigTimeoutTime_EVCU2" SG_ 257 LHF_WheelSensorFailSts_B2 0;
BA_ "GenSigTimeoutTime_ORC" SG_ 257 LHF_WheelSensorFailSts_B2 0;
BA_ "GenSigTimeoutTime_MPAD" SG_ 257 MessageCounter_BRAKE2_1 0;
BA_ "GenSigTimeoutTime_ADCAM" SG_ 257 MessageCounter_BRAKE2_1 0;
BA_ "GenSigTimeoutTime_CVADAS" SG_ 257 MessageCounter_BRAKE2_1 0;
BA_ "GenSigTimeoutTime_BSM" SG_ 257 MessageCounter_BRAKE2_1 0;
BA_ "GenSigTimeoutTime_BSM2" SG_ 257 MessageCounter_BRAKE2_1 0;
BA_ "GenSigTimeoutTime_CVPAM" SG_ 257 MessageCounter_BRAKE2_1 0;
BA_ "GenSigTimeoutTime_ECM" SG_ 257 MessageCounter_BRAKE2_1 0;
BA_ "GenSigTimeoutTime_EVCU2" SG_ 257 MessageCounter_BRAKE2_1 0;
BA_ "GenSigTimeoutTime_ADCAM" SG_ 257 RHF_Spin_B2 0;
BA_ "GenSigTimeoutTime_CVADAS" SG_ 257 RHF_Spin_B2 0;
BA_ "GenSigTimeoutTime_BSM" SG_ 257 RHF_Spin_B2 0;
BA_ "GenSigTimeoutTime_BSM2" SG_ 257 RHF_Spin_B2 0;
BA_ "GenSigTimeoutTime_CVPAM" SG_ 257 RHF_Spin_B2 0;
BA_ "GenSigTimeoutTime_ECM" SG_ 257 RHF_Spin_B2 0;
BA_ "GenSigTimeoutTime_EPS" SG_ 257 RHF_Spin_B2 0;
BA_ "GenSigTimeoutTime_EVCU2" SG_ 257 RHF_Spin_B2 0;
BA_ "GenSigTimeoutTime_ORC" SG_ 257 RHF_Spin_B2 0;
BA_ "GenSigTimeoutTime_ADCAM" SG_ 257 RHF_WheelSensorFailSts_B2 0;
BA_ "GenSigTimeoutTime_CVADAS" SG_ 257 RHF_WheelSensorFailSts_B2 0;
BA_ "GenSigTimeoutTime_BSM" SG_ 257 RHF_WheelSensorFailSts_B2 0;
BA_ "GenSigTimeoutTime_BSM2" SG_ 257 RHF_WheelSensorFailSts_B2 0;
BA_ "GenSigTimeoutTime_CVPAM" SG_ 257 RHF_WheelSensorFailSts_B2 0;
BA_ "GenSigTimeoutTime_ECM" SG_ 257 RHF_WheelSensorFailSts_B2 0;
BA_ "GenSigTimeoutTime_EPS" SG_ 257 RHF_WheelSensorFailSts_B2 0;
BA_ "GenSigTimeoutTime_EVCU2" SG_ 257 RHF_WheelSensorFailSts_B2 0;
BA_ "GenSigTimeoutTime_ORC" SG_ 257 RHF_WheelSensorFailSts_B2 0;
BA_ "GenSigTimeoutTime_ADCAM" SG_ 257 ABSActive_B2 0;
BA_ "GenSigTimeoutTime_CVADAS" SG_ 257 ABSActive_B2 0;
BA_ "GenSigTimeoutTime_BSM" SG_ 257 ABSActive_B2 0;
BA_ "GenSigTimeoutTime_BSM2" SG_ 257 ABSActive_B2 0;
BA_ "GenSigTimeoutTime_CVPAM" SG_ 257 ABSActive_B2 0;
BA_ "GenSigTimeoutTime_ECM" SG_ 257 ABSActive_B2 0;
BA_ "GenSigTimeoutTime_EPS" SG_ 257 ABSActive_B2 0;
BA_ "GenSigTimeoutTime_EVCU2" SG_ 257 ABSActive_B2 0;
BA_ "GenSigTimeoutTime_ORC" SG_ 257 ABSActive_B2 0;
BA_ "GenSigTimeoutTime_ADCAM" SG_ 257 Brk_Stat_B2 0;
BA_ "GenSigTimeoutTime_CVADAS" SG_ 257 Brk_Stat_B2 0;
BA_ "GenSigTimeoutTime_BSM" SG_ 257 Brk_Stat_B2 0;
BA_ "GenSigTimeoutTime_BSM2" SG_ 257 Brk_Stat_B2 0;
BA_ "GenSigTimeoutTime_CVPAM" SG_ 257 Brk_Stat_B2 0;
BA_ "GenSigTimeoutTime_ECM" SG_ 257 Brk_Stat_B2 0;
BA_ "GenSigTimeoutTime_EPS" SG_ 257 Brk_Stat_B2 0;
BA_ "GenSigTimeoutTime_EVCU2" SG_ 257 Brk_Stat_B2 0;
BA_ "GenSigTimeoutTime_ORC" SG_ 257 Brk_Stat_B2 0;
BA_ "GenSigTimeoutTime_MPAD" SG_ 257 CRC_BRAKE2_1 0;
BA_ "GenSigTimeoutTime_ADCAM" SG_ 257 CRC_BRAKE2_1 0;
BA_ "GenSigTimeoutTime_CVADAS" SG_ 257 CRC_BRAKE2_1 0;
BA_ "GenSigTimeoutTime_BSM" SG_ 257 CRC_BRAKE2_1 0;
BA_ "GenSigTimeoutTime_BSM2" SG_ 257 CRC_BRAKE2_1 0;
BA_ "GenSigTimeoutTime_CVPAM" SG_ 257 CRC_BRAKE2_1 0;
BA_ "GenSigTimeoutTime_ECM" SG_ 257 CRC_BRAKE2_1 0;
BA_ "GenSigTimeoutTime_EVCU2" SG_ 257 CRC_BRAKE2_1 0;
BA_ "GenSigTimeoutTime_ADCAM" SG_ 257 Inlet_Pressure_Pos 0;
BA_ "GenSigTimeoutTime_CVADAS" SG_ 257 Inlet_Pressure_Pos 0;
BA_ "GenSigTimeoutTime_BSM" SG_ 257 Inlet_Pressure_Pos 0;
BA_ "GenSigTimeoutTime_BSM2" SG_ 257 Inlet_Pressure_Pos 0;
BA_ "GenSigTimeoutTime_CVPAM" SG_ 257 Inlet_Pressure_Pos 0;
BA_ "GenSigTimeoutTime_ECM" SG_ 257 Inlet_Pressure_Pos 0;
BA_ "GenSigTimeoutTime_EPS" SG_ 257 Inlet_Pressure_Pos 0;
BA_ "GenSigTimeoutTime_EVCU2" SG_ 257 Inlet_Pressure_Pos 0;
BA_ "GenSigTimeoutTime_ORC" SG_ 257 Inlet_Pressure_Pos 0;
BA_ "GenSigTimeoutTime_ADCAM" SG_ 257 LHF_Spin_B2 0;
BA_ "GenSigTimeoutTime_CVADAS" SG_ 257 LHF_Spin_B2 0;
BA_ "GenSigTimeoutTime_BSM" SG_ 257 LHF_Spin_B2 0;
BA_ "GenSigTimeoutTime_BSM2" SG_ 257 LHF_Spin_B2 0;
BA_ "GenSigTimeoutTime_CVPAM" SG_ 257 LHF_Spin_B2 0;
BA_ "GenSigTimeoutTime_ECM" SG_ 257 LHF_Spin_B2 0;
BA_ "GenSigTimeoutTime_EPS" SG_ 257 LHF_Spin_B2 0;
BA_ "GenSigTimeoutTime_EVCU2" SG_ 257 LHF_Spin_B2 0;
BA_ "GenSigTimeoutTime_ORC" SG_ 257 LHF_Spin_B2 0;
BA_ "GenSigTimeoutTime_ECM" SG_ 524 AEB_Type_Brk_B2 0;
BA_ "GenSigTimeoutTime_EPS" SG_ 524 AEB_Type_Brk_B2 0;
BA_ "GenSigTimeoutTime_EVCU2" SG_ 524 AEB_Type_Brk_B2 0;
BA_ "GenSigTimeoutTime_ORC" SG_ 524 AEB_Type_Brk_B2 0;
BA_ "GenSigTimeoutTime_ADCAM" SG_ 524 AEB_Type_Brk_B2 0;
BA_ "GenSigTimeoutTime_CVADAS" SG_ 524 AEB_Type_Brk_B2 0;
BA_ "GenSigTimeoutTime_BSM" SG_ 524 AEB_Type_Brk_B2 0;
BA_ "GenSigTimeoutTime_BSM2" SG_ 524 AEB_Type_Brk_B2 0;
BA_ "GenSigTimeoutTime_CVPAM" SG_ 524 AEB_Type_Brk_B2 0;
BA_ "GenSigTimeoutTime_BSM2" SG_ 524 BSM2_HEALTH_CHECK 0;
BA_ "GenSigTimeoutTime_CADM" SG_ 524 BSM2_HEALTH_CHECK 0;
BA_ "GenSigTimeoutTime_CVPAM" SG_ 524 BSM2_HEALTH_CHECK 0;
BA_ "GenSigTimeoutTime_ECM" SG_ 524 BSM2_HEALTH_CHECK 0;
BA_ "GenSigTimeoutTime_EPS" SG_ 524 BSM2_HEALTH_CHECK 0;
BA_ "GenSigTimeoutTime_EVCU2" SG_ 524 BSM2_HEALTH_CHECK 0;
BA_ "GenSigTimeoutTime_ORC" SG_ 524 BSM2_HEALTH_CHECK 0;
BA_ "GenSigTimeoutTime_MPAD" SG_ 524 BSM2_HEALTH_CHECK 0;
BA_ "GenSigTimeoutTime_ADCAM" SG_ 524 BSM2_HEALTH_CHECK 0;
BA_ "GenSigTimeoutTime_CVADAS" SG_ 524 BSM2_HEALTH_CHECK 0;
BA_ "GenSigTimeoutTime_CVADAS" SG_ 257 Rear_Diff_BSM_RQ_B2 0;
BA_ "GenSigTimeoutTime_BSM" SG_ 257 Rear_Diff_BSM_RQ_B2 0;
BA_ "GenSigTimeoutTime_BSM2" SG_ 257 Rear_Diff_BSM_RQ_B2 0;
BA_ "GenSigTimeoutTime_CADM" SG_ 257 Rear_Diff_BSM_RQ_B2 0;
BA_ "GenSigTimeoutTime_CVPAM" SG_ 257 Rear_Diff_BSM_RQ_B2 0;
BA_ "GenSigTimeoutTime_ECM" SG_ 257 Rear_Diff_BSM_RQ_B2 0;
BA_ "GenSigTimeoutTime_EPS" SG_ 257 Rear_Diff_BSM_RQ_B2 0;
BA_ "GenSigTimeoutTime_EVCU2" SG_ 257 Rear_Diff_BSM_RQ_B2 0;
BA_ "GenSigTimeoutTime_ORC" SG_ 257 Rear_Diff_BSM_RQ_B2 0;
BA_ "GenSigTimeoutTime_MPAD" SG_ 257 Ft_RrTrqCoupling_ModeRq_B2 0;
BA_ "GenSigTimeoutTime_ADCAM" SG_ 257 Ft_RrTrqCoupling_ModeRq_B2 0;
BA_ "GenSigTimeoutTime_CVADAS" SG_ 257 Ft_RrTrqCoupling_ModeRq_B2 0;
BA_ "GenSigTimeoutTime_BSM" SG_ 257 Ft_RrTrqCoupling_ModeRq_B2 0;
BA_ "GenSigTimeoutTime_BSM2" SG_ 257 Ft_RrTrqCoupling_ModeRq_B2 0;
BA_ "GenSigTimeoutTime_CADM" SG_ 257 Ft_RrTrqCoupling_ModeRq_B2 0;
BA_ "GenSigTimeoutTime_CVPAM" SG_ 257 Ft_RrTrqCoupling_ModeRq_B2 0;
BA_ "GenSigTimeoutTime_ECM" SG_ 257 Ft_RrTrqCoupling_ModeRq_B2 0;
BA_ "GenSigTimeoutTime_EPS" SG_ 257 Ft_RrTrqCoupling_ModeRq_B2 0;
BA_ "GenSigTimeoutTime_EVCU2" SG_ 257 Ft_RrTrqCoupling_ModeRq_B2 0;
BA_ "GenSigTimeoutTime_ORC" SG_ 257 Ft_RrTrqCoupling_ModeRq_B2 0;
BA_ "GenSigTimeoutTime_CVADAS" SG_ 257 R_DIFF_TRQ_RQ_B2 0;
BA_ "GenSigStartValue" SG_ 257 R_DIFF_TRQ_RQ_B2 511;
BA_ "GenSigTimeoutTime_BSM" SG_ 257 R_DIFF_TRQ_RQ_B2 0;
BA_ "GenSigTimeoutTime_BSM2" SG_ 257 R_DIFF_TRQ_RQ_B2 0;
BA_ "GenSigTimeoutTime_CADM" SG_ 257 R_DIFF_TRQ_RQ_B2 0;
BA_ "GenSigTimeoutTime_CVPAM" SG_ 257 R_DIFF_TRQ_RQ_B2 0;
BA_ "GenSigTimeoutTime_ECM" SG_ 257 R_DIFF_TRQ_RQ_B2 0;
BA_ "GenSigTimeoutTime_EPS" SG_ 257 R_DIFF_TRQ_RQ_B2 0;
BA_ "GenSigTimeoutTime_EVCU2" SG_ 257 R_DIFF_TRQ_RQ_B2 0;
BA_ "GenSigTimeoutTime_ORC" SG_ 257 R_DIFF_TRQ_RQ_B2 0;
BA_ "GenSigTimeoutTime_MPAD" SG_ 257 Ft_RrAxleCoupling_TrqRq_B2 0;
BA_ "GenSigTimeoutTime_ADCAM" SG_ 257 Ft_RrAxleCoupling_TrqRq_B2 0;
BA_ "GenSigTimeoutTime_CVADAS" SG_ 257 Ft_RrAxleCoupling_TrqRq_B2 0;
BA_ "GenSigStartValue" SG_ 257 Ft_RrAxleCoupling_TrqRq_B2 254;
BA_ "GenSigTimeoutTime_BSM" SG_ 257 Ft_RrAxleCoupling_TrqRq_B2 0;
BA_ "GenSigTimeoutTime_BSM2" SG_ 257 Ft_RrAxleCoupling_TrqRq_B2 0;
BA_ "GenSigTimeoutTime_CADM" SG_ 257 Ft_RrAxleCoupling_TrqRq_B2 0;
BA_ "GenSigTimeoutTime_CVPAM" SG_ 257 Ft_RrAxleCoupling_TrqRq_B2 0;
BA_ "GenSigTimeoutTime_ECM" SG_ 257 Ft_RrAxleCoupling_TrqRq_B2 0;
BA_ "GenSigTimeoutTime_EPS" SG_ 257 Ft_RrAxleCoupling_TrqRq_B2 0;
BA_ "GenSigTimeoutTime_EVCU2" SG_ 257 Ft_RrAxleCoupling_TrqRq_B2 0;
BA_ "GenSigTimeoutTime_ORC" SG_ 257 Ft_RrAxleCoupling_TrqRq_B2 0;
BA_ "GenSigTimeoutTime_ADCAM" SG_ 524 VehicleStandStillSts_B2 0;
BA_ "GenSigTimeoutTime_CVADAS" SG_ 524 VehicleStandStillSts_B2 0;
BA_ "GenSigTimeoutTime_ADCAM" SG_ 524 BSM2_OpStat 0;
BA_ "GenSigTimeoutTime_CVADAS" SG_ 524 BSM2_OpStat 0;
BA_ "GenSigTimeoutTime_ADCAM" SG_ 257 VehicleSpeedVSOSig_B2 0;
BA_ "GenSigTimeoutTime_CVADAS" SG_ 257 VehicleSpeedVSOSig_B2 0;
BA_ "GenSigTimeoutTime_BSM" SG_ 257 VehicleSpeedVSOSig_B2 0;
BA_ "GenSigTimeoutTime_BSM2" SG_ 257 VehicleSpeedVSOSig_B2 0;
BA_ "GenSigTimeoutTime_ECM" SG_ 257 VehicleSpeedVSOSig_B2 0;
BA_ "GenSigTimeoutTime_EVCU2" SG_ 257 VehicleSpeedVSOSig_B2 0;
BA_ "GenSigTimeoutTime_ORC" SG_ 257 VehicleSpeedVSOSig_B2 0;
BA_ "GenSigTimeoutTime_ADCAM" SG_ 524 Brake_OpStat_Sec 0;
BA_ "GenSigTimeoutTime_CVADAS" SG_ 524 Brake_OpStat_Sec 0;
BA_ "GenSigTimeoutTime_ADCAM" SG_ 257 LHF_FastPulseCounter_B2 0;
BA_ "GenSigTimeoutTime_CVADAS" SG_ 257 LHF_FastPulseCounter_B2 0;
BA_ "GenSigTimeoutTime_BSM" SG_ 257 LHF_FastPulseCounter_B2 0;
BA_ "GenSigTimeoutTime_BSM2" SG_ 257 LHF_FastPulseCounter_B2 0;
BA_ "GenSigTimeoutTime_CVPAM" SG_ 257 LHF_FastPulseCounter_B2 0;
BA_ "GenSigTimeoutTime_ECM" SG_ 257 LHF_FastPulseCounter_B2 0;
BA_ "GenSigTimeoutTime_EPS" SG_ 257 LHF_FastPulseCounter_B2 0;
BA_ "GenSigTimeoutTime_EVCU2" SG_ 257 LHF_FastPulseCounter_B2 0;
BA_ "GenSigTimeoutTime_ORC" SG_ 257 LHF_FastPulseCounter_B2 0;
BA_ "GenSigTimeoutTime_ADCAM" SG_ 257 LHFWheelSpeed_B2 0;
BA_ "GenSigTimeoutTime_CVADAS" SG_ 257 LHFWheelSpeed_B2 0;
BA_ "GenSigTimeoutTime_BSM" SG_ 257 LHFWheelSpeed_B2 0;
BA_ "GenSigTimeoutTime_BSM2" SG_ 257 LHFWheelSpeed_B2 0;
BA_ "GenSigTimeoutTime_CVPAM" SG_ 257 LHFWheelSpeed_B2 0;
BA_ "GenSigTimeoutTime_ECM" SG_ 257 LHFWheelSpeed_B2 0;
BA_ "GenSigTimeoutTime_EPS" SG_ 257 LHFWheelSpeed_B2 0;
BA_ "GenSigTimeoutTime_EVCU2" SG_ 257 LHFWheelSpeed_B2 0;
BA_ "GenSigTimeoutTime_ORC" SG_ 257 LHFWheelSpeed_B2 0;
BA_ "GenSigTimeoutTime_ADCAM" SG_ 257 RHF_FastPulseCounter_B2 0;
BA_ "GenSigTimeoutTime_CVADAS" SG_ 257 RHF_FastPulseCounter_B2 0;
BA_ "GenSigTimeoutTime_BSM" SG_ 257 RHF_FastPulseCounter_B2 0;
BA_ "GenSigTimeoutTime_BSM2" SG_ 257 RHF_FastPulseCounter_B2 0;
BA_ "GenSigTimeoutTime_CVPAM" SG_ 257 RHF_FastPulseCounter_B2 0;
BA_ "GenSigTimeoutTime_ECM" SG_ 257 RHF_FastPulseCounter_B2 0;
BA_ "GenSigTimeoutTime_EPS" SG_ 257 RHF_FastPulseCounter_B2 0;
BA_ "GenSigTimeoutTime_EVCU2" SG_ 257 RHF_FastPulseCounter_B2 0;
BA_ "GenSigTimeoutTime_ORC" SG_ 257 RHF_FastPulseCounter_B2 0;
BA_ "GenSigTimeoutTime_ADCAM" SG_ 257 RHFWheelSpeed_B2 0;
BA_ "GenSigTimeoutTime_CVADAS" SG_ 257 RHFWheelSpeed_B2 0;
BA_ "GenSigTimeoutTime_BSM" SG_ 257 RHFWheelSpeed_B2 0;
BA_ "GenSigTimeoutTime_BSM2" SG_ 257 RHFWheelSpeed_B2 0;
BA_ "GenSigTimeoutTime_CVPAM" SG_ 257 RHFWheelSpeed_B2 0;
BA_ "GenSigTimeoutTime_ECM" SG_ 257 RHFWheelSpeed_B2 0;
BA_ "GenSigTimeoutTime_EPS" SG_ 257 RHFWheelSpeed_B2 0;
BA_ "GenSigTimeoutTime_EVCU2" SG_ 257 RHFWheelSpeed_B2 0;
BA_ "GenSigTimeoutTime_ORC" SG_ 257 RHFWheelSpeed_B2 0;
BA_ "GenSigTimeoutTime_MPAD" SG_ 258 WheelRPM_FR 0;
BA_ "GenSigTimeoutTime_ADCAM" SG_ 258 WheelRPM_FR 0;
BA_ "GenSigTimeoutTime_CVADAS" SG_ 258 WheelRPM_FR 0;
BA_ "GenSigTimeoutTime_VDCM" SG_ 258 WheelRPM_FR 0;
BA_ "GenSigTimeoutTime_MPAD" SG_ 258 WheelRPM_FL 0;
BA_ "GenSigTimeoutTime_ADCAM" SG_ 258 WheelRPM_FL 0;
BA_ "GenSigTimeoutTime_CVADAS" SG_ 258 WheelRPM_FL 0;
BA_ "GenSigTimeoutTime_VDCM" SG_ 258 WheelRPM_FL 0;
BA_ "GenSigTimeoutTime_CVADAS" SG_ 258 Brk_Stat 0;
BA_ "GenSigTimeoutTime_VDCM" SG_ 258 Brk_Stat 0;
BA_ "GenSigTimeoutTime_BSM" SG_ 524 Brake_OpStat_Sec 0;
BA_ "GenSigTimeoutTime_BSM2" SG_ 524 Brake_OpStat_Sec 0;
BA_ "GenSigTimeoutTime_CVPAM" SG_ 524 Brake_OpStat_Sec 0;
BA_ "GenSigTimeoutTime_ECM" SG_ 524 Brake_OpStat_Sec 0;
BA_ "GenSigTimeoutTime_EPS" SG_ 524 Brake_OpStat_Sec 0;
BA_ "GenSigTimeoutTime_EVCU2" SG_ 524 Brake_OpStat_Sec 0;
BA_ "GenSigTimeoutTime_ORC" SG_ 524 Brake_OpStat_Sec 0;
BA_ "GenSigTimeoutTime_BSM2" SG_ 524 BSM2_OpStat 0;
BA_ "GenSigTimeoutTime_CVPAM" SG_ 524 BSM2_OpStat 0;
BA_ "GenSigTimeoutTime_ECM" SG_ 524 BSM2_OpStat 0;
BA_ "GenSigTimeoutTime_EPS" SG_ 524 BSM2_OpStat 0;
BA_ "GenSigTimeoutTime_EVCU2" SG_ 524 BSM2_OpStat 0;
BA_ "GenSigTimeoutTime_ORC" SG_ 524 BSM2_OpStat 0;
BA_ "GenSigStartValue" SG_ 524 VehicleStandStillSts_B2 1;
BA_ "GenSigTimeoutTime_BSM2" SG_ 524 VehicleStandStillSts_B2 0;
BA_ "GenSigTimeoutTime_CVPAM" SG_ 524 VehicleStandStillSts_B2 0;
BA_ "GenSigTimeoutTime_ECM" SG_ 524 VehicleStandStillSts_B2 0;
BA_ "GenSigTimeoutTime_EPS" SG_ 524 VehicleStandStillSts_B2 0;
BA_ "GenSigTimeoutTime_EVCU2" SG_ 524 VehicleStandStillSts_B2 0;
BA_ "GenSigTimeoutTime_ORC" SG_ 524 VehicleStandStillSts_B2 0;
BA_ "GenSigTimeoutTime_BSM" SG_ 258 YawRateFailSts_BSM 0;
BA_ "GenSigTimeoutTime_BSM" SG_ 2654486534 CBV_bit6_PartialNtwInfBit_1E384006 0;
BA_ "GenSigTimeoutTime_BSM2" SG_ 2654486534 CBV_bit6_PartialNtwInfBit_1E384006 0;
BA_ "GenSigTimeoutTime_CADM" SG_ 2654486534 CBV_bit6_PartialNtwInfBit_1E384006 0;
BA_ "GenSigTimeoutTime_CVPAM" SG_ 2654486534 CBV_bit6_PartialNtwInfBit_1E384006 0;
BA_ "GenSigTimeoutTime_ECM" SG_ 2654486534 CBV_bit6_PartialNtwInfBit_1E384006 0;
BA_ "GenSigTimeoutTime_EPS" SG_ 2654486534 CBV_bit6_PartialNtwInfBit_1E384006 0;
BA_ "GenSigTimeoutTime_EVCU2" SG_ 2654486534 CBV_bit6_PartialNtwInfBit_1E384006 0;
BA_ "GenSigTimeoutTime_ORC" SG_ 2654486534 CBV_bit6_PartialNtwInfBit_1E384006 0;
BA_ "GenSigTimeoutTime_BSM" SG_ 2654486534 CBV_bit7_1E384006 0;
BA_ "GenSigTimeoutTime_BSM2" SG_ 2654486534 CBV_bit7_1E384006 0;
BA_ "GenSigTimeoutTime_CADM" SG_ 2654486534 CBV_bit7_1E384006 0;
BA_ "GenSigTimeoutTime_CVPAM" SG_ 2654486534 CBV_bit7_1E384006 0;
BA_ "GenSigTimeoutTime_ECM" SG_ 2654486534 CBV_bit7_1E384006 0;
BA_ "GenSigTimeoutTime_EPS" SG_ 2654486534 CBV_bit7_1E384006 0;
BA_ "GenSigTimeoutTime_EVCU2" SG_ 2654486534 CBV_bit7_1E384006 0;
BA_ "GenSigTimeoutTime_ORC" SG_ 2654486534 CBV_bit7_1E384006 0;
BA_ "GenSigTimeoutTime_BSM" SG_ 2654486534 SourceNodeIdentifier_1E384006 0;
BA_ "GenSigTimeoutTime_BSM2" SG_ 2654486534 SourceNodeIdentifier_1E384006 0;
BA_ "GenSigTimeoutTime_CADM" SG_ 2654486534 SourceNodeIdentifier_1E384006 0;
BA_ "GenSigTimeoutTime_CVPAM" SG_ 2654486534 SourceNodeIdentifier_1E384006 0;
BA_ "GenSigTimeoutTime_ECM" SG_ 2654486534 SourceNodeIdentifier_1E384006 0;
BA_ "GenSigTimeoutTime_EPS" SG_ 2654486534 SourceNodeIdentifier_1E384006 0;
BA_ "GenSigTimeoutTime_EVCU2" SG_ 2654486534 SourceNodeIdentifier_1E384006 0;
BA_ "GenSigTimeoutTime_ORC" SG_ 2654486534 SourceNodeIdentifier_1E384006 0;
BA_ "GenSigTimeoutTime_ADCAM" SG_ 2654486529 CBV_bit0_RepeatMessageRequestBit_1E384001 0;
BA_ "GenSigTimeoutTime_CVADAS" SG_ 2654486529 CBV_bit0_RepeatMessageRequestBit_1E384001 0;
BA_ "GenSigTimeoutTime_VDCM" SG_ 2654486529 CBV_bit0_RepeatMessageRequestBit_1E384001 0;
BA_ "GenSigTimeoutTime_BSM" SG_ 2654486529 CBV_bit0_RepeatMessageRequestBit_1E384001 0;
BA_ "GenSigTimeoutTime_BSM2" SG_ 2654486529 CBV_bit0_RepeatMessageRequestBit_1E384001 0;
BA_ "GenSigTimeoutTime_CADM" SG_ 2654486529 CBV_bit0_RepeatMessageRequestBit_1E384001 0;
BA_ "GenSigTimeoutTime_CVPAM" SG_ 2654486529 CBV_bit0_RepeatMessageRequestBit_1E384001 0;
BA_ "GenSigTimeoutTime_ECM" SG_ 2654486529 CBV_bit0_RepeatMessageRequestBit_1E384001 0;
BA_ "GenSigTimeoutTime_EPS" SG_ 2654486529 CBV_bit0_RepeatMessageRequestBit_1E384001 0;
BA_ "GenSigTimeoutTime_EVCU2" SG_ 2654486529 CBV_bit0_RepeatMessageRequestBit_1E384001 0;
BA_ "GenSigTimeoutTime_ORC" SG_ 2654486529 CBV_bit0_RepeatMessageRequestBit_1E384001 0;
BA_ "GenSigTimeoutTime_ADCAM" SG_ 2654486529 CBV_bit1_1E384001 0;
BA_ "GenSigTimeoutTime_CVADAS" SG_ 2654486529 CBV_bit1_1E384001 0;
BA_ "GenSigTimeoutTime_VDCM" SG_ 2654486529 CBV_bit1_1E384001 0;
BA_ "GenSigTimeoutTime_BSM" SG_ 2654486529 CBV_bit1_1E384001 0;
BA_ "GenSigTimeoutTime_BSM2" SG_ 2654486529 CBV_bit1_1E384001 0;
BA_ "GenSigTimeoutTime_CADM" SG_ 2654486529 CBV_bit1_1E384001 0;
BA_ "GenSigTimeoutTime_CVPAM" SG_ 2654486529 CBV_bit1_1E384001 0;
BA_ "GenSigTimeoutTime_ECM" SG_ 2654486529 CBV_bit1_1E384001 0;
BA_ "GenSigTimeoutTime_EPS" SG_ 2654486529 CBV_bit1_1E384001 0;
BA_ "GenSigTimeoutTime_EVCU2" SG_ 2654486529 CBV_bit1_1E384001 0;
BA_ "GenSigTimeoutTime_ORC" SG_ 2654486529 CBV_bit1_1E384001 0;
BA_ "GenSigTimeoutTime_BSM" SG_ 2654486529 CBV_bit3_NMCoordinatorBit_1E384001 0;
BA_ "GenSigTimeoutTime_BSM2" SG_ 2654486529 CBV_bit3_NMCoordinatorBit_1E384001 0;
BA_ "GenSigTimeoutTime_CADM" SG_ 2654486529 CBV_bit3_NMCoordinatorBit_1E384001 0;
BA_ "GenSigTimeoutTime_CVPAM" SG_ 2654486529 CBV_bit3_NMCoordinatorBit_1E384001 0;
BA_ "GenSigTimeoutTime_ECM" SG_ 2654486529 CBV_bit3_NMCoordinatorBit_1E384001 0;
BA_ "GenSigTimeoutTime_EPS" SG_ 2654486529 CBV_bit3_NMCoordinatorBit_1E384001 0;
BA_ "GenSigTimeoutTime_EVCU2" SG_ 2654486529 CBV_bit3_NMCoordinatorBit_1E384001 0;
BA_ "GenSigTimeoutTime_ORC" SG_ 2654486529 CBV_bit3_NMCoordinatorBit_1E384001 0;
BA_ "GenSigTimeoutTime_ADCAM" SG_ 2654486529 CBV_bit3_NMCoordinatorBit_1E384001 0;
BA_ "GenSigTimeoutTime_CVADAS" SG_ 2654486529 CBV_bit3_NMCoordinatorBit_1E384001 0;
BA_ "GenSigTimeoutTime_VDCM" SG_ 2654486529 CBV_bit3_NMCoordinatorBit_1E384001 0;
BA_ "GenSigTimeoutTime_BSM" SG_ 2654486529 CBV_bit2_1E384001 0;
BA_ "GenSigTimeoutTime_BSM2" SG_ 2654486529 CBV_bit2_1E384001 0;
BA_ "GenSigTimeoutTime_CADM" SG_ 2654486529 CBV_bit2_1E384001 0;
BA_ "GenSigTimeoutTime_CVPAM" SG_ 2654486529 CBV_bit2_1E384001 0;
BA_ "GenSigTimeoutTime_ECM" SG_ 2654486529 CBV_bit2_1E384001 0;
BA_ "GenSigTimeoutTime_EPS" SG_ 2654486529 CBV_bit2_1E384001 0;
BA_ "GenSigTimeoutTime_EVCU2" SG_ 2654486529 CBV_bit2_1E384001 0;
BA_ "GenSigTimeoutTime_ORC" SG_ 2654486529 CBV_bit2_1E384001 0;
BA_ "GenSigTimeoutTime_ADCAM" SG_ 2654486529 CBV_bit2_1E384001 0;
BA_ "GenSigTimeoutTime_CVADAS" SG_ 2654486529 CBV_bit2_1E384001 0;
BA_ "GenSigTimeoutTime_VDCM" SG_ 2654486529 CBV_bit2_1E384001 0;
BA_ "GenSigTimeoutTime_ORC" SG_ 2654486529 CBV_bit5_1E384001 0;
BA_ "GenSigTimeoutTime_BSM" SG_ 2654486529 CBV_bit6_PartialNtwInfBit_1E384001 0;
BA_ "GenSigTimeoutTime_BSM2" SG_ 2654486529 CBV_bit6_PartialNtwInfBit_1E384001 0;
BA_ "GenSigTimeoutTime_CADM" SG_ 2654486529 CBV_bit6_PartialNtwInfBit_1E384001 0;
BA_ "GenSigTimeoutTime_CVPAM" SG_ 2654486529 CBV_bit6_PartialNtwInfBit_1E384001 0;
BA_ "GenSigTimeoutTime_ECM" SG_ 2654486529 CBV_bit6_PartialNtwInfBit_1E384001 0;
BA_ "GenSigTimeoutTime_EPS" SG_ 2654486529 CBV_bit6_PartialNtwInfBit_1E384001 0;
BA_ "GenSigTimeoutTime_EVCU2" SG_ 2654486529 CBV_bit6_PartialNtwInfBit_1E384001 0;
BA_ "GenSigTimeoutTime_ORC" SG_ 2654486529 CBV_bit6_PartialNtwInfBit_1E384001 0;
BA_ "GenSigTimeoutTime_BSM" SG_ 2654486529 CBV_bit7_1E384001 0;
BA_ "GenSigTimeoutTime_BSM2" SG_ 2654486529 CBV_bit7_1E384001 0;
BA_ "GenSigTimeoutTime_CADM" SG_ 2654486529 CBV_bit7_1E384001 0;
BA_ "GenSigTimeoutTime_CVPAM" SG_ 2654486529 CBV_bit7_1E384001 0;
BA_ "GenSigTimeoutTime_ECM" SG_ 2654486529 CBV_bit7_1E384001 0;
BA_ "GenSigTimeoutTime_EPS" SG_ 2654486529 CBV_bit7_1E384001 0;
BA_ "GenSigTimeoutTime_EVCU2" SG_ 2654486529 CBV_bit7_1E384001 0;
BA_ "GenSigTimeoutTime_ORC" SG_ 2654486529 CBV_bit7_1E384001 0;
BA_ "GenSigTimeoutTime_BSM" SG_ 2654486529 SourceNodeIdentifier_1E384001 0;
BA_ "GenSigTimeoutTime_BSM2" SG_ 2654486529 SourceNodeIdentifier_1E384001 0;
BA_ "GenSigTimeoutTime_CADM" SG_ 2654486529 SourceNodeIdentifier_1E384001 0;
BA_ "GenSigTimeoutTime_CVPAM" SG_ 2654486529 SourceNodeIdentifier_1E384001 0;
BA_ "GenSigTimeoutTime_ECM" SG_ 2654486529 SourceNodeIdentifier_1E384001 0;
BA_ "GenSigTimeoutTime_EPS" SG_ 2654486529 SourceNodeIdentifier_1E384001 0;
BA_ "GenSigTimeoutTime_EVCU2" SG_ 2654486529 SourceNodeIdentifier_1E384001 0;
BA_ "GenSigTimeoutTime_ORC" SG_ 2654486529 SourceNodeIdentifier_1E384001 0;
BA_ "GenSigTimeoutTime_MPAD" SG_ 1456 Driver_Model 0;
BA_ "GenSigTimeoutTime_ADCAM" SG_ 1456 Driver_Model 0;
BA_ "GenSigTimeoutTime_CVADAS" SG_ 1456 Driver_Model 0;
BA_ "GenSigTimeoutTime_MPAD" SG_ 1456 ACC_FailSts 0;
BA_ "GenSigTimeoutTime_ADCAM" SG_ 1456 ACC_FailSts 0;
BA_ "GenSigTimeoutTime_CVADAS" SG_ 1456 ACC_FailSts 0;
BA_ "GenSigTimeoutTime_VDCM" SG_ 1456 ACC_FailSts 0;
BA_ "GenSigTimeoutTime_MPAD" SG_ 1456 ACC_DispPopupSts 0;
BA_ "GenSigTimeoutTime_ADCAM" SG_ 1456 ACC_DispPopupSts 0;
BA_ "GenSigTimeoutTime_CVADAS" SG_ 1456 ACC_DispPopupSts 0;
BA_ "GenSigTimeoutTime_VDCM" SG_ 1456 ACC_DispPopupSts 0;
BA_ "GenSigTimeoutTime_MPAD" SG_ 1456 ACC_Limited 0;
BA_ "GenSigTimeoutTime_ADCAM" SG_ 1456 ACC_Limited 0;
BA_ "GenSigTimeoutTime_CVADAS" SG_ 1456 ACC_Limited 0;
BA_ "GenSigTimeoutTime_VDCM" SG_ 1456 ACC_Limited 0;
BA_ "GenSigTimeoutTime_MPAD" SG_ 1456 ACC_Limit_Fail 0;
BA_ "GenSigTimeoutTime_ADCAM" SG_ 1456 ACC_Limit_Fail 0;
BA_ "GenSigTimeoutTime_CVADAS" SG_ 1456 ACC_Limit_Fail 0;
BA_ "GenSigTimeoutTime_VDCM" SG_ 1456 ACC_Limit_Fail 0;
BA_ "GenSigTimeoutTime_MPAD" SG_ 1456 BlindSpotLeftWarn 0;
BA_ "GenSigTimeoutTime_ADCAM" SG_ 1456 BlindSpotLeftWarn 0;
BA_ "GenSigTimeoutTime_CVADAS" SG_ 1456 BlindSpotLeftWarn 0;
BA_ "GenSigTimeoutTime_VDCM" SG_ 1456 BlindSpotLeftWarn 0;
BA_ "GenSigTimeoutTime_MPAD" SG_ 1456 BlindSpotRightWarn 0;
BA_ "GenSigTimeoutTime_ADCAM" SG_ 1456 BlindSpotRightWarn 0;
BA_ "GenSigTimeoutTime_CVADAS" SG_ 1456 BlindSpotRightWarn 0;
BA_ "GenSigTimeoutTime_VDCM" SG_ 1456 BlindSpotRightWarn 0;
BA_ "GenSigTimeoutTime_MPAD" SG_ 1456 Chime_TypSts 0;
BA_ "GenSigTimeoutTime_ADCAM" SG_ 1456 Chime_TypSts 0;
BA_ "GenSigTimeoutTime_CVADAS" SG_ 1456 Chime_TypSts 0;
BA_ "GenSigTimeoutTime_VDCM" SG_ 1456 Chime_TypSts 0;
BA_ "GenSigTimeoutTime_MPAD" SG_ 1456 Chime_RepRate 0;
BA_ "GenSigTimeoutTime_ADCAM" SG_ 1456 Chime_RepRate 0;
BA_ "GenSigTimeoutTime_CVADAS" SG_ 1456 Chime_RepRate 0;
BA_ "GenSigTimeoutTime_VDCM" SG_ 1456 Chime_RepRate 0;
BA_ "GenSigTimeoutTime_MPAD" SG_ 1456 ACC_Set_Speed_Strike 0;
BA_ "GenSigTimeoutTime_ADCAM" SG_ 1456 ACC_Set_Speed_Strike 0;
BA_ "GenSigTimeoutTime_CVADAS" SG_ 1456 ACC_Set_Speed_Strike 0;
BA_ "GenSigTimeoutTime_VDCM" SG_ 1456 ACC_Set_Speed_Strike 0;
BA_ "GenSigTimeoutTime_MPAD" SG_ 1456 AEB_Blind 0;
BA_ "GenSigTimeoutTime_ADCAM" SG_ 1456 AEB_Blind 0;
BA_ "GenSigTimeoutTime_CVADAS" SG_ 1456 AEB_Blind 0;
BA_ "GenSigTimeoutTime_VDCM" SG_ 1456 AEB_Blind 0;
BA_ "GenSigTimeoutTime_MPAD" SG_ 1456 AEB_FailSts 0;
BA_ "GenSigTimeoutTime_ADCAM" SG_ 1456 AEB_FailSts 0;
BA_ "GenSigTimeoutTime_CVADAS" SG_ 1456 AEB_FailSts 0;
BA_ "GenSigTimeoutTime_VDCM" SG_ 1456 AEB_FailSts 0;
BA_ "GenSigTimeoutTime_BSM2" SG_ 1456 AEB_FailSts 0;
BA_ "GenSigTimeoutTime_MPAD" SG_ 1456 AEB_DispPopupSts 0;
BA_ "GenSigTimeoutTime_ADCAM" SG_ 1456 AEB_DispPopupSts 0;
BA_ "GenSigTimeoutTime_CVADAS" SG_ 1456 AEB_DispPopupSts 0;
BA_ "GenSigTimeoutTime_VDCM" SG_ 1456 AEB_DispPopupSts 0;
BA_ "GenSigTimeoutTime_MPAD" SG_ 1456 AEB_Limited 0;
BA_ "GenSigTimeoutTime_ADCAM" SG_ 1456 AEB_Limited 0;
BA_ "GenSigTimeoutTime_CVADAS" SG_ 1456 AEB_Limited 0;
BA_ "GenSigTimeoutTime_VDCM" SG_ 1456 AEB_Limited 0;
BA_ "GenSigTimeoutTime_MPAD" SG_ 1456 AEB_Limit_Fail 0;
BA_ "GenSigTimeoutTime_ADCAM" SG_ 1456 AEB_Limit_Fail 0;
BA_ "GenSigTimeoutTime_CVADAS" SG_ 1456 AEB_Limit_Fail 0;
BA_ "GenSigTimeoutTime_VDCM" SG_ 1456 AEB_Limit_Fail 0;
BA_ "GenSigTimeoutTime_MPAD" SG_ 1456 ACC_Blind 0;
BA_ "GenSigTimeoutTime_ADCAM" SG_ 1456 ACC_Blind 0;
BA_ "GenSigTimeoutTime_CVADAS" SG_ 1456 ACC_Blind 0;
BA_ "GenSigTimeoutTime_VDCM" SG_ 1456 ACC_Blind 0;
BA_ "GenSigTimeoutTime_MPAD" SG_ 1456 SVI_Request 0;
BA_ "GenSigTimeoutTime_ADCAM" SG_ 1456 SVI_Request 0;
BA_ "GenSigTimeoutTime_CVADAS" SG_ 1456 SVI_Request 0;
BA_ "GenSigTimeoutTime_VDCM" SG_ 1456 SVI_Request 0;
BA_ "GenSigSendType" SG_ 1456 Set_Speed_KPH 3;
BA_ "GenSigTimeoutTime_BSM" SG_ 1456 Set_Speed_KPH 0;
BA_ "GenSigTimeoutTime_BSM2" SG_ 1456 Set_Speed_KPH 0;
BA_ "GenSigTimeoutTime_CADM" SG_ 1456 Set_Speed_KPH 0;
BA_ "GenSigTimeoutTime_CVPAM" SG_ 1456 Set_Speed_KPH 0;
BA_ "GenSigTimeoutTime_EPS" SG_ 1456 Set_Speed_KPH 0;
BA_ "GenSigTimeoutTime_MPAD" SG_ 1456 Set_Speed_KPH 0;
BA_ "GenSigTimeoutTime_ADCAM" SG_ 1456 Set_Speed_KPH 0;
BA_ "GenSigTimeoutTime_CVADAS" SG_ 1456 Set_Speed_KPH 0;
BA_ "GenSigTimeoutTime_VDCM" SG_ 1456 Set_Speed_KPH 0;
BA_ "GenSigTimeoutTime_MPAD" SG_ 1456 Set_Speed_MPH 0;
BA_ "GenSigTimeoutTime_ADCAM" SG_ 1456 Set_Speed_MPH 0;
BA_ "GenSigTimeoutTime_CVADAS" SG_ 1456 Set_Speed_MPH 0;
BA_ "GenSigTimeoutTime_VDCM" SG_ 1456 Set_Speed_MPH 0;
BA_ "GenSigTimeoutTime_MPAD" SG_ 1456 NCC_FailSts 0;
BA_ "GenSigTimeoutTime_ADCAM" SG_ 1456 NCC_FailSts 0;
BA_ "GenSigTimeoutTime_CVADAS" SG_ 1456 NCC_FailSts 0;
BA_ "GenSigTimeoutTime_VDCM" SG_ 1456 NCC_FailSts 0;
BA_ "GenSigSendType" SG_ 1456 RF_Chime_RqSts 3;
BA_ "GenSigTimeoutTime_BSM" SG_ 1456 RF_Chime_RqSts 0;
BA_ "GenSigTimeoutTime_BSM2" SG_ 1456 RF_Chime_RqSts 0;
BA_ "GenSigTimeoutTime_CADM" SG_ 1456 RF_Chime_RqSts 0;
BA_ "GenSigTimeoutTime_CVPAM" SG_ 1456 RF_Chime_RqSts 0;
BA_ "GenSigTimeoutTime_ECM" SG_ 1456 RF_Chime_RqSts 0;
BA_ "GenSigTimeoutTime_EPS" SG_ 1456 RF_Chime_RqSts 0;
BA_ "GenSigTimeoutTime_EVCU2" SG_ 1456 RF_Chime_RqSts 0;
BA_ "GenSigTimeoutTime_MPAD" SG_ 1456 RF_Chime_RqSts 0;
BA_ "GenSigTimeoutTime_ADCAM" SG_ 1456 RF_Chime_RqSts 0;
BA_ "GenSigTimeoutTime_CVADAS" SG_ 1456 RF_Chime_RqSts 0;
BA_ "GenSigTimeoutTime_VDCM" SG_ 1456 RF_Chime_RqSts 0;
BA_ "GenSigTimeoutTime_MPAD" SG_ 1456 PEB_Setting_Avail 0;
BA_ "GenSigTimeoutTime_ADCAM" SG_ 1456 PEB_Setting_Avail 0;
BA_ "GenSigTimeoutTime_CVADAS" SG_ 1456 PEB_Setting_Avail 0;
BA_ "GenSigTimeoutTime_VDCM" SG_ 1456 PEB_Setting_Avail 0;
BA_ "GenSigTimeoutTime_MPAD" SG_ 1456 ICA_Blind 0;
BA_ "GenSigTimeoutTime_ADCAM" SG_ 1456 ICA_Blind 0;
BA_ "GenSigTimeoutTime_CVADAS" SG_ 1456 ICA_Blind 0;
BA_ "GenSigTimeoutTime_VDCM" SG_ 1456 ICA_Blind 0;
BA_ "GenSigTimeoutTime_MPAD" SG_ 1456 Lane_DisplaySts_Left 0;
BA_ "GenSigTimeoutTime_ADCAM" SG_ 1456 Lane_DisplaySts_Left 0;
BA_ "GenSigTimeoutTime_CVADAS" SG_ 1456 Lane_DisplaySts_Left 0;
BA_ "GenSigTimeoutTime_VDCM" SG_ 1456 Lane_DisplaySts_Left 0;
BA_ "GenSigTimeoutTime_MPAD" SG_ 1456 Lane_DisplaySts_Right 0;
BA_ "GenSigTimeoutTime_ADCAM" SG_ 1456 Lane_DisplaySts_Right 0;
BA_ "GenSigTimeoutTime_CVADAS" SG_ 1456 Lane_DisplaySts_Right 0;
BA_ "GenSigTimeoutTime_VDCM" SG_ 1456 Lane_DisplaySts_Right 0;
BA_ "GenSigTimeoutTime_MPAD" SG_ 1456 LF_Chime_RqSts 0;
BA_ "GenSigTimeoutTime_ADCAM" SG_ 1456 LF_Chime_RqSts 0;
BA_ "GenSigTimeoutTime_CVADAS" SG_ 1456 LF_Chime_RqSts 0;
BA_ "GenSigTimeoutTime_VDCM" SG_ 1456 LF_Chime_RqSts 0;
BA_ "GenSigTimeoutTime_MPAD" SG_ 1456 LKA_Blind 0;
BA_ "GenSigTimeoutTime_ADCAM" SG_ 1456 LKA_Blind 0;
BA_ "GenSigTimeoutTime_CVADAS" SG_ 1456 LKA_Blind 0;
BA_ "GenSigTimeoutTime_VDCM" SG_ 1456 LKA_Blind 0;
BA_ "GenSigTimeoutTime_MPAD" SG_ 1456 LKA_FailSts 0;
BA_ "GenSigTimeoutTime_ADCAM" SG_ 1456 LKA_FailSts 0;
BA_ "GenSigTimeoutTime_CVADAS" SG_ 1456 LKA_FailSts 0;
BA_ "GenSigTimeoutTime_VDCM" SG_ 1456 LKA_FailSts 0;
BA_ "GenSigTimeoutTime_MPAD" SG_ 1456 LKA_Status 0;
BA_ "GenSigTimeoutTime_ADCAM" SG_ 1456 LKA_Status 0;
BA_ "GenSigTimeoutTime_CVADAS" SG_ 1456 LKA_Status 0;
BA_ "GenSigTimeoutTime_VDCM" SG_ 1456 LKA_Status 0;
BA_ "GenSigTimeoutTime_MPAD" SG_ 1456 DDD_DispPopupSts 0;
BA_ "GenSigTimeoutTime_ADCAM" SG_ 1456 DDD_DispPopupSts 0;
BA_ "GenSigTimeoutTime_CVADAS" SG_ 1456 DDD_DispPopupSts 0;
BA_ "GenSigTimeoutTime_VDCM" SG_ 1456 DDD_DispPopupSts 0;
BA_ "GenSigTimeoutTime_MPAD" SG_ 1456 DisplaySts_ACC 0;
BA_ "GenSigTimeoutTime_ADCAM" SG_ 1456 DisplaySts_ACC 0;
BA_ "GenSigTimeoutTime_CVADAS" SG_ 1456 DisplaySts_ACC 0;
BA_ "GenSigTimeoutTime_VDCM" SG_ 1456 DisplaySts_ACC 0;
BA_ "GenSigTimeoutTime_MPAD" SG_ 1456 DDD_FailSts 0;
BA_ "GenSigTimeoutTime_ADCAM" SG_ 1456 DDD_FailSts 0;
BA_ "GenSigTimeoutTime_CVADAS" SG_ 1456 DDD_FailSts 0;
BA_ "GenSigTimeoutTime_VDCM" SG_ 1456 DDD_FailSts 0;
BA_ "GenSigTimeoutTime_MPAD" SG_ 1456 DisplaySts_Curve 0;
BA_ "GenSigTimeoutTime_ADCAM" SG_ 1456 DisplaySts_Curve 0;
BA_ "GenSigTimeoutTime_CVADAS" SG_ 1456 DisplaySts_Curve 0;
BA_ "GenSigTimeoutTime_MPAD" SG_ 1456 HAS_Blind 0;
BA_ "GenSigTimeoutTime_ADCAM" SG_ 1456 HAS_Blind 0;
BA_ "GenSigTimeoutTime_CVADAS" SG_ 1456 HAS_Blind 0;
BA_ "GenSigTimeoutTime_VDCM" SG_ 1456 HAS_Blind 0;
BA_ "GenSigTimeoutTime_MPAD" SG_ 1456 DisplaySts_OFF 0;
BA_ "GenSigTimeoutTime_ADCAM" SG_ 1456 DisplaySts_OFF 0;
BA_ "GenSigTimeoutTime_CVADAS" SG_ 1456 DisplaySts_OFF 0;
BA_ "GenSigTimeoutTime_VDCM" SG_ 1456 DisplaySts_OFF 0;
BA_ "GenSigTimeoutTime_MPAD" SG_ 1456 DisplaySts_Veh 0;
BA_ "GenSigTimeoutTime_ADCAM" SG_ 1456 DisplaySts_Veh 0;
BA_ "GenSigTimeoutTime_CVADAS" SG_ 1456 DisplaySts_Veh 0;
BA_ "GenSigTimeoutTime_VDCM" SG_ 1456 DisplaySts_Veh 0;
BA_ "GenSigTimeoutTime_MPAD" SG_ 1456 FCW_Setting_Avail 0;
BA_ "GenSigTimeoutTime_ADCAM" SG_ 1456 FCW_Setting_Avail 0;
BA_ "GenSigTimeoutTime_CVADAS" SG_ 1456 FCW_Setting_Avail 0;
BA_ "GenSigTimeoutTime_VDCM" SG_ 1456 FCW_Setting_Avail 0;
BA_ "GenSigTimeoutTime_MPAD" SG_ 1456 HAS_Escalation_Sts 0;
BA_ "GenSigTimeoutTime_ADCAM" SG_ 1456 HAS_Escalation_Sts 0;
BA_ "GenSigTimeoutTime_CVADAS" SG_ 1456 HAS_Escalation_Sts 0;
BA_ "GenSigTimeoutTime_MPAD" SG_ 1456 HAS_FailSts 0;
BA_ "GenSigTimeoutTime_ADCAM" SG_ 1456 HAS_FailSts 0;
BA_ "GenSigTimeoutTime_CVADAS" SG_ 1456 HAS_FailSts 0;
BA_ "GenSigTimeoutTime_VDCM" SG_ 1456 HAS_FailSts 0;
BA_ "GenSigTimeoutTime_MPAD" SG_ 1456 HAS_TelltaleSts 0;
BA_ "GenSigTimeoutTime_ADCAM" SG_ 1456 HAS_TelltaleSts 0;
BA_ "GenSigTimeoutTime_CVADAS" SG_ 1456 HAS_TelltaleSts 0;
BA_ "GenSigTimeoutTime_VDCM" SG_ 1456 HAS_TelltaleSts 0;
BA_ "GenSigTimeoutTime_MPAD" SG_ 1456 HAS_TurnSignalRequest 0;
BA_ "GenSigTimeoutTime_ADCAM" SG_ 1456 HAS_TurnSignalRequest 0;
BA_ "GenSigTimeoutTime_CVADAS" SG_ 1456 HAS_TurnSignalRequest 0;
BA_ "GenSigTimeoutTime_MPAD" SG_ 1456 BSS_CFG_STATSts 0;
BA_ "GenSigTimeoutTime_ADCAM" SG_ 1456 BSS_CFG_STATSts 0;
BA_ "GenSigTimeoutTime_CVADAS" SG_ 1456 BSS_CFG_STATSts 0;
BA_ "GenSigTimeoutTime_VDCM" SG_ 1456 BSS_CFG_STATSts 0;
BA_ "GenSigTimeoutTime_MPAD" SG_ 1456 BSS_SRV_RQSts 0;
BA_ "GenSigTimeoutTime_ADCAM" SG_ 1456 BSS_SRV_RQSts 0;
BA_ "GenSigTimeoutTime_CVADAS" SG_ 1456 BSS_SRV_RQSts 0;
BA_ "GenSigTimeoutTime_VDCM" SG_ 1456 BSS_SRV_RQSts 0;
BA_ "GenSigTimeoutTime_MPAD" SG_ 1456 RR_Chime_RqSts 0;
BA_ "GenSigTimeoutTime_ADCAM" SG_ 1456 RR_Chime_RqSts 0;
BA_ "GenSigTimeoutTime_CVADAS" SG_ 1456 RR_Chime_RqSts 0;
BA_ "GenSigTimeoutTime_VDCM" SG_ 1456 RR_Chime_RqSts 0;
BA_ "GenSigTimeoutTime_MPAD" SG_ 1456 BSS_Blind_RQSts 0;
BA_ "GenSigTimeoutTime_ADCAM" SG_ 1456 BSS_Blind_RQSts 0;
BA_ "GenSigTimeoutTime_CVADAS" SG_ 1456 BSS_Blind_RQSts 0;
BA_ "GenSigTimeoutTime_VDCM" SG_ 1456 BSS_Blind_RQSts 0;
BA_ "GenSigTimeoutTime_MPAD" SG_ 1456 CRC_ADAS_FD_HMI 0;
BA_ "GenSigTimeoutTime_ADCAM" SG_ 1456 CRC_ADAS_FD_HMI 0;
BA_ "GenSigTimeoutTime_CVADAS" SG_ 1456 CRC_ADAS_FD_HMI 0;
BA_ "GenSigTimeoutTime_VDCM" SG_ 1456 CRC_ADAS_FD_HMI 0;
BA_ "GenSigTimeoutTime_ECM" SG_ 1456 CRC_ADAS_FD_HMI 0;
BA_ "GenSigTimeoutTime_ADCAM" SG_ 1456 Chime_Priority 0;
BA_ "GenSigTimeoutTime_CVADAS" SG_ 1456 Chime_Priority 0;
BA_ "GenSigTimeoutTime_VDCM" SG_ 1456 Chime_Priority 0;
BA_ "GenSigTimeoutTime_MPAD" SG_ 1456 Chime_Priority 0;
BA_ "GenSigTimeoutTime_MPAD" SG_ 1456 MessageCounter_ADAS_FD_HMI 0;
BA_ "GenSigTimeoutTime_ADCAM" SG_ 1456 MessageCounter_ADAS_FD_HMI 0;
BA_ "GenSigTimeoutTime_CVADAS" SG_ 1456 MessageCounter_ADAS_FD_HMI 0;
BA_ "GenSigTimeoutTime_VDCM" SG_ 1456 MessageCounter_ADAS_FD_HMI 0;
BA_ "GenSigTimeoutTime_ECM" SG_ 1456 MessageCounter_ADAS_FD_HMI 0;
BA_ "GenSigTimeoutTime_MPAD" SG_ 1456 LR_Chime_RqSts 0;
BA_ "GenSigTimeoutTime_ADCAM" SG_ 1456 LR_Chime_RqSts 0;
BA_ "GenSigTimeoutTime_CVADAS" SG_ 1456 LR_Chime_RqSts 0;
BA_ "GenSigTimeoutTime_VDCM" SG_ 1456 LR_Chime_RqSts 0;
BA_ "GenSigTimeoutTime_MPAD" SG_ 1456 Lane_DispPopupSts 0;
BA_ "GenSigTimeoutTime_ADCAM" SG_ 1456 Lane_DispPopupSts 0;
BA_ "GenSigTimeoutTime_CVADAS" SG_ 1456 Lane_DispPopupSts 0;
BA_ "GenSigTimeoutTime_VDCM" SG_ 1456 Lane_DispPopupSts 0;
BA_ "GenSigTimeoutTime_MPAD" SG_ 1456 SVI_Request_ext 0;
BA_ "GenSigTimeoutTime_ADCAM" SG_ 1456 SVI_Request_ext 0;
BA_ "GenSigTimeoutTime_CVADAS" SG_ 1456 SVI_Request_ext 0;
BA_ "GenSigSendType" SG_ 1456 SVI_Request_ext 3;
BA_ "GenSigTimeoutTime_BSM" SG_ 1456 SVI_Request_ext 0;
BA_ "GenSigTimeoutTime_BSM2" SG_ 1456 SVI_Request_ext 0;
BA_ "GenSigTimeoutTime_EPS" SG_ 1456 SVI_Request_ext 0;
BA_ "GenSigTimeoutTime_EVCU2" SG_ 1456 SVI_Request_ext 0;
BA_ "GenSigTimeoutTime_ORC" SG_ 1456 SVI_Request_ext 0;
BA_ "GenSigTimeoutTime_MPAD" SG_ 1456 DisplaySts_Route 0;
BA_ "GenSigTimeoutTime_ADCAM" SG_ 1456 DisplaySts_Route 0;
BA_ "GenSigTimeoutTime_CVADAS" SG_ 1456 DisplaySts_Route 0;
BA_ "GenSigSendType" SG_ 1456 DisplaySts_Route 3;
BA_ "GenSigTimeoutTime_BSM" SG_ 1456 DisplaySts_Route 0;
BA_ "GenSigTimeoutTime_BSM2" SG_ 1456 DisplaySts_Route 0;
BA_ "GenSigTimeoutTime_EPS" SG_ 1456 DisplaySts_Route 0;
BA_ "GenSigTimeoutTime_EVCU2" SG_ 1456 DisplaySts_Route 0;
BA_ "GenSigTimeoutTime_ORC" SG_ 1456 DisplaySts_Route 0;
BA_ "GenSigTimeoutTime_MPAD" SG_ 1456 DM_Camera_Block 0;
BA_ "GenSigTimeoutTime_ADCAM" SG_ 1456 DM_Camera_Block 0;
BA_ "GenSigTimeoutTime_CVADAS" SG_ 1456 DM_Camera_Block 0;
BA_ "GenSigSendType" SG_ 1456 DM_Camera_Block 3;
BA_ "GenSigTimeoutTime_BSM" SG_ 1456 DM_Camera_Block 0;
BA_ "GenSigTimeoutTime_BSM2" SG_ 1456 DM_Camera_Block 0;
BA_ "GenSigTimeoutTime_EPS" SG_ 1456 DM_Camera_Block 0;
BA_ "GenSigTimeoutTime_EVCU2" SG_ 1456 DM_Camera_Block 0;
BA_ "GenSigTimeoutTime_ORC" SG_ 1456 DM_Camera_Block 0;
BA_ "GenSigTimeoutTime_MPAD" SG_ 1456 HAS_TelltaleSts_ext 0;
BA_ "GenSigTimeoutTime_ADCAM" SG_ 1456 HAS_TelltaleSts_ext 0;
BA_ "GenSigTimeoutTime_CVADAS" SG_ 1456 HAS_TelltaleSts_ext 0;
BA_ "GenSigSendType" SG_ 1456 HAS_TelltaleSts_ext 3;
BA_ "GenSigTimeoutTime_BSM" SG_ 1456 HAS_TelltaleSts_ext 0;
BA_ "GenSigTimeoutTime_BSM2" SG_ 1456 HAS_TelltaleSts_ext 0;
BA_ "GenSigTimeoutTime_EPS" SG_ 1456 HAS_TelltaleSts_ext 0;
BA_ "GenSigTimeoutTime_EVCU2" SG_ 1456 HAS_TelltaleSts_ext 0;
BA_ "GenSigTimeoutTime_ORC" SG_ 1456 HAS_TelltaleSts_ext 0;
BA_ "GenSigSendType" SG_ 1456 BSS_Blind_RQSts 3;
BA_ "GenSigTimeoutTime_BSM" SG_ 1456 BSS_Blind_RQSts 0;
BA_ "GenSigTimeoutTime_BSM2" SG_ 1456 BSS_Blind_RQSts 0;
BA_ "GenSigTimeoutTime_CADM" SG_ 1456 BSS_Blind_RQSts 0;
BA_ "GenSigTimeoutTime_CVPAM" SG_ 1456 BSS_Blind_RQSts 0;
BA_ "GenSigTimeoutTime_ECM" SG_ 1456 BSS_Blind_RQSts 0;
BA_ "GenSigTimeoutTime_EPS" SG_ 1456 BSS_Blind_RQSts 0;
BA_ "GenSigTimeoutTime_EVCU2" SG_ 1456 BSS_Blind_RQSts 0;
BA_ "GenSigSendType" SG_ 1456 BSS_CFG_STATSts 3;
BA_ "GenSigTimeoutTime_BSM" SG_ 1456 BSS_CFG_STATSts 0;
BA_ "GenSigTimeoutTime_BSM2" SG_ 1456 BSS_CFG_STATSts 0;
BA_ "GenSigTimeoutTime_CADM" SG_ 1456 BSS_CFG_STATSts 0;
BA_ "GenSigTimeoutTime_CVPAM" SG_ 1456 BSS_CFG_STATSts 0;
BA_ "GenSigTimeoutTime_ECM" SG_ 1456 BSS_CFG_STATSts 0;
BA_ "GenSigTimeoutTime_EPS" SG_ 1456 BSS_CFG_STATSts 0;
BA_ "GenSigTimeoutTime_EVCU2" SG_ 1456 BSS_CFG_STATSts 0;
BA_ "GenSigSendType" SG_ 1456 HAS_TurnSignalRequest 3;
BA_ "GenSigTimeoutTime_BSM" SG_ 1456 HAS_TurnSignalRequest 0;
BA_ "GenSigTimeoutTime_BSM2" SG_ 1456 HAS_TurnSignalRequest 0;
BA_ "GenSigTimeoutTime_CADM" SG_ 1456 HAS_TurnSignalRequest 0;
BA_ "GenSigTimeoutTime_CVPAM" SG_ 1456 HAS_TurnSignalRequest 0;
BA_ "GenSigTimeoutTime_ECM" SG_ 1456 HAS_TurnSignalRequest 0;
BA_ "GenSigTimeoutTime_EPS" SG_ 1456 HAS_TurnSignalRequest 0;
BA_ "GenSigTimeoutTime_EVCU2" SG_ 1456 HAS_TurnSignalRequest 0;
BA_ "GenSigTimeoutTime_ORC" SG_ 1456 HAS_TurnSignalRequest 0;
BA_ "GenSigSendType" SG_ 1456 HAS_TelltaleSts 3;
BA_ "GenSigTimeoutTime_BSM" SG_ 1456 HAS_TelltaleSts 0;
BA_ "GenSigTimeoutTime_BSM2" SG_ 1456 HAS_TelltaleSts 0;
BA_ "GenSigTimeoutTime_CADM" SG_ 1456 HAS_TelltaleSts 0;
BA_ "GenSigTimeoutTime_CVPAM" SG_ 1456 HAS_TelltaleSts 0;
BA_ "GenSigTimeoutTime_ECM" SG_ 1456 HAS_TelltaleSts 0;
BA_ "GenSigTimeoutTime_EPS" SG_ 1456 HAS_TelltaleSts 0;
BA_ "GenSigTimeoutTime_EVCU2" SG_ 1456 HAS_TelltaleSts 0;
BA_ "GenSigSendType" SG_ 1456 HAS_FailSts 3;
BA_ "GenSigTimeoutTime_BSM" SG_ 1456 HAS_FailSts 0;
BA_ "GenSigTimeoutTime_BSM2" SG_ 1456 HAS_FailSts 0;
BA_ "GenSigTimeoutTime_CADM" SG_ 1456 HAS_FailSts 0;
BA_ "GenSigTimeoutTime_CVPAM" SG_ 1456 HAS_FailSts 0;
BA_ "GenSigTimeoutTime_ECM" SG_ 1456 HAS_FailSts 0;
BA_ "GenSigTimeoutTime_EPS" SG_ 1456 HAS_FailSts 0;
BA_ "GenSigTimeoutTime_EVCU2" SG_ 1456 HAS_FailSts 0;
BA_ "GenSigSendType" SG_ 1456 HAS_Escalation_Sts 3;
BA_ "GenSigTimeoutTime_BSM" SG_ 1456 HAS_Escalation_Sts 0;
BA_ "GenSigTimeoutTime_BSM2" SG_ 1456 HAS_Escalation_Sts 0;
BA_ "GenSigTimeoutTime_CADM" SG_ 1456 HAS_Escalation_Sts 0;
BA_ "GenSigTimeoutTime_CVPAM" SG_ 1456 HAS_Escalation_Sts 0;
BA_ "GenSigTimeoutTime_ECM" SG_ 1456 HAS_Escalation_Sts 0;
BA_ "GenSigTimeoutTime_EPS" SG_ 1456 HAS_Escalation_Sts 0;
BA_ "GenSigTimeoutTime_EVCU2" SG_ 1456 HAS_Escalation_Sts 0;
BA_ "GenSigTimeoutTime_ORC" SG_ 1456 HAS_Escalation_Sts 0;
BA_ "GenSigSendType" SG_ 1456 FCW_Setting_Avail 3;
BA_ "GenSigTimeoutTime_BSM" SG_ 1456 FCW_Setting_Avail 0;
BA_ "GenSigTimeoutTime_BSM2" SG_ 1456 FCW_Setting_Avail 0;
BA_ "GenSigTimeoutTime_CADM" SG_ 1456 FCW_Setting_Avail 0;
BA_ "GenSigTimeoutTime_CVPAM" SG_ 1456 FCW_Setting_Avail 0;
BA_ "GenSigTimeoutTime_ECM" SG_ 1456 FCW_Setting_Avail 0;
BA_ "GenSigTimeoutTime_EPS" SG_ 1456 FCW_Setting_Avail 0;
BA_ "GenSigTimeoutTime_EVCU2" SG_ 1456 FCW_Setting_Avail 0;
BA_ "GenSigTimeoutTime_ORC" SG_ 1456 FCW_Setting_Avail 0;
BA_ "GenSigSendType" SG_ 1456 DisplaySts_Veh 3;
BA_ "GenSigTimeoutTime_BSM" SG_ 1456 DisplaySts_Veh 0;
BA_ "GenSigTimeoutTime_BSM2" SG_ 1456 DisplaySts_Veh 0;
BA_ "GenSigTimeoutTime_CADM" SG_ 1456 DisplaySts_Veh 0;
BA_ "GenSigTimeoutTime_CVPAM" SG_ 1456 DisplaySts_Veh 0;
BA_ "GenSigTimeoutTime_ECM" SG_ 1456 DisplaySts_Veh 0;
BA_ "GenSigTimeoutTime_EPS" SG_ 1456 DisplaySts_Veh 0;
BA_ "GenSigTimeoutTime_EVCU2" SG_ 1456 DisplaySts_Veh 0;
BA_ "GenSigTimeoutTime_ORC" SG_ 1456 DisplaySts_Veh 0;
BA_ "GenSigSendType" SG_ 1456 DisplaySts_OFF 3;
BA_ "GenSigTimeoutTime_BSM" SG_ 1456 DisplaySts_OFF 0;
BA_ "GenSigTimeoutTime_BSM2" SG_ 1456 DisplaySts_OFF 0;
BA_ "GenSigTimeoutTime_CADM" SG_ 1456 DisplaySts_OFF 0;
BA_ "GenSigTimeoutTime_CVPAM" SG_ 1456 DisplaySts_OFF 0;
BA_ "GenSigTimeoutTime_ECM" SG_ 1456 DisplaySts_OFF 0;
BA_ "GenSigTimeoutTime_EPS" SG_ 1456 DisplaySts_OFF 0;
BA_ "GenSigTimeoutTime_EVCU2" SG_ 1456 DisplaySts_OFF 0;
BA_ "GenSigTimeoutTime_ORC" SG_ 1456 DisplaySts_OFF 0;
BA_ "GenSigSendType" SG_ 1456 HAS_Blind 3;
BA_ "GenSigTimeoutTime_BSM" SG_ 1456 HAS_Blind 0;
BA_ "GenSigTimeoutTime_BSM2" SG_ 1456 HAS_Blind 0;
BA_ "GenSigTimeoutTime_CADM" SG_ 1456 HAS_Blind 0;
BA_ "GenSigTimeoutTime_CVPAM" SG_ 1456 HAS_Blind 0;
BA_ "GenSigTimeoutTime_ECM" SG_ 1456 HAS_Blind 0;
BA_ "GenSigTimeoutTime_EPS" SG_ 1456 HAS_Blind 0;
BA_ "GenSigTimeoutTime_EVCU2" SG_ 1456 HAS_Blind 0;
BA_ "GenSigSendType" SG_ 1456 DisplaySts_Curve 3;
BA_ "GenSigTimeoutTime_BSM" SG_ 1456 DisplaySts_Curve 0;
BA_ "GenSigTimeoutTime_BSM2" SG_ 1456 DisplaySts_Curve 0;
BA_ "GenSigTimeoutTime_CADM" SG_ 1456 DisplaySts_Curve 0;
BA_ "GenSigTimeoutTime_CVPAM" SG_ 1456 DisplaySts_Curve 0;
BA_ "GenSigTimeoutTime_ECM" SG_ 1456 DisplaySts_Curve 0;
BA_ "GenSigTimeoutTime_EPS" SG_ 1456 DisplaySts_Curve 0;
BA_ "GenSigTimeoutTime_EVCU2" SG_ 1456 DisplaySts_Curve 0;
BA_ "GenSigTimeoutTime_ORC" SG_ 1456 DisplaySts_Curve 0;
BA_ "GenSigSendType" SG_ 1456 DDD_FailSts 3;
BA_ "GenSigTimeoutTime_BSM" SG_ 1456 DDD_FailSts 0;
BA_ "GenSigTimeoutTime_BSM2" SG_ 1456 DDD_FailSts 0;
BA_ "GenSigTimeoutTime_CADM" SG_ 1456 DDD_FailSts 0;
BA_ "GenSigTimeoutTime_CVPAM" SG_ 1456 DDD_FailSts 0;
BA_ "GenSigTimeoutTime_ECM" SG_ 1456 DDD_FailSts 0;
BA_ "GenSigTimeoutTime_EPS" SG_ 1456 DDD_FailSts 0;
BA_ "GenSigTimeoutTime_EVCU2" SG_ 1456 DDD_FailSts 0;
BA_ "GenSigTimeoutTime_ORC" SG_ 1456 DDD_FailSts 0;
BA_ "GenSigSendType" SG_ 1456 DisplaySts_ACC 3;
BA_ "GenSigTimeoutTime_BSM" SG_ 1456 DisplaySts_ACC 0;
BA_ "GenSigTimeoutTime_BSM2" SG_ 1456 DisplaySts_ACC 0;
BA_ "GenSigTimeoutTime_CADM" SG_ 1456 DisplaySts_ACC 0;
BA_ "GenSigTimeoutTime_CVPAM" SG_ 1456 DisplaySts_ACC 0;
BA_ "GenSigTimeoutTime_ECM" SG_ 1456 DisplaySts_ACC 0;
BA_ "GenSigTimeoutTime_EPS" SG_ 1456 DisplaySts_ACC 0;
BA_ "GenSigTimeoutTime_EVCU2" SG_ 1456 DisplaySts_ACC 0;
BA_ "GenSigSendType" SG_ 1456 DDD_DispPopupSts 3;
BA_ "GenSigTimeoutTime_BSM" SG_ 1456 DDD_DispPopupSts 0;
BA_ "GenSigTimeoutTime_BSM2" SG_ 1456 DDD_DispPopupSts 0;
BA_ "GenSigTimeoutTime_CADM" SG_ 1456 DDD_DispPopupSts 0;
BA_ "GenSigTimeoutTime_CVPAM" SG_ 1456 DDD_DispPopupSts 0;
BA_ "GenSigTimeoutTime_ECM" SG_ 1456 DDD_DispPopupSts 0;
BA_ "GenSigTimeoutTime_EPS" SG_ 1456 DDD_DispPopupSts 0;
BA_ "GenSigTimeoutTime_EVCU2" SG_ 1456 DDD_DispPopupSts 0;
BA_ "GenSigSendType" SG_ 1456 LKA_Status 3;
BA_ "GenSigTimeoutTime_BSM" SG_ 1456 LKA_Status 0;
BA_ "GenSigTimeoutTime_BSM2" SG_ 1456 LKA_Status 0;
BA_ "GenSigTimeoutTime_CADM" SG_ 1456 LKA_Status 0;
BA_ "GenSigTimeoutTime_CVPAM" SG_ 1456 LKA_Status 0;
BA_ "GenSigTimeoutTime_ECM" SG_ 1456 LKA_Status 0;
BA_ "GenSigTimeoutTime_EPS" SG_ 1456 LKA_Status 0;
BA_ "GenSigTimeoutTime_EVCU2" SG_ 1456 LKA_Status 0;
BA_ "GenSigSendType" SG_ 1456 LKA_FailSts 3;
BA_ "GenSigTimeoutTime_BSM" SG_ 1456 LKA_FailSts 0;
BA_ "GenSigTimeoutTime_BSM2" SG_ 1456 LKA_FailSts 0;
BA_ "GenSigTimeoutTime_CADM" SG_ 1456 LKA_FailSts 0;
BA_ "GenSigTimeoutTime_CVPAM" SG_ 1456 LKA_FailSts 0;
BA_ "GenSigTimeoutTime_ECM" SG_ 1456 LKA_FailSts 0;
BA_ "GenSigTimeoutTime_EPS" SG_ 1456 LKA_FailSts 0;
BA_ "GenSigTimeoutTime_EVCU2" SG_ 1456 LKA_FailSts 0;
BA_ "GenSigSendType" SG_ 1456 LKA_Blind 3;
BA_ "GenSigTimeoutTime_BSM" SG_ 1456 LKA_Blind 0;
BA_ "GenSigTimeoutTime_BSM2" SG_ 1456 LKA_Blind 0;
BA_ "GenSigTimeoutTime_CADM" SG_ 1456 LKA_Blind 0;
BA_ "GenSigTimeoutTime_CVPAM" SG_ 1456 LKA_Blind 0;
BA_ "GenSigTimeoutTime_ECM" SG_ 1456 LKA_Blind 0;
BA_ "GenSigTimeoutTime_EPS" SG_ 1456 LKA_Blind 0;
BA_ "GenSigTimeoutTime_EVCU2" SG_ 1456 LKA_Blind 0;
BA_ "GenSigSendType" SG_ 1456 LF_Chime_RqSts 3;
BA_ "GenSigTimeoutTime_BSM" SG_ 1456 LF_Chime_RqSts 0;
BA_ "GenSigTimeoutTime_BSM2" SG_ 1456 LF_Chime_RqSts 0;
BA_ "GenSigTimeoutTime_CADM" SG_ 1456 LF_Chime_RqSts 0;
BA_ "GenSigTimeoutTime_CVPAM" SG_ 1456 LF_Chime_RqSts 0;
BA_ "GenSigTimeoutTime_ECM" SG_ 1456 LF_Chime_RqSts 0;
BA_ "GenSigTimeoutTime_EPS" SG_ 1456 LF_Chime_RqSts 0;
BA_ "GenSigTimeoutTime_EVCU2" SG_ 1456 LF_Chime_RqSts 0;
BA_ "GenSigSendType" SG_ 1456 Lane_DisplaySts_Right 3;
BA_ "GenSigTimeoutTime_BSM" SG_ 1456 Lane_DisplaySts_Right 0;
BA_ "GenSigTimeoutTime_BSM2" SG_ 1456 Lane_DisplaySts_Right 0;
BA_ "GenSigTimeoutTime_CADM" SG_ 1456 Lane_DisplaySts_Right 0;
BA_ "GenSigTimeoutTime_CVPAM" SG_ 1456 Lane_DisplaySts_Right 0;
BA_ "GenSigTimeoutTime_ECM" SG_ 1456 Lane_DisplaySts_Right 0;
BA_ "GenSigTimeoutTime_EPS" SG_ 1456 Lane_DisplaySts_Right 0;
BA_ "GenSigTimeoutTime_EVCU2" SG_ 1456 Lane_DisplaySts_Right 0;
BA_ "GenSigSendType" SG_ 1456 Lane_DisplaySts_Left 3;
BA_ "GenSigTimeoutTime_BSM" SG_ 1456 Lane_DisplaySts_Left 0;
BA_ "GenSigTimeoutTime_BSM2" SG_ 1456 Lane_DisplaySts_Left 0;
BA_ "GenSigTimeoutTime_CADM" SG_ 1456 Lane_DisplaySts_Left 0;
BA_ "GenSigTimeoutTime_CVPAM" SG_ 1456 Lane_DisplaySts_Left 0;
BA_ "GenSigTimeoutTime_ECM" SG_ 1456 Lane_DisplaySts_Left 0;
BA_ "GenSigTimeoutTime_EPS" SG_ 1456 Lane_DisplaySts_Left 0;
BA_ "GenSigTimeoutTime_EVCU2" SG_ 1456 Lane_DisplaySts_Left 0;
BA_ "GenSigSendType" SG_ 1456 ICA_Blind 3;
BA_ "GenSigTimeoutTime_BSM" SG_ 1456 ICA_Blind 0;
BA_ "GenSigTimeoutTime_BSM2" SG_ 1456 ICA_Blind 0;
BA_ "GenSigTimeoutTime_CADM" SG_ 1456 ICA_Blind 0;
BA_ "GenSigTimeoutTime_CVPAM" SG_ 1456 ICA_Blind 0;
BA_ "GenSigTimeoutTime_ECM" SG_ 1456 ICA_Blind 0;
BA_ "GenSigTimeoutTime_EPS" SG_ 1456 ICA_Blind 0;
BA_ "GenSigTimeoutTime_EVCU2" SG_ 1456 ICA_Blind 0;
BA_ "GenSigTimeoutTime_ORC" SG_ 1456 ICA_Blind 0;
BA_ "GenSigSendType" SG_ 1456 PEB_Setting_Avail 3;
BA_ "GenSigTimeoutTime_BSM" SG_ 1456 PEB_Setting_Avail 0;
BA_ "GenSigTimeoutTime_BSM2" SG_ 1456 PEB_Setting_Avail 0;
BA_ "GenSigTimeoutTime_CADM" SG_ 1456 PEB_Setting_Avail 0;
BA_ "GenSigTimeoutTime_CVPAM" SG_ 1456 PEB_Setting_Avail 0;
BA_ "GenSigTimeoutTime_ECM" SG_ 1456 PEB_Setting_Avail 0;
BA_ "GenSigTimeoutTime_EPS" SG_ 1456 PEB_Setting_Avail 0;
BA_ "GenSigTimeoutTime_EVCU2" SG_ 1456 PEB_Setting_Avail 0;
BA_ "GenSigTimeoutTime_ORC" SG_ 1456 PEB_Setting_Avail 0;
BA_ "GenSigSendType" SG_ 1456 NCC_FailSts 3;
BA_ "GenSigTimeoutTime_BSM" SG_ 1456 NCC_FailSts 0;
BA_ "GenSigTimeoutTime_BSM2" SG_ 1456 NCC_FailSts 0;
BA_ "GenSigTimeoutTime_CADM" SG_ 1456 NCC_FailSts 0;
BA_ "GenSigTimeoutTime_CVPAM" SG_ 1456 NCC_FailSts 0;
BA_ "GenSigTimeoutTime_ECM" SG_ 1456 NCC_FailSts 0;
BA_ "GenSigTimeoutTime_EPS" SG_ 1456 NCC_FailSts 0;
BA_ "GenSigTimeoutTime_EVCU2" SG_ 1456 NCC_FailSts 0;
BA_ "GenSigSendType" SG_ 1456 Set_Speed_MPH 3;
BA_ "GenSigTimeoutTime_BSM" SG_ 1456 Set_Speed_MPH 0;
BA_ "GenSigTimeoutTime_BSM2" SG_ 1456 Set_Speed_MPH 0;
BA_ "GenSigTimeoutTime_CADM" SG_ 1456 Set_Speed_MPH 0;
BA_ "GenSigTimeoutTime_CVPAM" SG_ 1456 Set_Speed_MPH 0;
BA_ "GenSigTimeoutTime_EPS" SG_ 1456 Set_Speed_MPH 0;
BA_ "GenSigTimeoutTime_ORC" SG_ 1456 Set_Speed_MPH 0;
BA_ "GenSigSendType" SG_ 1456 SVI_Request 3;
BA_ "GenSigTimeoutTime_BSM" SG_ 1456 SVI_Request 0;
BA_ "GenSigTimeoutTime_BSM2" SG_ 1456 SVI_Request 0;
BA_ "GenSigTimeoutTime_CADM" SG_ 1456 SVI_Request 0;
BA_ "GenSigTimeoutTime_CVPAM" SG_ 1456 SVI_Request 0;
BA_ "GenSigTimeoutTime_ECM" SG_ 1456 SVI_Request 0;
BA_ "GenSigTimeoutTime_EPS" SG_ 1456 SVI_Request 0;
BA_ "GenSigTimeoutTime_EVCU2" SG_ 1456 SVI_Request 0;
BA_ "GenSigTimeoutTime_ORC" SG_ 1456 SVI_Request 0;
BA_ "GenSigSendType" SG_ 1456 AEB_Blind 3;
BA_ "GenSigTimeoutTime_BSM" SG_ 1456 AEB_Blind 0;
BA_ "GenSigTimeoutTime_BSM2" SG_ 1456 AEB_Blind 0;
BA_ "GenSigTimeoutTime_CADM" SG_ 1456 AEB_Blind 0;
BA_ "GenSigTimeoutTime_CVPAM" SG_ 1456 AEB_Blind 0;
BA_ "GenSigSendType" SG_ 1456 Chime_RepRate 3;
BA_ "GenSigTimeoutTime_BSM" SG_ 1456 Chime_RepRate 0;
BA_ "GenSigTimeoutTime_BSM2" SG_ 1456 Chime_RepRate 0;
BA_ "GenSigTimeoutTime_CADM" SG_ 1456 Chime_RepRate 0;
BA_ "GenSigTimeoutTime_CVPAM" SG_ 1456 Chime_RepRate 0;
BA_ "GenSigTimeoutTime_ECM" SG_ 1456 Chime_RepRate 0;
BA_ "GenSigTimeoutTime_EPS" SG_ 1456 Chime_RepRate 0;
BA_ "GenSigTimeoutTime_EVCU2" SG_ 1456 Chime_RepRate 0;
BA_ "GenSigTimeoutTime_ORC" SG_ 1456 Chime_RepRate 0;
BA_ "GenSigTimeoutTime_EPS" SG_ 1456 Chime_TypSts 0;
BA_ "GenSigTimeoutTime_EVCU2" SG_ 1456 Chime_TypSts 0;
BA_ "GenSigSendType" SG_ 1456 Chime_TypSts 3;
BA_ "GenSigTimeoutTime_BSM" SG_ 1456 Chime_TypSts 0;
BA_ "GenSigTimeoutTime_BSM2" SG_ 1456 Chime_TypSts 0;
BA_ "GenSigTimeoutTime_CADM" SG_ 1456 Chime_TypSts 0;
BA_ "GenSigTimeoutTime_CVPAM" SG_ 1456 Chime_TypSts 0;
BA_ "GenSigTimeoutTime_ECM" SG_ 1456 Chime_TypSts 0;
BA_ "GenSigSendType" SG_ 1456 BlindSpotRightWarn 3;
BA_ "GenSigTimeoutTime_BSM" SG_ 1456 BlindSpotRightWarn 0;
BA_ "GenSigTimeoutTime_BSM2" SG_ 1456 BlindSpotRightWarn 0;
BA_ "GenSigTimeoutTime_CADM" SG_ 1456 BlindSpotRightWarn 0;
BA_ "GenSigTimeoutTime_CVPAM" SG_ 1456 BlindSpotRightWarn 0;
BA_ "GenSigTimeoutTime_ECM" SG_ 1456 BlindSpotRightWarn 0;
BA_ "GenSigTimeoutTime_EPS" SG_ 1456 BlindSpotRightWarn 0;
BA_ "GenSigTimeoutTime_EVCU2" SG_ 1456 BlindSpotRightWarn 0;
BA_ "GenSigSendType" SG_ 1456 BlindSpotLeftWarn 3;
BA_ "GenSigTimeoutTime_BSM" SG_ 1456 BlindSpotLeftWarn 0;
BA_ "GenSigTimeoutTime_BSM2" SG_ 1456 BlindSpotLeftWarn 0;
BA_ "GenSigTimeoutTime_CADM" SG_ 1456 BlindSpotLeftWarn 0;
BA_ "GenSigTimeoutTime_CVPAM" SG_ 1456 BlindSpotLeftWarn 0;
BA_ "GenSigTimeoutTime_ECM" SG_ 1456 BlindSpotLeftWarn 0;
BA_ "GenSigTimeoutTime_EPS" SG_ 1456 BlindSpotLeftWarn 0;
BA_ "GenSigTimeoutTime_EVCU2" SG_ 1456 BlindSpotLeftWarn 0;
BA_ "GenSigSendType" SG_ 1456 AEB_Limit_Fail 3;
BA_ "GenSigTimeoutTime_BSM" SG_ 1456 AEB_Limit_Fail 0;
BA_ "GenSigTimeoutTime_BSM2" SG_ 1456 AEB_Limit_Fail 0;
BA_ "GenSigTimeoutTime_CADM" SG_ 1456 AEB_Limit_Fail 0;
BA_ "GenSigTimeoutTime_CVPAM" SG_ 1456 AEB_Limit_Fail 0;
BA_ "GenSigTimeoutTime_ECM" SG_ 1456 AEB_Limit_Fail 0;
BA_ "GenSigTimeoutTime_EPS" SG_ 1456 AEB_Limit_Fail 0;
BA_ "GenSigTimeoutTime_EVCU2" SG_ 1456 AEB_Limit_Fail 0;
BA_ "GenSigSendType" SG_ 1456 AEB_Limited 3;
BA_ "GenSigTimeoutTime_BSM" SG_ 1456 AEB_Limited 0;
BA_ "GenSigTimeoutTime_BSM2" SG_ 1456 AEB_Limited 0;
BA_ "GenSigTimeoutTime_CADM" SG_ 1456 AEB_Limited 0;
BA_ "GenSigTimeoutTime_CVPAM" SG_ 1456 AEB_Limited 0;
BA_ "GenSigTimeoutTime_ECM" SG_ 1456 AEB_Limited 0;
BA_ "GenSigTimeoutTime_EPS" SG_ 1456 AEB_Limited 0;
BA_ "GenSigTimeoutTime_EVCU2" SG_ 1456 AEB_Limited 0;
BA_ "GenSigSendType" SG_ 1456 ACC_Set_Speed_Strike 3;
BA_ "GenSigTimeoutTime_BSM" SG_ 1456 ACC_Set_Speed_Strike 0;
BA_ "GenSigTimeoutTime_BSM2" SG_ 1456 ACC_Set_Speed_Strike 0;
BA_ "GenSigTimeoutTime_CADM" SG_ 1456 ACC_Set_Speed_Strike 0;
BA_ "GenSigTimeoutTime_CVPAM" SG_ 1456 ACC_Set_Speed_Strike 0;
BA_ "GenSigTimeoutTime_ECM" SG_ 1456 ACC_Set_Speed_Strike 0;
BA_ "GenSigTimeoutTime_EPS" SG_ 1456 ACC_Set_Speed_Strike 0;
BA_ "GenSigTimeoutTime_EVCU2" SG_ 1456 ACC_Set_Speed_Strike 0;
BA_ "GenSigTimeoutTime_ORC" SG_ 1456 ACC_Set_Speed_Strike 0;
BA_ "GenSigTimeoutTime_ECM" SG_ 1456 AEB_Blind 0;
BA_ "GenSigTimeoutTime_EPS" SG_ 1456 AEB_Blind 0;
BA_ "GenSigTimeoutTime_EVCU2" SG_ 1456 AEB_Blind 0;
BA_ "GenSigSendType" SG_ 1456 ACC_Limited 3;
BA_ "GenSigTimeoutTime_BSM" SG_ 1456 ACC_Limited 0;
BA_ "GenSigTimeoutTime_BSM2" SG_ 1456 ACC_Limited 0;
BA_ "GenSigTimeoutTime_CADM" SG_ 1456 ACC_Limited 0;
BA_ "GenSigTimeoutTime_CVPAM" SG_ 1456 ACC_Limited 0;
BA_ "GenSigTimeoutTime_ECM" SG_ 1456 ACC_Limited 0;
BA_ "GenSigTimeoutTime_EPS" SG_ 1456 ACC_Limited 0;
BA_ "GenSigTimeoutTime_EVCU2" SG_ 1456 ACC_Limited 0;
BA_ "GenSigSendType" SG_ 1456 AEB_FailSts 3;
BA_ "GenSigTimeoutTime_CADM" SG_ 1456 AEB_FailSts 0;
BA_ "GenSigTimeoutTime_CVPAM" SG_ 1456 AEB_FailSts 0;
BA_ "GenSigTimeoutTime_ECM" SG_ 1456 AEB_FailSts 0;
BA_ "GenSigTimeoutTime_EPS" SG_ 1456 AEB_FailSts 0;
BA_ "GenSigTimeoutTime_EVCU2" SG_ 1456 AEB_FailSts 0;
BA_ "GenSigSendType" SG_ 1456 AEB_DispPopupSts 3;
BA_ "GenSigTimeoutTime_BSM" SG_ 1456 AEB_DispPopupSts 0;
BA_ "GenSigTimeoutTime_BSM2" SG_ 1456 AEB_DispPopupSts 0;
BA_ "GenSigTimeoutTime_CADM" SG_ 1456 AEB_DispPopupSts 0;
BA_ "GenSigTimeoutTime_CVPAM" SG_ 1456 AEB_DispPopupSts 0;
BA_ "GenSigTimeoutTime_ECM" SG_ 1456 AEB_DispPopupSts 0;
BA_ "GenSigTimeoutTime_EPS" SG_ 1456 AEB_DispPopupSts 0;
BA_ "GenSigTimeoutTime_EVCU2" SG_ 1456 AEB_DispPopupSts 0;
BA_ "GenSigTimeoutTime_ORC" SG_ 1456 AEB_DispPopupSts 0;
BA_ "GenSigSendType" SG_ 1456 ACC_Limit_Fail 3;
BA_ "GenSigTimeoutTime_BSM" SG_ 1456 ACC_Limit_Fail 0;
BA_ "GenSigTimeoutTime_BSM2" SG_ 1456 ACC_Limit_Fail 0;
BA_ "GenSigTimeoutTime_CADM" SG_ 1456 ACC_Limit_Fail 0;
BA_ "GenSigTimeoutTime_CVPAM" SG_ 1456 ACC_Limit_Fail 0;
BA_ "GenSigTimeoutTime_ECM" SG_ 1456 ACC_Limit_Fail 0;
BA_ "GenSigTimeoutTime_EPS" SG_ 1456 ACC_Limit_Fail 0;
BA_ "GenSigTimeoutTime_EVCU2" SG_ 1456 ACC_Limit_Fail 0;
BA_ "GenSigSendType" SG_ 1456 ACC_DispPopupSts 3;
BA_ "GenSigTimeoutTime_BSM" SG_ 1456 ACC_DispPopupSts 0;
BA_ "GenSigTimeoutTime_BSM2" SG_ 1456 ACC_DispPopupSts 0;
BA_ "GenSigTimeoutTime_CADM" SG_ 1456 ACC_DispPopupSts 0;
BA_ "GenSigTimeoutTime_CVPAM" SG_ 1456 ACC_DispPopupSts 0;
BA_ "GenSigTimeoutTime_ECM" SG_ 1456 ACC_DispPopupSts 0;
BA_ "GenSigTimeoutTime_EPS" SG_ 1456 ACC_DispPopupSts 0;
BA_ "GenSigTimeoutTime_EVCU2" SG_ 1456 ACC_DispPopupSts 0;
BA_ "GenSigTimeoutTime_ORC" SG_ 1456 ACC_DispPopupSts 0;
BA_ "GenSigSendType" SG_ 1456 ACC_FailSts 3;
BA_ "GenSigTimeoutTime_BSM2" SG_ 1456 ACC_FailSts 0;
BA_ "GenSigTimeoutTime_CADM" SG_ 1456 ACC_FailSts 0;
BA_ "GenSigTimeoutTime_CVPAM" SG_ 1456 ACC_FailSts 0;
BA_ "GenSigTimeoutTime_ECM" SG_ 1456 ACC_FailSts 0;
BA_ "GenSigTimeoutTime_EPS" SG_ 1456 ACC_FailSts 0;
BA_ "GenSigTimeoutTime_EVCU2" SG_ 1456 ACC_FailSts 0;
BA_ "GenSigSendType" SG_ 1456 ACC_Blind 3;
BA_ "GenSigTimeoutTime_BSM2" SG_ 1456 ACC_Blind 0;
BA_ "GenSigTimeoutTime_CADM" SG_ 1456 ACC_Blind 0;
BA_ "GenSigTimeoutTime_CVPAM" SG_ 1456 ACC_Blind 0;
BA_ "GenSigTimeoutTime_ECM" SG_ 1456 ACC_Blind 0;
BA_ "GenSigTimeoutTime_EPS" SG_ 1456 ACC_Blind 0;
BA_ "GenSigTimeoutTime_EVCU2" SG_ 1456 ACC_Blind 0;
VAL_ 1456 RR_Chime_RqSts 0 "No_rght_rear_chime_on_req" 1 "Right_rear_chime_on_req";
VAL_ 1456 LR_Chime_RqSts 0 "No_left_rear_chime_on_req" 1 "Left_rear_chime_on_req";
VAL_ 1456 Chime_Priority 0 "A" 1 "B" 2 "C" 3 "D" 4 "E";
VAL_ 1456 BSS_SRV_RQSts 0 "No_Service_Request" 1 "Service_Request";
VAL_ 1456 BSS_Blind_RQSts 0 "No_Sensor_Blocked_Request" 1 "Sensor_Blocked_Request";
VAL_ 262 PowertrainPrplsnActv 0 "Off" 1 "Active";
VAL_ 262 LV12PwrFreeRq_W 0 "Level 1 or 2 Power free Mode NOT active" 1 "Level 1 or 2 Power free Mode Active";
VAL_ 262 GasPedalPositionFailSts_W 0 "Fail_not_present" 1 "Fail_present";
VAL_ 262 GasPedalPosition_W 255 "SNA";
VAL_ 262 ESS_ENG_ST_W 1 "ENS Stopped / ENS_STOPPED" 2 "ENS Request Start / ENS_RQ_ST" 3 "ENS Running / ENS_RUN" 4 "ENS Stop Pending / ENS_STOP_PEND" 5 "ENS Start protection / ENS_ST_PRTCT" 6 "ENS Start inhibit / ENS_ST_INH" 7 "ENS disabled / ENS_DSBL" 8 "ENS_IHB_LATCH" 9 "ENS Starting / ENS_Starting" 15 "SNA";
VAL_ 262 EngineSts_W 0 "Engine_Off" 1 "Engine_Cranking" 2 "Engine_On" 3 "SNA";
VAL_ 262 EngineSpeed_W 16383 "SNA";
VAL_ 262 ECM_LHOM_W 0 "Not_In_Limp_Home" 1 "In_Limp_Home";
VAL_ 258 YawRateFailSts_BSM 0 "Fail_Not_Present" 1 "Fail_Present";
VAL_ 258 YawRate_BSM 4095 "SNA";
VAL_ 258 VehicleSpeedVSOSig 8191 "SNA";
VAL_ 258 Slope 255 "SNA";
VAL_ 258 PrefillActive 0 "Not_Active" 1 "Active";
VAL_ 258 LongAccelerationFailSts_BSM 0 "Fail_Not_Present" 1 "Fail_Present";
VAL_ 258 LongAcceleration_BSM 4095 "SNA";
VAL_ 258 LatAccelerationFailSts_BSM 0 "Fail_Not_Present" 1 "Fail_Present";
VAL_ 258 LatAcceleration_BSM 4095 "SNA";
VAL_ 258 InternalError_BSM 0 "No_int_processing_error_detected" 1 "Int_processing_error_detected";
VAL_ 258 ESP_Sys_Stat 0 "ABSERR_DIAG" 1 "NORM" 2 "HALF" 3 "ABGAS";
VAL_ 258 ESCActive 0 "Not_active" 1 "Active";
VAL_ 258 BrakePedalPressure 2047 "SNA";
VAL_ 258 BrakeInterventionSts 0 "No_active_brake_intervention" 1 "Active_brake_intervention";
VAL_ 258 BrakeBoostStat 0 "INIT_Bst" 1 "Normal_Bst" 2 "Limited_Bst" 3 "Shutdown_Bst" 4 "MOCO" 5 "Half_Sys_Bst" 6 "No_Bst" 15 "SNA";
VAL_ 258 BrakeBoostPressure 2047 "SNA";
VAL_ 258 ABSActive 0 "Not_active" 1 "Active";
VAL_ 1456 BSS_CFG_STATSts 0 "Not_enabled" 1 "Enabled_for_LED" 2 "Enabled_for_LED_and_Chime" 3 "SNA";
VAL_ 524 VehicleStandStillSts_B2 0 "True" 1 "False" 3 "SNA";
VAL_ 524 BSM2_OpStat 0 "Inactive" 1 "FullService" 2 "FailOperational" 3 "FailDegraded" 4 "Emergency" 5 "No_Function";
VAL_ 524 Brake_OpStat_Sec 0 "Inactive" 1 "FullService" 2 "FailOperational" 3 "FailDegraded" 4 "Emergency" 5 "No_Function";
VAL_ 257 VehicleSpeedVSOSig_B2 8191 "SNA";
VAL_ 257 RHFWheelSpeed_B2 8191 "SNA";
VAL_ 257 RHF_FastPulseCounter_B2 255 "SNA";
VAL_ 257 LHFWheelSpeed_B2 8191 "SNA";
VAL_ 257 LHF_FastPulseCounter_B2 255 "SNA";
VAL_ 258 WheelRPM_FR 65535 "SNA";
VAL_ 258 WheelRPM_FL 65535 "SNA";
VAL_ 258 Brk_Stat 0 "IDLE" 1 "BRAKING" 2 "NDEF2" 3 "SNA";
VAL_ 1456 SVI_Request 0 "OFF" 1 "Green" 2 "YELLOW" 3 "Red";
VAL_ 1456 Set_Speed_MPH 255 "SNA";
VAL_ 1456 Set_Speed_KPH 255 "SNA";
VAL_ 1456 RF_Chime_RqSts 0 "No_Request" 1 "Request";
VAL_ 1456 PEB_Setting_Avail 0 "Available" 1 "Not_Available";
VAL_ 1456 NCC_FailSts 0 "Fail_Not_Present" 1 "Fail_Present";
VAL_ 1456 LKA_Status 0 "OFF" 1 "ON";
VAL_ 1456 LKA_FailSts 0 "Fail_Not_Present" 1 "Fail_Present";
VAL_ 1456 LKA_Blind 0 "Fail_Not_Present" 1 "Fail_Present";
VAL_ 1456 LF_Chime_RqSts 0 "No_Request" 1 "Request";
VAL_ 1456 Lane_DisplaySts_Right 0 "Off" 1 "Gray" 2 "Green" 3 "Yellow" 4 "Yellow_Flashing" 5 "Red" 6 "Dashed" 7 "White";
VAL_ 1456 Lane_DisplaySts_Left 0 "Off" 1 "Gray" 2 "Green" 3 "Yellow" 4 "Yellow_Flashing" 5 "Red" 6 "Dashed" 7 "White";
VAL_ 1456 ICA_Blind 0 "Blinded" 1 "Not_Blinded";
VAL_ 1456 HAS_TurnSignalRequest 0 "No_Request" 1 "Left" 2 "Right";
VAL_ 1456 HAS_TelltaleSts 0 "OFF" 1 "GREY" 2 "GREEN" 3 "YELLOW" 4 "RED" 5 "GREEN_HANDS_FREE" 6 "YELLOW_HANDS_FREE" 7 "SNA";
VAL_ 1456 HAS_FailSts 0 "Fail_Not_Present" 1 "Fail_Present";
VAL_ 1456 HAS_Escalation_Sts 0 "No_State" 1 "State0" 2 "State1" 3 "State2" 4 "State3a" 5 "State3b" 6 "State4a" 7 "State4b" 8 "State5";
VAL_ 1456 HAS_Blind 0 "Fail_Not_Present" 1 "Fail_Present";
VAL_ 1456 FCW_Setting_Avail 0 "Available" 1 "Not_Available";
VAL_ 1456 DisplaySts_Veh 0 "Off" 1 "Center_White" 2 "Center_Green" 3 "Right_Crossing_1" 4 "Left_Crossing_1" 5 "Right_Crossing_2" 6 "Left_Crossing_2";
VAL_ 1456 DisplaySts_OFF 0 "No_Code" 1 "ACC_LKA_HAS" 2 "ACC_LKA" 3 "ACC_HAS" 4 "ACC" 5 "LKA";
VAL_ 1456 DisplaySts_Curve 0 "No_Req" 1 "Left" 2 "Right";
VAL_ 1456 DisplaySts_ACC 0 "Off" 1 "Ready_TG1" 2 "Ready_TG2" 3 "Ready_TG3" 4 "Ready_TG4" 5 "ACC_E_NT_TG1" 6 "ACC_E_NT_TG2" 7 "ACC_E_NT_TG3" 8 "ACC_E_NT_TG4" 9 "ACC_E_WT_TG1" 10 "ACC_E_WT_TG2" 11 "ACC_E_WT_TG3" 12 "ACC_E_WT_TG4" 13 "NCC_Ready" 14 "NCC_Engaged";
VAL_ 1456 DDD_FailSts 0 "Fail_Not_Present" 1 "Fail_Present";
VAL_ 1456 DDD_DispPopupSts 0 "No_Code" 1 "Drowsniness_Detected" 2 "DDD_Perm_Fail" 3 "SNA";
VAL_ 1456 Chime_TypSts 0 "Default" 1 "Chime 1" 2 "Chime 2" 3 "Chime 3" 4 "Chime 4" 5 "Chime 5" 6 "Chime 6" 7 "Chime 7" 8 "Chime 8" 9 "Chime 9" 10 "Chime 10";
VAL_ 1456 BlindSpotRightWarn 0 "No_Req" 1 "Solid" 2 "Flashing";
VAL_ 1456 BlindSpotLeftWarn 0 "No_Req" 1 "Solid" 2 "Flashing";
VAL_ 1456 AEB_Limited 0 "Fail_Not_Present" 1 "Fail_Present";
VAL_ 1456 AEB_Limit_Fail 0 "Fail_Not_Present" 1 "Fail_Present";
VAL_ 1456 AEB_FailSts 0 "Fail_Not_Present" 1 "Fail_Present";
VAL_ 1456 AEB_DispPopupSts 0 "No_Code" 1 "Pre_Intervention_Warning" 4 "Braking_Complete" 5 "AEB_Unavailble_ESC_Off" 6 "AEB_Unavailble_4WD_Low" 7 "Active_Braking_Enabled" 8 "Active_Braking_Disabled" 9 "AEB_User_Disabled" 10 "AEB_Radar_Blind" 11 "Pre_Intervention_Warning_VRU_L" 12 "AEB_Fail" 13 "Pre_Intervention_Warning_VRU_R" 14 "AEB_Cam_Blind" 15 "Not_used3" 16 "AEB_LIMITED_Fail" 17 "PEB_Off" 18 "PEB_On" 19 "PEB_Radar_Blind" 20 "PEB_Fail" 21 "PEB_Cam_Blind" 22 "FCW_Limited_PEB_Off_Camera_Blinded" 23 "FCW_Limited_PEB_Off_Camera_Fail" 24 "Pre_Intervention_Warning_ICA_L" 25 "Pre_Intervention_Warning_ICA_R" 26 "AEB_Limit_Corner_Blind" 27 "AEB_Unavail_Corsa" 28 "AEB_Unavail_Off_Road" 29 "AEB_Cancel_ESC_Off" 30 "AEB_Cancel_Off_Road" 31 "AEB_Unavail_HDC" 32 "AEB_Initializing_Phase_Ongoing";
VAL_ 1456 AEB_Blind 0 "Fail_Not_Present" 1 "Fail_Present";
VAL_ 1456 ACC_Set_Speed_Strike 0 "Not_Present" 1 "Present";
VAL_ 1456 ACC_Limited 0 "Fail_Not_Present" 1 "Fail_Present";
VAL_ 1456 ACC_Limit_Fail 0 "Fail_Not_Present" 1 "Fail_Present";
VAL_ 1456 ACC_FailSts 0 "Fail_Not_Present" 1 "Fail_Present";
VAL_ 1456 ACC_DispPopupSts 0 "No_Code" 1 "ACC_Unavailable" 2 "ACC_Unavailable_4WD_Low" 3 "ACC_Unavailable_ESC_Off" 4 "ACC_Unavailable_ESC_Event" 5 "ACC_Unavailable_Brakes_Cooling" 6 "ACC_Unavailable_Below_Min_Speed" 7 "ACC_Unavailable_Above_Max_Speed" 8 "ACC_Unavailable_EPB_Active" 9 "ACC_Unavailable_Shift_D" 10 "ACC_Unavailable_Door_Open" 11 "ACC_Unavailable_Seatbelt_Unbuckled" 12 "ACC_Unavailable_Road_to_Steep" 13 "ACC_Unavailable_Wrong_Gear" 14 "ACC_Unavailable_Low_RPM" 15 "ACC_Unavailable_High_RPM" 16 "ACC_Unavailable_Clutch_Engaged" 17 "ACC_Cancel" 18 "ACC_AEB_Cancel_ESC_Off" 19 "ACC_Cancel_ESC_Off" 20 "ACC_Cancel_ESC_Event" 21 "ACC_Cancel_Brakes_Cooling" 22 "ACC_Cancel_Below_Min_Speed" 23 "ACC_Cancel_Above_Max_Speed" 24 "ACC_Cancel_EPB_Active" 25 "ACC_Cancel_Shift_D" 26 "ACC_Cancel_Door_Open" 27 "ACC_Cancel_Seatbelt_Unbuckled" 28 "ACC_Cancel_Road_to_Steep" 29 "ACC_Cancel_Wrong_gear" 30 "ACC_Cancel_Low_RPM" 31 "ACC_Cancel_High_RPM" 32 "ACC_Stop_Vehicle_Object_Detected" 33 "ACC_Warning_Clutch_Engaged" 34 "ACC_Warning_Neutral_Engaged" 35 "ACC_Off_ESC_Fault" 36 "ACC_Proximity_Warning" 37 "NCC_Unavailable" 38 "NCC_Unavailable_4WD_Low" 39 "NCC_Unavailable_ESC_Off" 40 "NCC_Unavailable_ESC_Event" 41 "NCC_Unavailable_Brakes_Cooling" 42 "NCC_Unavailable_Below_Min_Speed" 43 "NCC_Unavailable_Above_Max_Speed" 44 "NCC_Unavailable_EPB_Active" 45 "NCC_Unavailable_Shift_D" 46 "NCC_Unavailable_Wrong_Gear" 47 "NCC_Unavailable_Low_RPM" 48 "NCC_Unavailable_High_RPM" 49 "NCC_Unavailable_Clutch_Engaged" 50 "NCC_Cancel" 51 "NCC_AEB_Cancel_ESC_Off" 52 "NCC_Cancel_ESC_Off" 53 "NCC_Cancel_ESC_Event" 54 "NCC_Cancel_Brakes_Cooling" 55 "NCC_Cancel_Below_Min_Speed" 56 "NCC_Cancel_Above_Max_Speed" 57 "NCC_Cancel_EPB_Active" 58 "NCC_Cancel_Shift_D" 59 "NCC_Cancel_Wrong_Gear" 60 "NCC_Cancel_Low_RPM" 61 "NCC_Cancel_High_RPM" 62 "NCC_Warning_Clutch_Engaged" 63 "NCC_Warning_Neutral_Engaged" 64 "ACC_User_Enabled" 68 "ACC_Set" 76 "ACC_Override" 77 "ACC_User_Disabled" 78 "NCC_User_Enabled" 79 "NCC_Set" 80 "NCC_User_Disbaled" 81 "NCC_Override" 82 "Front_Radar_Sensor_Plant_Mode" 83 "ACC_AEB_LKA_Cam_Blind" 84 "ACC_AEB_Cam_Blind" 85 "ACC_LKA_Cam_Blind" 86 "ACC_Cam_Blind" 87 "ACC_AEB_LKA_LIMITED_Fail" 88 "ACC_AEB_LIMITED_Fail" 89 "ACC_LKA_LIMITED_Fail" 90 "ACC_LIMITED_Fail" 91 "ACC_AEB_Radar_Blind" 92 "ACC_Radar_Blind" 93 "ACC_AEB_LKA_Fail" 94 "ACC_AEB_Fail" 95 "ACC_LKA_Fail" 96 "ACC_Fail" 97 "NCC_AEB_LKA_Fail" 98 "NCC_AEB_Fail" 99 "NCC_LKA_Fail" 100 "NCC_Fail" 101 "Alignment_Mode" 102 "Misaligned_Radar" 103 "ACC_Unavail_Corsa" 104 "NCC_Unavail_Corsa" 105 "ACC_Unavailable_Off_Road" 106 "NCC_Unavailable_Off_Road" 107 "ACC_Resume_Reminder" 108 "ACC_Cancel_Off_Road" 109 "ACC_Unavail_HDC" 110 "NCC_Unavail_HDC" 111 "ACC_AEB_Cancel_Off_Road" 112 "Stopping_Ahead" 113 "Press_xx_Confirm_To_Pass" 114 "ACC_Unavailable_Race" 115 "Manual_Confirmation" 116 "Auto_Confirmation" 117 "RES_or_Accel_Pdl_to_Continue_Moving" 118 "Vehicle_Not_Stop_Completely" 119 "Vehicle_Unable_To_Stop_At_Traffic_Light" 120 "Be_Prepared_to_Stop_Ahead" 121 "RES_or_Accel_Pdl_to_Bypass_Upcoming_stop" 122 "Change_Lane_to_Follow_Route" 123 "Route_Lane_Guidence_Aborted" 124 "ACC_Limited" 125 "IACC_NOT_AVAILABLE_TSR_NOT_AVAILABLE" 126 "IACC_NOT_AVAIL_SPEED_TOO_HIGH" 127 "IACC_NOT_AVAIL_SPEED_TOO_LOW";
VAL_ 1456 ACC_Blind 0 "Fail_Not_Present" 1 "Fail_Present";
VAL_ 258 ParkingGearShiftReq_BSM 0 "Idle" 1 "P" 2 "R" 3 "N" 4 "D" 7 "SNA";
VAL_ 524 BrkTrq_B2 32767 "SNA";
VAL_ 257 RHF_WheelSensorFailSts_B2 0 "Fail_Not_Present" 1 "Fail_Present";
VAL_ 257 RHF_Spin_B2 0 "Stand_Still" 1 "Forward" 2 "Backward" 3 "SNA";
VAL_ 257 LHF_WheelSensorFailSts_B2 0 "Fail_Not_Present" 1 "Fail_Present";
VAL_ 257 LHF_Spin_B2 0 "Stand_Still" 1 "Forward" 2 "Backward" 3 "SNA";
VAL_ 257 Inlet_Pressure_Pos 0 "False" 1 "True" 3 "SNA";
VAL_ 257 Brk_Stat_B2 0 "IDLE" 1 "BRAKING" 2 "NDEF2" 3 "SNA";
VAL_ 257 ABSActive_B2 0 "Not_active" 1 "Active";
VAL_ 1456 Driver_Model 0 "Attention_Unknown" 1 "Attention_Criteria_Met" 2 "Attention_Criteria_Not_Met" 3 "Faulted";
VAL_ 258 ParkingInterventionSts 0 "Not_Active" 1 "Active" 2 "Faulted_External" 3 "Faulted_Internal";
VAL_ 524 AEB_Type_Brk_B2 0 "NONE" 1 "ACC" 2 "CMS" 3 "CMS_XTD" 4 "ABA" 5 "LSCM" 6 "PEB" 7 "ICA_L" 8 "ICA_R" 9 "HAS_MRM" 15 "SNA";
VAL_ 2654486529 CBV_bit0_RepeatMessageRequestBit_1E384001 0 "Repeat_Message_State_not_requested" 1 "Repeat_Message_State_requested";
VAL_ 2654486529 CBV_bit3_NMCoordinatorBit_1E384001 0 "Start_of_synchronized_shutdown_is_not_requested_by_main_coordinator" 1 "Start_of_synchronized_shutdown_is_requested_by_main_coordinator";
VAL_ 2654486529 CBV_bit4_ActiveWakeupBit_1E384001 0 "PassiveWakeup" 1 "ActiveWakeup";
VAL_ 2654486529 CBV_bit6_PartialNtwInfBit_1E384001 0 "NM_PDU_contains_no_Partial_Network_request_information" 1 "NM_PDU_contains_Partial_Network_request_information";
VAL_ 2654486669 CBV_bit3_NMCoordinatorBit_1E38408D 0 "Start_of_synchronized_shutdown_is_not_requested_by_main_coordinator" 1 "Start_of_synchronized_shutdown_is_requested_by_main_coordinator";
VAL_ 2654486669 CBV_bit4_ActiveWakeupBit_1E38408D 0 "PassiveWakeup" 1 "ActiveWakeup";
VAL_ 2654486669 CBV_bit6_PartialNtwInfBit_1E38408D 0 "NM_PDU_contains_no_Partial_Network_request_information" 1 "NM_PDU_contains_Partial_Network_request_information";
VAL_ 2654486669 CBV_bit0_RepeatMessageRequestBit_1E38408D 0 "Repeat_Message_State_not_requested" 1 "Repeat_Message_State_requested";
VAL_ 2654486534 CBV_bit0_RepeatMessageRequestBit_1E384006 0 "Repeat_Message_State_not_requested" 1 "Repeat_Message_State_requested";
VAL_ 2654486534 CBV_bit3_NMCoordinatorBit_1E384006 0 "Start_of_synchronized_shutdown_is_not_requested_by_main_coordinator" 1 "Start_of_synchronized_shutdown_is_requested_by_main_coordinator";
VAL_ 2654486534 CBV_bit4_ActiveWakeupBit_1E384006 0 "PassiveWakeup" 1 "ActiveWakeup";
VAL_ 2654486534 CBV_bit6_PartialNtwInfBit_1E384006 0 "NM_PDU_contains_no_Partial_Network_request_information" 1 "NM_PDU_contains_Partial_Network_request_information";
VAL_ 257 Rear_Diff_BSM_RQ_B2 0 "FREE" 1 "HOLD" 2 "OPEN" 3 "SNA";
VAL_ 257 R_DIFF_TRQ_RQ_B2 511 "SNA";
VAL_ 257 Ft_RrTrqCoupling_ModeRq_B2 0 "FREE" 1 "HOLD" 2 "OPEN" 3 "SNA";
VAL_ 257 Ft_RrAxleCoupling_TrqRq_B2 255 "SNA";
VAL_ 1456 Lane_DispPopupSts 0 "No_Code" 1 "LKA_On" 2 "LKA_Off" 3 "LKA_Hands_Off" 4 "HAS_Eyes_Off_Yellow" 5 "Take_Control_Red" 6 "HAS_Ready_Highway" 7 "Blind_Spot_OFF" 8 "HAS_Ready_ACC_Set" 9 "HAS_Unavailable_Speed_to_High" 10 "HAS_Unavailable_Trailer" 11 "HAS_Unavailable_TempNAP" 12 "HAS_Cancel_FOW" 13 "HAS_Cancel_Lane" 15 "HAS_Cancel_Curve" 16 "Unsupport_Lane_Ahead_Take_Control" 17 "MRM_In_Prog" 18 "MRM_Complete" 19 "HAS_Unavail_Lane" 20 "HAS_Hands_Off_Yellow" 21 "HAS_Hands_Off_Red" 22 "HAS_Cancel_Hands_Off" 23 "HAS_AEB_LKA_Cam_Blind" 24 "HAS_AEB_Cam_Blind" 25 "HAS_LKA_Cam_Blind" 26 "HAS_Cam_Blind" 27 "LKA_AEB_Cam_Blind" 28 "LKA_Cam_Blind" 29 "HAS_AEB_Radar_Blind" 30 "HAS_Radar_Blind" 31 "HAS_AEB_LKA_LIMITED_Fail" 32 "HAS_AEB_LIMITED_Fail" 33 "LKA_AEB_LIMITED_Fail" 34 "HAS_AEB_LKA_Fail" 35 "HAS_AEB_Fail" 36 "HAS_LKA_Fail" 37 "HAS_Fail" 38 "LKA_AEB_Fail" 39 "LKA_Fail" 40 "HAS_Cancel" 42 "HAS_ON" 43 "HAS_OFF" 44 "BSS_Blind_ALM_On" 45 "BSS_Blind_ALM_Off" 46 "BSS_OPR_ALM_Off" 47 "BSS_OPR_ALM_On" 48 "BSS_SRV_ALM_Off" 49 "BSS_SRV_ALM_On" 50 "HAS_Unavail_Road_Data" 51 "HAS_Unavail_No_Eyes_On" 52 "HAS_Unavail_Map_OOD" 53 "HAS_Unavail_Locked_Out" 54 "HAS_Cancel_Road_Data" 55 "HAS_Cancel_Driver_Not_Attent" 56 "HAS_Cancel_Brake_Event" 57 "HAS_Cancel_Speed_Too_High" 58 "HAS_Cancel_Control_Limit" 59 "HAS_ACC_Unavailable_4WD_Low" 60 "HAS_ACC_Unavailable_ESC_Off" 61 "HAS_ACC_Unavailable_ESC_Event" 62 "HAS_ACC_Unavailable_Brakes_Cooling" 63 "HAS_ACC_Unavailable_EPB_Active" 64 "HAS_ACC_Unavailable_Shift_D" 65 "HAS_ACC_Unavailable_Door_Open" 66 "HAS_ACC_Unavailable_Seatbelt_Unbuckled" 67 "HAS_ACC_Unavailable_Road_to_Steep" 68 "HAS_ACC_Unavailable_Low_RPM" 69 "HAS_ACC_Unavailable_High_RPM" 70 "HAS_ACC_Cancel" 71 "HAS_ACC_AEB_Cancel_ESC_Off" 72 "HAS_ACC_Cancel_ESC_Off" 73 "HAS_ACC_Cancel_ESC_Event" 74 "HAS_ACC_Cancel_Brakes_Cooling" 75 "HAS_ACC_Cancel_EPB_Active" 76 "HAS_ACC_Cancel_Shift_D" 77 "HAS_ACC_Cancel_Door_Open" 78 "HAS_ACC_Cancel_Seatbelt_Unbuckled" 79 "HAS_ACC_Cancel_Road_to_Steep" 80 "HAS_ACC_Cancel_Low_RPM" 81 "HAS_ACC_Cancel_High_RPM" 82 "HAS_ACC_Stop_Vehicle_Object_Detected" 83 "HAS_ACC_User_Enabled" 84 "HAS_ACC_Set" 85 "LKA_Off_Check" 86 "HAS_Curve_Too_Tight" 87 "HAS_Lane_Split" 88 "HAS_On_Reminder" 89 "HAS_ACC_Unavail_Corsa" 90 "LKA_Unavail_Corsa" 91 "HAS_ACC_Unavailable_Off_Road" 92 "BSS_Unavail_Corsa" 93 "BSS_Trailer_On" 94 "BSS_Trailer_Max" 95 "ADAS_Unavailable_Snow_Plow_Detected" 96 "HF_ADA_Set" 97 "Ready_No_Road_HF" 98 "Adjust_Seat_State_2" 99 "Drowsy_State_2" 100 "HF_To_HO_Generic" 101 "HF_To_HO_Hwy_Ending" 102 "HF_Cancel_Not_Attentive" 103 "DA_Set_HF_Service" 104 "Stay_In_Lane" 105 "ALM_Unavail_ESC_Off" 106 "ALM_Off_ESC_Off" 107 "HAS_ACC_Unavail_HDC" 108 "HAS_ACC_AEB_Cancel_Off_Road" 109 "HAS_ACC_Cancel_Off_Road" 110 "HAS_Only_Fail" 111 "HAS_Only_ALM_Fail" 112 "MRM_Complete_Shift_P" 113 "HAS_Eyes_Off_Red" 114 "LKA_Cancel_Hands_Off" 115 "Change_Lane_To_Follow_the_Route" 116 "Route_Lane_Guidance_Aborted_Chime" 117 "Route_Lane_Guidance_Aborted_No_Chime" 118 "HAS_Unavailable_Race" 119 "EmrgCorrAssist_AvailContry" 120 "EmrgCorrAssist_UnavailContry" 121 "EmrgCorrAssist_Active?" 122 "EmrgCorrAssist_Unavail?" 123 "EmrgCorrAssist_Off" 124 "ScText_Srch_opening" 125 "ScText_SpdSlow_MnLChgReq" 126 "LnUnavail_MnLChgReq" 127 "MnLChgReq" 128 "OpNotFnd_MnLChgReq" 129 "ADA_Cancel_JuncAhead" 130 "SpeedOverMax_for_ADA" 131 "SteerReq_Junction_Ahead" 132 "No_ADA_JunctionDetected" 133 "No_ADA_VulnerableUserDet" 134 "HandsOnWheel_JuncAhead" 135 "DriNotVisPlcHndsOnStrngWhl" 136 "ADA_CANCELLED_INCOMPATIBLE_TRAILER" 137 "ADA_UNAVAIL_INCOMPATIBLE_TRAILER" 138 "ADA_ACC_Limited_NO_HandsFree";
VAL_ 258 BSM_ESASystemSts 0 "Not_Enabled" 1 "Pending" 2 "Pre_Active" 3 "Active" 4 "Locked" 5 "Temporarily_Not_Avail" 6 "Permanently_Not_Avail" 7 "SNA";
VAL_ 2654486552 CBV_bit0_RepeatMessageRequestBit_1E384018 0 "Repeat_Message_State_not_requested" 1 "Repeat_Message_State_requested";
VAL_ 2654486552 CBV_bit3_NMCoordinatorBit_1E384018 0 "Start_of_synchronized_shutdown_is_not_requested_by_main_coordinator" 1 "Start_of_synchronized_shutdown_is_requested_by_main_coordinator";
VAL_ 2654486552 CBV_bit4_ActiveWakeupBit_1E384018 0 "PassiveWakeup" 1 "ActiveWakeup";
VAL_ 2654486552 CBV_bit6_PartialNtwInfBit_1E384018 0 "NM_PDU_contains_no_Partial_Network_request_information" 1 "NM_PDU_contains_Partial_Network_request_information";
VAL_ 2654486530 CBV_bit0_RepeatMessageRequestBit_1E384002 0 "Repeat_Message_State_not_requested" 1 "Repeat_Message_State_requested";
VAL_ 2654486530 CBV_bit3_NMCoordinatorBit_1E384002 0 "Start_of_synchronized_shutdown_is_not_requested_by_main_coordinator" 1 "Start_of_synchronized_shutdown_is_requested_by_main_coordinator";
VAL_ 2654486530 CBV_bit4_ActiveWakeupBit_1E384002 0 "PassiveWakeup" 1 "ActiveWakeup";
VAL_ 2654486530 CBV_bit6_PartialNtwInfBit_1E384002 0 "NM_PDU_contains_no_Partial_Network_request_information" 1 "NM_PDU_contains_Partial_Network_request_information";
VAL_ 2654486676 CBV_bit0_RepeatMessageRequestBit_1E384094 0 "Repeat_Message_State_not_requested" 1 "Repeat_Message_State_requested";
VAL_ 2654486676 CBV_bit3_NMCoordinatorBit_1E384094 0 "Start_of_synchronized_shutdown_is_not_requested_by_main_coordinator" 1 "Start_of_synchronized_shutdown_is_requested_by_main_coordinator";
VAL_ 2654486676 CBV_bit4_ActiveWakeupBit_1E384094 0 "PassiveWakeup" 1 "ActiveWakeup";
VAL_ 2654486676 CBV_bit6_PartialNtwInfBit_1E384094 0 "NM_PDU_contains_no_Partial_Network_request_information" 1 "NM_PDU_contains_Partial_Network_request_information";
VAL_ 1456 SVI_Request_ext 0 "OFF" 1 "Green" 2 "YELLOW" 3 "Red" 4 "Blue";
VAL_ 1456 DM_Camera_Block 0 "Fail_Not_Present" 1 "Fail_Present";
VAL_ 1456 HAS_TelltaleSts_ext 0 "RED_HANDS_FREE" 7 "SNA";
VAL_ 1456 DisplaySts_Route 0 "Route_Roundabout" 1 "Route_Highway_Exit" 2 "Route_Grade_Intersection" 3 "Route_Trafic_Light" 4 "Route_T_Intersection";
SIG_GROUP_ 1456 ADAS_FD_HMI_Pkt 1 : RR_Chime_RqSts MessageCounter_ADAS_FD_HMI LR_Chime_RqSts CRC_ADAS_FD_HMI Chime_Priority BSS_SRV_RQSts BSS_Blind_RQSts BSS_CFG_STATSts SVI_Request Set_Speed_MPH Set_Speed_KPH RF_Chime_RqSts PEB_Setting_Avail NCC_FailSts LKA_Status LKA_FailSts LKA_Blind LF_Chime_RqSts Lane_DisplaySts_Right Lane_DisplaySts_Left ICA_Blind HAS_TurnSignalRequest HAS_TelltaleSts HAS_FailSts HAS_Escalation_Sts HAS_Blind FCW_Setting_Avail DisplaySts_Veh DisplaySts_OFF DisplaySts_Curve DisplaySts_ACC DDD_FailSts DDD_DispPopupSts Chime_TypSts Chime_RepRate BlindSpotRightWarn BlindSpotLeftWarn AEB_Limited AEB_Limit_Fail AEB_FailSts AEB_DispPopupSts AEB_Blind ACC_Set_Speed_Strike ACC_Limited ACC_Limit_Fail ACC_FailSts ACC_DispPopupSts ACC_Blind Driver_Model Lane_DispPopupSts SVI_Request_ext DM_Camera_Block HAS_TelltaleSts_ext DisplaySts_Route;
SIG_GROUP_ 262 ENGINE_FD_2_Pkt 1 : PowertrainPrplsnActv MessageCounter_ENGINE2 LV12PwrFreeRq_W GasPedalPositionFailSts_W GasPedalPosition_W ESS_ENG_ST_W EngineSts_W EngineSpeed_W ECM_LHOM_W CRC_ENGINE2;
SIG_GROUP_ 258 BRAKE_FD_2_Pkt 1 : YawRateFailSts_BSM YawRate_BSM VehicleSpeedVSOSig Slope PrefillActive MessageCounter_BRAKE2 LongAccelerationFailSts_BSM LongAcceleration_BSM LatAccelerationFailSts_BSM LatAcceleration_BSM InternalError_BSM ESP_Sys_Stat ESCActive CRC_BRAKE2 BrakePedalPressure BrakeInterventionSts BrakeBoostStat BrakeBoostPressure ABSActive WheelRPM_FR WheelRPM_FL Brk_Stat ParkingGearShiftReq_BSM ParkingInterventionSts BSM_ESASystemSts;
SIG_GROUP_ 524 BRAKE2_FD_2_Pkt 1 : VehicleStandStillSts_B2 BSM2_OpStat Brake_OpStat_Sec MessageCounter_BRAKE2_2 CRC_BRAKE2_2 BrkTrq_B2 BSM2_HEALTH_CHECK AEB_Type_Brk_B2;
SIG_GROUP_ 257 BRAKE2_FD_1_Pkt 1 : VehicleSpeedVSOSig_B2 RHFWheelSpeed_B2 RHF_FastPulseCounter_B2 LHFWheelSpeed_B2 LHF_FastPulseCounter_B2 RHF_WheelSensorFailSts_B2 RHF_Spin_B2 MessageCounter_BRAKE2_1 LHF_WheelSensorFailSts_B2 LHF_Spin_B2 Inlet_Pressure_Pos CRC_BRAKE2_1 Brk_Stat_B2 ABSActive_B2 Rear_Diff_BSM_RQ_B2 R_DIFF_TRQ_RQ_B2 Ft_RrTrqCoupling_ModeRq_B2 Ft_RrAxleCoupling_TrqRq_B2;
